[part 5 of 5: package /MICROSAR/Dem_swc/ComponentTypes]
AUTOSAR XML (schema 4-2-1)
package /MICROSAR/Dem_swc/ComponentTypes  (continued)
  service sw component type DemSatellite_OsApplication_Untrusted_Core0: category=SERVICE_COMPONENT  (continued)
    behavior DemSatellite_OsApplication_Untrusted_Core0InternalBehavior: handle-termination-and-restart=NO-SUPPORT, included-data-type-set=data-type=[Dem_EventIdType, Dem_RatioIdType, Dem_EventStatusType, Dem_UdsStatusByteType, Dem_DTCFormatType, Dem_InitMonitorReasonType, Dem_OperationCycleStateType, Dem_DTCStatusMaskType, Dem_IndicatorStatusType, Dem_MaxDataValueType, Dem_DTCKindType, Dem_DTCGroupType, Dem_IumprDenomCondIdType, Dem_IumprDenomCondStatusType, Dem_DebounceResetStatusType, Dem_DebouncingStateType, Dem_IumprReadinessGroupType, Dem_DTRControlType, Dem_DTCSeverityType, Dem_MonitorStatusType]  (continued)
      2354 x operation invoked event:  (continued)
        OpEventGetDebouncingOfEvent_GetDebouncingOfEvent_EvtInfo_AutoCreatedDemEvent_ESH_Action_ComMAllow_CN_LIN04_2bb463c6_Bsw_46c98e12: start-on-event=DemSatellite_OsApplication_Untrusted_Core0InternalBehavior/GetDebouncingOfEvent, operation=EvtInfo_AutoCreatedDemEvent_ESH_Action_ComMAllow_CN_LIN04_2bb463c6_BswMReportFailToDemRef.GetDebouncingOfEvent
        OpEventGetDebouncingOfEvent_GetDebouncingOfEvent_EvtInfo_AutoCreatedDemEvent_ESH_Action_ComMAllow_CN_LIN04_2bb463c6_Bsw_5fd0cb63: start-on-event=DemSatellite_OsApplication_Untrusted_Core0InternalBehavior/GetDebouncingOfEvent, operation=EvtInfo_AutoCreatedDemEvent_ESH_Action_ComMAllow_CN_LIN04_2bb463c6_BswMReportFailToDemRef_1.GetDebouncingOfEvent
        OpEventGetDebouncingOfEvent_GetDebouncingOfEvent_EvtInfo_AutoCreatedDemEvent_ESH_Action_ComMAllow_CN_SecuritySubnet_e7a_5c59b770: start-on-event=DemSatellite_OsApplication_Untrusted_Core0InternalBehavior/GetDebouncingOfEvent, operation=EvtInfo_AutoCreatedDemEvent_ESH_Action_ComMAllow_CN_SecuritySubnet_e7a0ee54_BswMReportFailToDemRef.GetDebouncingOfEvent
        OpEventGetDebouncingOfEvent_GetDebouncingOfEvent_EvtInfo_AutoCreatedDemEvent_ESH_Action_ComMAllow_CN_SecuritySubnet_e7a_571e50de: start-on-event=DemSatellite_OsApplication_Untrusted_Core0InternalBehavior/GetDebouncingOfEvent, operation=EvtInfo_AutoCreatedDemEvent_ESH_Action_ComMAllow_CN_SecuritySubnet_e7a0ee54_BswMReportFailToDemRef_1.GetDebouncingOfEvent
        OpEventGetDebouncingOfEvent_GetDebouncingOfEvent_EvtInfo_AutoCreatedDemEvent_ESH_Action_ComMCheckPendingRequests_BswMRe_1e2bc029: start-on-event=DemSatellite_OsApplication_Untrusted_Core0InternalBehavior/GetDebouncingOfEvent, operation=EvtInfo_AutoCreatedDemEvent_ESH_Action_ComMCheckPendingRequests_BswMReportFailToDemRef_1.GetDebouncingOfEvent
        OpEventGetDebouncingOfEvent_GetDebouncingOfEvent_EvtInfo_AutoCreatedDemEvent_ESH_Action_ComMCheckPendingRequests_BswMRe_87229193: start-on-event=DemSatellite_OsApplication_Untrusted_Core0InternalBehavior/GetDebouncingOfEvent, operation=EvtInfo_AutoCreatedDemEvent_ESH_Action_ComMCheckPendingRequests_BswMReportFailToDemRef_2.GetDebouncingOfEvent
        OpEventGetDebouncingOfEvent_GetDebouncingOfEvent_EvtInfo_AutoCreatedDemEvent_ESH_Action_ComMDisallow_CN_Backbone1J1939_2d2aa7ff: start-on-event=DemSatellite_OsApplication_Untrusted_Core0InternalBehavior/GetDebouncingOfEvent, operation=EvtInfo_AutoCreatedDemEvent_ESH_Action_ComMDisallow_CN_Backbone1J1939_0b1f4bae_BswMReportFailToDemRef.GetDebouncingOfEvent
        OpEventGetDebouncingOfEvent_GetDebouncingOfEvent_EvtInfo_AutoCreatedDemEvent_ESH_Action_ComMDisallow_CN_Backbone2_78967_78b51993: start-on-event=DemSatellite_OsApplication_Untrusted_Core0InternalBehavior/GetDebouncingOfEvent, operation=EvtInfo_AutoCreatedDemEvent_ESH_Action_ComMDisallow_CN_Backbone2_78967e2c_BswMReportFailToDemRef.GetDebouncingOfEvent
        OpEventGetDebouncingOfEvent_GetDebouncingOfEvent_EvtInfo_AutoCreatedDemEvent_ESH_Action_ComMDisallow_CN_CabSubnet_9ea69_a5772fe5: start-on-event=DemSatellite_OsApplication_Untrusted_Core0InternalBehavior/GetDebouncingOfEvent, operation=EvtInfo_AutoCreatedDemEvent_ESH_Action_ComMDisallow_CN_CabSubnet_9ea693f1_BswMReportFailToDemRef.GetDebouncingOfEvent
        OpEventGetDebouncingOfEvent_GetDebouncingOfEvent_EvtInfo_AutoCreatedDemEvent_ESH_Action_ComMDisallow_CN_FMSNet_fce1aae5_14cbd03a: start-on-event=DemSatellite_OsApplication_Untrusted_Core0InternalBehavior/GetDebouncingOfEvent, operation=EvtInfo_AutoCreatedDemEvent_ESH_Action_ComMDisallow_CN_FMSNet_fce1aae5_BswMReportFailToDemRef.GetDebouncingOfEvent
        OpEventGetDebouncingOfEvent_GetDebouncingOfEvent_EvtInfo_AutoCreatedDemEvent_ESH_Action_ComMDisallow_CN_LIN00_2cd9a7df_fbfb2a86: start-on-event=DemSatellite_OsApplication_Untrusted_Core0InternalBehavior/GetDebouncingOfEvent, operation=EvtInfo_AutoCreatedDemEvent_ESH_Action_ComMDisallow_CN_LIN00_2cd9a7df_BswMReportFailToDemRef.GetDebouncingOfEvent
        OpEventGetDebouncingOfEvent_GetDebouncingOfEvent_EvtInfo_AutoCreatedDemEvent_ESH_Action_ComMDisallow_CN_LIN01_5bde9749_c34bad5a: start-on-event=DemSatellite_OsApplication_Untrusted_Core0InternalBehavior/GetDebouncingOfEvent, operation=EvtInfo_AutoCreatedDemEvent_ESH_Action_ComMDisallow_CN_LIN01_5bde9749_BswMReportFailToDemRef.GetDebouncingOfEvent
        OpEventGetDebouncingOfEvent_GetDebouncingOfEvent_EvtInfo_AutoCreatedDemEvent_ESH_Action_ComMDisallow_CN_LIN02_c2d7c6f3_3e36513e: start-on-event=DemSatellite_OsApplication_Untrusted_Core0InternalBehavior/GetDebouncingOfEvent, operation=EvtInfo_AutoCreatedDemEvent_ESH_Action_ComMDisallow_CN_LIN02_c2d7c6f3_BswMReportFailToDemRef.GetDebouncingOfEvent
        OpEventGetDebouncingOfEvent_GetDebouncingOfEvent_EvtInfo_AutoCreatedDemEvent_ESH_Action_ComMDisallow_CN_LIN03_b5d0f665_ebc2edb4: start-on-event=DemSatellite_OsApplication_Untrusted_Core0InternalBehavior/GetDebouncingOfEvent, operation=EvtInfo_AutoCreatedDemEvent_ESH_Action_ComMDisallow_CN_LIN03_b5d0f665_BswMReportFailToDemRef.GetDebouncingOfEvent
        OpEventGetDebouncingOfEvent_GetDebouncingOfEvent_EvtInfo_AutoCreatedDemEvent_ESH_Action_ComMDisallow_CN_LIN04_2bb463c6_148c1262: start-on-event=DemSatellite_OsApplication_Untrusted_Core0InternalBehavior/GetDebouncingOfEvent, operation=EvtInfo_AutoCreatedDemEvent_ESH_Action_ComMDisallow_CN_LIN04_2bb463c6_BswMReportFailToDemRef.GetDebouncingOfEvent
        OpEventGetDebouncingOfEvent_GetDebouncingOfEvent_EvtInfo_AutoCreatedDemEvent_ESH_Action_ComMDisallow_CN_SecuritySubnet_83a02639: start-on-event=DemSatellite_OsApplication_Untrusted_Core0InternalBehavior/GetDebouncingOfEvent, operation=EvtInfo_AutoCreatedDemEvent_ESH_Action_ComMDisallow_CN_SecuritySubnet_e7a0ee54_BswMReportFailToDemRef.GetDebouncingOfEvent
        OpEventGetDebouncingOfEvent_GetDebouncingOfEvent_EvtInfo_AutoCreatedDemEvent_ESH_Action_DemInit_BswMReportFailToDemRef: start-on-event=DemSatellite_OsApplication_Untrusted_Core0InternalBehavior/GetDebouncingOfEvent, operation=EvtInfo_AutoCreatedDemEvent_ESH_Action_DemInit_BswMReportFailToDemRef.GetDebouncingOfEvent
        OpEventGetDebouncingOfEvent_GetDebouncingOfEvent_EvtInfo_AutoCreatedDemEvent_ESH_Action_DemInitialized_BswMReportFailToDemRef: start-on-event=DemSatellite_OsApplication_Untrusted_Core0InternalBehavior/GetDebouncingOfEvent, operation=EvtInfo_AutoCreatedDemEvent_ESH_Action_DemInitialized_BswMReportFailToDemRef.GetDebouncingOfEvent
        OpEventGetDebouncingOfEvent_GetDebouncingOfEvent_EvtInfo_AutoCreatedDemEvent_ESH_Action_DemNotInitialized_BswMReportFailToDemRef: start-on-event=DemSatellite_OsApplication_Untrusted_Core0InternalBehavior/GetDebouncingOfEvent, operation=EvtInfo_AutoCreatedDemEvent_ESH_Action_DemNotInitialized_BswMReportFailToDemRef.GetDebouncingOfEvent
        OpEventGetDebouncingOfEvent_GetDebouncingOfEvent_EvtInfo_AutoCreatedDemEvent_ESH_Action_DemShutdown_BswMReportFailToDemRef: start-on-event=DemSatellite_OsApplication_Untrusted_Core0InternalBehavior/GetDebouncingOfEvent, operation=EvtInfo_AutoCreatedDemEvent_ESH_Action_DemShutdown_BswMReportFailToDemRef.GetDebouncingOfEvent
        OpEventGetDebouncingOfEvent_GetDebouncingOfEvent_EvtInfo_AutoCreatedDemEvent_ESH_Action_ESH_PostRun_BswMReportFailToDemRef: start-on-event=DemSatellite_OsApplication_Untrusted_Core0InternalBehavior/GetDebouncingOfEvent, operation=EvtInfo_AutoCreatedDemEvent_ESH_Action_ESH_PostRun_BswMReportFailToDemRef.GetDebouncingOfEvent
        OpEventGetDebouncingOfEvent_GetDebouncingOfEvent_EvtInfo_AutoCreatedDemEvent_ESH_Action_ESH_PrepShutdown_BswMReportFailToDemRef: start-on-event=DemSatellite_OsApplication_Untrusted_Core0InternalBehavior/GetDebouncingOfEvent, operation=EvtInfo_AutoCreatedDemEvent_ESH_Action_ESH_PrepShutdown_BswMReportFailToDemRef.GetDebouncingOfEvent
        OpEventGetDebouncingOfEvent_GetDebouncingOfEvent_EvtInfo_AutoCreatedDemEvent_ESH_Action_ESH_PrepShutdown_BswMReportFail_db47bce3: start-on-event=DemSatellite_OsApplication_Untrusted_Core0InternalBehavior/GetDebouncingOfEvent, operation=EvtInfo_AutoCreatedDemEvent_ESH_Action_ESH_PrepShutdown_BswMReportFailToDemRef_1.GetDebouncingOfEvent
        OpEventGetDebouncingOfEvent_GetDebouncingOfEvent_EvtInfo_AutoCreatedDemEvent_ESH_Action_ESH_Run_BswMReportFailToDemRef: start-on-event=DemSatellite_OsApplication_Untrusted_Core0InternalBehavior/GetDebouncingOfEvent, operation=EvtInfo_AutoCreatedDemEvent_ESH_Action_ESH_Run_BswMReportFailToDemRef.GetDebouncingOfEvent
        OpEventGetDebouncingOfEvent_GetDebouncingOfEvent_EvtInfo_AutoCreatedDemEvent_ESH_Action_ESH_Run_BswMReportFailToDemRef_1: start-on-event=DemSatellite_OsApplication_Untrusted_Core0InternalBehavior/GetDebouncingOfEvent, operation=EvtInfo_AutoCreatedDemEvent_ESH_Action_ESH_Run_BswMReportFailToDemRef_1.GetDebouncingOfEvent
        OpEventGetDebouncingOfEvent_GetDebouncingOfEvent_EvtInfo_AutoCreatedDemEvent_ESH_Action_ESH_WaitForNvm_BswMReportFailToDemRef: start-on-event=DemSatellite_OsApplication_Untrusted_Core0InternalBehavior/GetDebouncingOfEvent, operation=EvtInfo_AutoCreatedDemEvent_ESH_Action_ESH_WaitForNvm_BswMReportFailToDemRef.GetDebouncingOfEvent
        OpEventGetDebouncingOfEvent_GetDebouncingOfEvent_EvtInfo_AutoCreatedDemEvent_ESH_Action_ESH_Wakeup_BswMReportFailToDemRef: start-on-event=DemSatellite_OsApplication_Untrusted_Core0InternalBehavior/GetDebouncingOfEvent, operation=EvtInfo_AutoCreatedDemEvent_ESH_Action_ESH_Wakeup_BswMReportFailToDemRef.GetDebouncingOfEvent
        OpEventGetDebouncingOfEvent_GetDebouncingOfEvent_EvtInfo_AutoCreatedDemEvent_ESH_Action_ESH_Wakeup_BswMReportFailToDemRef_1: start-on-event=DemSatellite_OsApplication_Untrusted_Core0InternalBehavior/GetDebouncingOfEvent, operation=EvtInfo_AutoCreatedDemEvent_ESH_Action_ESH_Wakeup_BswMReportFailToDemRef_1.GetDebouncingOfEvent
        OpEventGetDebouncingOfEvent_GetDebouncingOfEvent_EvtInfo_AutoCreatedDemEvent_ESH_Action_EcuMClearValidatedWakeupEvents_f2dc5f13: start-on-event=DemSatellite_OsApplication_Untrusted_Core0InternalBehavior/GetDebouncingOfEvent, operation=EvtInfo_AutoCreatedDemEvent_ESH_Action_EcuMClearValidatedWakeupEvents_BswMReportFailToDemRef.GetDebouncingOfEvent
        OpEventGetDebouncingOfEvent_GetDebouncingOfEvent_EvtInfo_AutoCreatedDemEvent_ESH_Action_EcuMGoToSelectedShutdownTarget_5396efc5: start-on-event=DemSatellite_OsApplication_Untrusted_Core0InternalBehavior/GetDebouncingOfEvent, operation=EvtInfo_AutoCreatedDemEvent_ESH_Action_EcuMGoToSelectedShutdownTarget_BswMReportFailToDemRef.GetDebouncingOfEvent
        OpEventGetDebouncingOfEvent_GetDebouncingOfEvent_EvtInfo_AutoCreatedDemEvent_ESH_Action_EnterExclusiveArea_BswMReportFa_11cb58f1: start-on-event=DemSatellite_OsApplication_Untrusted_Core0InternalBehavior/GetDebouncingOfEvent, operation=EvtInfo_AutoCreatedDemEvent_ESH_Action_EnterExclusiveArea_BswMReportFailToDemRef_1.GetDebouncingOfEvent
        OpEventGetDebouncingOfEvent_GetDebouncingOfEvent_EvtInfo_AutoCreatedDemEvent_ESH_Action_ExitExclusiveArea_BswMReportFailToDemRef: start-on-event=DemSatellite_OsApplication_Untrusted_Core0InternalBehavior/GetDebouncingOfEvent, operation=EvtInfo_AutoCreatedDemEvent_ESH_Action_ExitExclusiveArea_BswMReportFailToDemRef.GetDebouncingOfEvent
        OpEventGetDebouncingOfEvent_GetDebouncingOfEvent_EvtInfo_AutoCreatedDemEvent_ESH_Action_NvMWriteAll_BswMReportFailToDemRef: start-on-event=DemSatellite_OsApplication_Untrusted_Core0InternalBehavior/GetDebouncingOfEvent, operation=EvtInfo_AutoCreatedDemEvent_ESH_Action_NvMWriteAll_BswMReportFailToDemRef.GetDebouncingOfEvent
        OpEventGetDebouncingOfEvent_GetDebouncingOfEvent_EvtInfo_AutoCreatedDemEvent_ESH_Action_OnEnterPostRun_BswMReportFailToDemRef: start-on-event=DemSatellite_OsApplication_Untrusted_Core0InternalBehavior/GetDebouncingOfEvent, operation=EvtInfo_AutoCreatedDemEvent_ESH_Action_OnEnterPostRun_BswMReportFailToDemRef.GetDebouncingOfEvent
        OpEventGetDebouncingOfEvent_GetDebouncingOfEvent_EvtInfo_AutoCreatedDemEvent_ESH_Action_OnEnterPrepShutdown_BswMReportF_d1914dd3: start-on-event=DemSatellite_OsApplication_Untrusted_Core0InternalBehavior/GetDebouncingOfEvent, operation=EvtInfo_AutoCreatedDemEvent_ESH_Action_OnEnterPrepShutdown_BswMReportFailToDemRef.GetDebouncingOfEvent
        OpEventGetDebouncingOfEvent_GetDebouncingOfEvent_EvtInfo_AutoCreatedDemEvent_ESH_Action_OnEnterPrepShutdown_BswMReportF_8f5c293e: start-on-event=DemSatellite_OsApplication_Untrusted_Core0InternalBehavior/GetDebouncingOfEvent, operation=EvtInfo_AutoCreatedDemEvent_ESH_Action_OnEnterPrepShutdown_BswMReportFailToDemRef_1.GetDebouncingOfEvent
        OpEventGetDebouncingOfEvent_GetDebouncingOfEvent_EvtInfo_AutoCreatedDemEvent_ESH_Action_OnEnterRun_BswMReportFailToDemRef: start-on-event=DemSatellite_OsApplication_Untrusted_Core0InternalBehavior/GetDebouncingOfEvent, operation=EvtInfo_AutoCreatedDemEvent_ESH_Action_OnEnterRun_BswMReportFailToDemRef.GetDebouncingOfEvent
        OpEventGetDebouncingOfEvent_GetDebouncingOfEvent_EvtInfo_AutoCreatedDemEvent_ESH_Action_OnEnterRun_BswMReportFailToDemRef_1: start-on-event=DemSatellite_OsApplication_Untrusted_Core0InternalBehavior/GetDebouncingOfEvent, operation=EvtInfo_AutoCreatedDemEvent_ESH_Action_OnEnterRun_BswMReportFailToDemRef_1.GetDebouncingOfEvent
        OpEventGetDebouncingOfEvent_GetDebouncingOfEvent_EvtInfo_AutoCreatedDemEvent_ESH_Action_OnEnterShutdown_BswMReportFailToDemRef: start-on-event=DemSatellite_OsApplication_Untrusted_Core0InternalBehavior/GetDebouncingOfEvent, operation=EvtInfo_AutoCreatedDemEvent_ESH_Action_OnEnterShutdown_BswMReportFailToDemRef.GetDebouncingOfEvent
        OpEventGetDebouncingOfEvent_GetDebouncingOfEvent_EvtInfo_AutoCreatedDemEvent_ESH_Action_OnEnterWaitForNvm_BswMReportFailToDemRef: start-on-event=DemSatellite_OsApplication_Untrusted_Core0InternalBehavior/GetDebouncingOfEvent, operation=EvtInfo_AutoCreatedDemEvent_ESH_Action_OnEnterWaitForNvm_BswMReportFailToDemRef.GetDebouncingOfEvent
        OpEventGetDebouncingOfEvent_GetDebouncingOfEvent_EvtInfo_AutoCreatedDemEvent_ESH_Action_OnEnterWakeup_BswMReportFailToDemRef: start-on-event=DemSatellite_OsApplication_Untrusted_Core0InternalBehavior/GetDebouncingOfEvent, operation=EvtInfo_AutoCreatedDemEvent_ESH_Action_OnEnterWakeup_BswMReportFailToDemRef.GetDebouncingOfEvent
        OpEventGetDebouncingOfEvent_GetDebouncingOfEvent_EvtInfo_AutoCreatedDemEvent_ESH_Action_OnEnterWakeup_BswMReportFailToDemRef_1: start-on-event=DemSatellite_OsApplication_Untrusted_Core0InternalBehavior/GetDebouncingOfEvent, operation=EvtInfo_AutoCreatedDemEvent_ESH_Action_OnEnterWakeup_BswMReportFailToDemRef_1.GetDebouncingOfEvent
        OpEventGetDebouncingOfEvent_GetDebouncingOfEvent_EvtInfo_AutoCreatedDemEvent_ESH_Action_SelfRunRequestTimer_Start_BswMR_aa492484: start-on-event=DemSatellite_OsApplication_Untrusted_Core0InternalBehavior/GetDebouncingOfEvent, operation=EvtInfo_AutoCreatedDemEvent_ESH_Action_SelfRunRequestTimer_Start_BswMReportFailToDemRef.GetDebouncingOfEvent
        OpEventGetDebouncingOfEvent_GetDebouncingOfEvent_EvtInfo_AutoCreatedDemEvent_ESH_Action_SelfRunRequestTimer_Start_BswMR_4ec84089: start-on-event=DemSatellite_OsApplication_Untrusted_Core0InternalBehavior/GetDebouncingOfEvent, operation=EvtInfo_AutoCreatedDemEvent_ESH_Action_SelfRunRequestTimer_Start_BswMReportFailToDemRef_1.GetDebouncingOfEvent
        OpEventGetDebouncingOfEvent_GetDebouncingOfEvent_EvtInfo_AutoCreatedDemEvent_ESH_Action_SwitchPostRun_BswMReportFailToDemRef: start-on-event=DemSatellite_OsApplication_Untrusted_Core0InternalBehavior/GetDebouncingOfEvent, operation=EvtInfo_AutoCreatedDemEvent_ESH_Action_SwitchPostRun_BswMReportFailToDemRef.GetDebouncingOfEvent
        OpEventGetDebouncingOfEvent_GetDebouncingOfEvent_EvtInfo_AutoCreatedDemEvent_ESH_Action_SwitchRun_BswMReportFailToDemRef: start-on-event=DemSatellite_OsApplication_Untrusted_Core0InternalBehavior/GetDebouncingOfEvent, operation=EvtInfo_AutoCreatedDemEvent_ESH_Action_SwitchRun_BswMReportFailToDemRef.GetDebouncingOfEvent
        OpEventGetDebouncingOfEvent_GetDebouncingOfEvent_EvtInfo_AutoCreatedDemEvent_ESH_Action_SwitchRun_BswMReportFailToDemRef_1: start-on-event=DemSatellite_OsApplication_Untrusted_Core0InternalBehavior/GetDebouncingOfEvent, operation=EvtInfo_AutoCreatedDemEvent_ESH_Action_SwitchRun_BswMReportFailToDemRef_1.GetDebouncingOfEvent
        OpEventGetDebouncingOfEvent_GetDebouncingOfEvent_EvtInfo_AutoCreatedDemEvent_ESH_Action_SwitchShutdown_BswMReportFailToDemRef: start-on-event=DemSatellite_OsApplication_Untrusted_Core0InternalBehavior/GetDebouncingOfEvent, operation=EvtInfo_AutoCreatedDemEvent_ESH_Action_SwitchShutdown_BswMReportFailToDemRef.GetDebouncingOfEvent
        OpEventGetDebouncingOfEvent_GetDebouncingOfEvent_EvtInfo_AutoCreatedDemEvent_ESH_Action_SwitchShutdown_BswMReportFailToDemRef_1: start-on-event=DemSatellite_OsApplication_Untrusted_Core0InternalBehavior/GetDebouncingOfEvent, operation=EvtInfo_AutoCreatedDemEvent_ESH_Action_SwitchShutdown_BswMReportFailToDemRef_1.GetDebouncingOfEvent
        OpEventGetDebouncingOfEvent_GetDebouncingOfEvent_EvtInfo_AutoCreatedDemEvent_ESH_Action_SwitchWakeup_BswMReportFailToDemRef: start-on-event=DemSatellite_OsApplication_Untrusted_Core0InternalBehavior/GetDebouncingOfEvent, operation=EvtInfo_AutoCreatedDemEvent_ESH_Action_SwitchWakeup_BswMReportFailToDemRef.GetDebouncingOfEvent
        OpEventGetDebouncingOfEvent_GetDebouncingOfEvent_EvtInfo_AutoCreatedDemEvent_ESH_Action_SwitchWakeup_BswMReportFailToDemRef_1: start-on-event=DemSatellite_OsApplication_Untrusted_Core0InternalBehavior/GetDebouncingOfEvent, operation=EvtInfo_AutoCreatedDemEvent_ESH_Action_SwitchWakeup_BswMReportFailToDemRef_1.GetDebouncingOfEvent
        OpEventGetDebouncingOfEvent_GetDebouncingOfEvent_EvtInfo_AutoCreatedDemEvent_ESH_Action_WriteAllTimer_Start_BswMReportF_e91d4dd9: start-on-event=DemSatellite_OsApplication_Untrusted_Core0InternalBehavior/GetDebouncingOfEvent, operation=EvtInfo_AutoCreatedDemEvent_ESH_Action_WriteAllTimer_Start_BswMReportFailToDemRef.GetDebouncingOfEvent
        OpEventGetDebouncingOfEvent_GetDebouncingOfEvent_EvtInfo_AutoCreatedDemEvent_ESH_Action_WriteAllTimer_Stop_BswMReportFa_395e4e56: start-on-event=DemSatellite_OsApplication_Untrusted_Core0InternalBehavior/GetDebouncingOfEvent, operation=EvtInfo_AutoCreatedDemEvent_ESH_Action_WriteAllTimer_Stop_BswMReportFailToDemRef.GetDebouncingOfEvent
        OpEventGetDebouncingOfEvent_GetDebouncingOfEvent_EvtInfo_AutoCreatedDemEvent_ESH_Action_WriteAllTimer_Stop_BswMReportFa_50a1fc45: start-on-event=DemSatellite_OsApplication_Untrusted_Core0InternalBehavior/GetDebouncingOfEvent, operation=EvtInfo_AutoCreatedDemEvent_ESH_Action_WriteAllTimer_Stop_BswMReportFailToDemRef_1.GetDebouncingOfEvent
        OpEventGetDebouncingOfEvent_GetDebouncingOfEvent_EvtInfo_AutoCreatedDemEvent_ESH_DemInit_BswMReportFailToDemRef: start-on-event=DemSatellite_OsApplication_Untrusted_Core0InternalBehavior/GetDebouncingOfEvent, operation=EvtInfo_AutoCreatedDemEvent_ESH_DemInit_BswMReportFailToDemRef.GetDebouncingOfEvent
        OpEventGetDebouncingOfEvent_GetDebouncingOfEvent_EvtInfo_AutoCreatedDemEvent_ESH_PostRunNested_BswMReportFailToDemRef: start-on-event=DemSatellite_OsApplication_Untrusted_Core0InternalBehavior/GetDebouncingOfEvent, operation=EvtInfo_AutoCreatedDemEvent_ESH_PostRunNested_BswMReportFailToDemRef.GetDebouncingOfEvent
        OpEventGetDebouncingOfEvent_GetDebouncingOfEvent_EvtInfo_AutoCreatedDemEvent_ESH_PostRunToPrepNested_BswMReportFailToDemRef: start-on-event=DemSatellite_OsApplication_Untrusted_Core0InternalBehavior/GetDebouncingOfEvent, operation=EvtInfo_AutoCreatedDemEvent_ESH_PostRunToPrepNested_BswMReportFailToDemRef.GetDebouncingOfEvent
        OpEventGetDebouncingOfEvent_GetDebouncingOfEvent_EvtInfo_AutoCreatedDemEvent_ESH_Action_ExitExclusiveArea_BswMReportFai_5d1927bc: start-on-event=DemSatellite_OsApplication_Untrusted_Core0InternalBehavior/GetDebouncingOfEvent, operation=EvtInfo_AutoCreatedDemEvent_ESH_Action_ExitExclusiveArea_BswMReportFailToDemRef_1.GetDebouncingOfEvent
        OpEventGetDebouncingOfEvent_GetDebouncingOfEvent_EvtInfo_AutoCreatedDemEvent_INIT_Action_BrsHw_EnableHwAccess_BswMRepor_03983a55: start-on-event=DemSatellite_OsApplication_Untrusted_Core0InternalBehavior/GetDebouncingOfEvent, operation=EvtInfo_AutoCreatedDemEvent_INIT_Action_BrsHw_EnableHwAccess_BswMReportFailToDemRef.GetDebouncingOfEvent
        OpEventGetDebouncingOfEvent_GetDebouncingOfEvent_EvtInfo_AutoCreatedDemEvent_INIT_Action_CanIf_Init_BswMReportFailToDemRef: start-on-event=DemSatellite_OsApplication_Untrusted_Core0InternalBehavior/GetDebouncingOfEvent, operation=EvtInfo_AutoCreatedDemEvent_INIT_Action_CanIf_Init_BswMReportFailToDemRef.GetDebouncingOfEvent
        OpEventGetDebouncingOfEvent_GetDebouncingOfEvent_EvtInfo_AutoCreatedDemEvent_INIT_Action_CanNm_Init_BswMReportFailToDemRef: start-on-event=DemSatellite_OsApplication_Untrusted_Core0InternalBehavior/GetDebouncingOfEvent, operation=EvtInfo_AutoCreatedDemEvent_INIT_Action_CanNm_Init_BswMReportFailToDemRef.GetDebouncingOfEvent
        OpEventGetDebouncingOfEvent_GetDebouncingOfEvent_EvtInfo_AutoCreatedDemEvent_INIT_Action_CanSM_Init_BswMReportFailToDemRef: start-on-event=DemSatellite_OsApplication_Untrusted_Core0InternalBehavior/GetDebouncingOfEvent, operation=EvtInfo_AutoCreatedDemEvent_INIT_Action_CanSM_Init_BswMReportFailToDemRef.GetDebouncingOfEvent
        OpEventGetDebouncingOfEvent_GetDebouncingOfEvent_EvtInfo_AutoCreatedDemEvent_INIT_Action_CanTp_Init_BswMReportFailToDemRef: start-on-event=DemSatellite_OsApplication_Untrusted_Core0InternalBehavior/GetDebouncingOfEvent, operation=EvtInfo_AutoCreatedDemEvent_INIT_Action_CanTp_Init_BswMReportFailToDemRef.GetDebouncingOfEvent
        OpEventGetDebouncingOfEvent_GetDebouncingOfEvent_EvtInfo_AutoCreatedDemEvent_INIT_Action_Can_Init_BswMReportFailToDemRef: start-on-event=DemSatellite_OsApplication_Untrusted_Core0InternalBehavior/GetDebouncingOfEvent, operation=EvtInfo_AutoCreatedDemEvent_INIT_Action_Can_Init_BswMReportFailToDemRef.GetDebouncingOfEvent
        OpEventGetDebouncingOfEvent_GetDebouncingOfEvent_EvtInfo_AutoCreatedDemEvent_INIT_Action_ComM_Init_BswMReportFailToDemRef: start-on-event=DemSatellite_OsApplication_Untrusted_Core0InternalBehavior/GetDebouncingOfEvent, operation=EvtInfo_AutoCreatedDemEvent_INIT_Action_ComM_Init_BswMReportFailToDemRef.GetDebouncingOfEvent
        OpEventGetDebouncingOfEvent_GetDebouncingOfEvent_EvtInfo_AutoCreatedDemEvent_INIT_Action_Com_Init_BswMReportFailToDemRef: start-on-event=DemSatellite_OsApplication_Untrusted_Core0InternalBehavior/GetDebouncingOfEvent, operation=EvtInfo_AutoCreatedDemEvent_INIT_Action_Com_Init_BswMReportFailToDemRef.GetDebouncingOfEvent
        OpEventGetDebouncingOfEvent_GetDebouncingOfEvent_EvtInfo_AutoCreatedDemEvent_INIT_Action_Dcm_Init_BswMReportFailToDemRef: start-on-event=DemSatellite_OsApplication_Untrusted_Core0InternalBehavior/GetDebouncingOfEvent, operation=EvtInfo_AutoCreatedDemEvent_INIT_Action_Dcm_Init_BswMReportFailToDemRef.GetDebouncingOfEvent
        OpEventGetDebouncingOfEvent_GetDebouncingOfEvent_EvtInfo_AutoCreatedDemEvent_INIT_Action_Dem_Init_BswMReportFailToDemRef: start-on-event=DemSatellite_OsApplication_Untrusted_Core0InternalBehavior/GetDebouncingOfEvent, operation=EvtInfo_AutoCreatedDemEvent_INIT_Action_Dem_Init_BswMReportFailToDemRef.GetDebouncingOfEvent
        OpEventGetDebouncingOfEvent_GetDebouncingOfEvent_EvtInfo_AutoCreatedDemEvent_INIT_Action_EnableInterrupts_BswMReportFailToDemRef: start-on-event=DemSatellite_OsApplication_Untrusted_Core0InternalBehavior/GetDebouncingOfEvent, operation=EvtInfo_AutoCreatedDemEvent_INIT_Action_EnableInterrupts_BswMReportFailToDemRef.GetDebouncingOfEvent
        OpEventGetDebouncingOfEvent_GetDebouncingOfEvent_EvtInfo_AutoCreatedDemEvent_INIT_Action_Fee_Init_BswMReportFailToDemRef: start-on-event=DemSatellite_OsApplication_Untrusted_Core0InternalBehavior/GetDebouncingOfEvent, operation=EvtInfo_AutoCreatedDemEvent_INIT_Action_Fee_Init_BswMReportFailToDemRef.GetDebouncingOfEvent
        OpEventGetDebouncingOfEvent_GetDebouncingOfEvent_EvtInfo_AutoCreatedDemEvent_INIT_Action_Issm_Init_BswMReportFailToDemRef: start-on-event=DemSatellite_OsApplication_Untrusted_Core0InternalBehavior/GetDebouncingOfEvent, operation=EvtInfo_AutoCreatedDemEvent_INIT_Action_Issm_Init_BswMReportFailToDemRef.GetDebouncingOfEvent
        OpEventGetDebouncingOfEvent_GetDebouncingOfEvent_EvtInfo_AutoCreatedDemEvent_INIT_Action_J1939Nm_Init_BswMReportFailToDemRef: start-on-event=DemSatellite_OsApplication_Untrusted_Core0InternalBehavior/GetDebouncingOfEvent, operation=EvtInfo_AutoCreatedDemEvent_INIT_Action_J1939Nm_Init_BswMReportFailToDemRef.GetDebouncingOfEvent
        OpEventGetDebouncingOfEvent_GetDebouncingOfEvent_EvtInfo_AutoCreatedDemEvent_INIT_Action_J1939Rm_Init_BswMReportFailToDemRef: start-on-event=DemSatellite_OsApplication_Untrusted_Core0InternalBehavior/GetDebouncingOfEvent, operation=EvtInfo_AutoCreatedDemEvent_INIT_Action_J1939Rm_Init_BswMReportFailToDemRef.GetDebouncingOfEvent
        OpEventGetDebouncingOfEvent_GetDebouncingOfEvent_EvtInfo_AutoCreatedDemEvent_INIT_Action_J1939Tp_Init_BswMReportFailToDemRef: start-on-event=DemSatellite_OsApplication_Untrusted_Core0InternalBehavior/GetDebouncingOfEvent, operation=EvtInfo_AutoCreatedDemEvent_INIT_Action_J1939Tp_Init_BswMReportFailToDemRef.GetDebouncingOfEvent
        OpEventGetDebouncingOfEvent_GetDebouncingOfEvent_EvtInfo_AutoCreatedDemEvent_INIT_Action_LinIf_Init_BswMReportFailToDemRef: start-on-event=DemSatellite_OsApplication_Untrusted_Core0InternalBehavior/GetDebouncingOfEvent, operation=EvtInfo_AutoCreatedDemEvent_INIT_Action_LinIf_Init_BswMReportFailToDemRef.GetDebouncingOfEvent
        OpEventGetDebouncingOfEvent_GetDebouncingOfEvent_EvtInfo_AutoCreatedDemEvent_INIT_Action_LinSM_Init_BswMReportFailToDemRef: start-on-event=DemSatellite_OsApplication_Untrusted_Core0InternalBehavior/GetDebouncingOfEvent, operation=EvtInfo_AutoCreatedDemEvent_INIT_Action_LinSM_Init_BswMReportFailToDemRef.GetDebouncingOfEvent
        OpEventGetDebouncingOfEvent_GetDebouncingOfEvent_EvtInfo_AutoCreatedDemEvent_INIT_Action_LinTp_Init_BswMReportFailToDemRef: start-on-event=DemSatellite_OsApplication_Untrusted_Core0InternalBehavior/GetDebouncingOfEvent, operation=EvtInfo_AutoCreatedDemEvent_INIT_Action_LinTp_Init_BswMReportFailToDemRef.GetDebouncingOfEvent
        OpEventGetDebouncingOfEvent_GetDebouncingOfEvent_EvtInfo_AutoCreatedDemEvent_INIT_Action_Lin_Init_BswMReportFailToDemRef: start-on-event=DemSatellite_OsApplication_Untrusted_Core0InternalBehavior/GetDebouncingOfEvent, operation=EvtInfo_AutoCreatedDemEvent_INIT_Action_Lin_Init_BswMReportFailToDemRef.GetDebouncingOfEvent
        OpEventGetDebouncingOfEvent_GetDebouncingOfEvent_EvtInfo_AutoCreatedDemEvent_INIT_Action_Nm_Init_BswMReportFailToDemRef: start-on-event=DemSatellite_OsApplication_Untrusted_Core0InternalBehavior/GetDebouncingOfEvent, operation=EvtInfo_AutoCreatedDemEvent_INIT_Action_Nm_Init_BswMReportFailToDemRef.GetDebouncingOfEvent
        OpEventGetDebouncingOfEvent_GetDebouncingOfEvent_EvtInfo_AutoCreatedDemEvent_INIT_Action_NvMReadAll_BswMReportFailToDemRef: start-on-event=DemSatellite_OsApplication_Untrusted_Core0InternalBehavior/GetDebouncingOfEvent, operation=EvtInfo_AutoCreatedDemEvent_INIT_Action_NvMReadAll_BswMReportFailToDemRef.GetDebouncingOfEvent
        OpEventGetDebouncingOfEvent_GetDebouncingOfEvent_EvtInfo_AutoCreatedDemEvent_INIT_Action_NvM_Init_BswMReportFailToDemRef: start-on-event=DemSatellite_OsApplication_Untrusted_Core0InternalBehavior/GetDebouncingOfEvent, operation=EvtInfo_AutoCreatedDemEvent_INIT_Action_NvM_Init_BswMReportFailToDemRef.GetDebouncingOfEvent
        OpEventGetDebouncingOfEvent_GetDebouncingOfEvent_EvtInfo_AutoCreatedDemEvent_INIT_Action_PduR_Init_BswMReportFailToDemRef: start-on-event=DemSatellite_OsApplication_Untrusted_Core0InternalBehavior/GetDebouncingOfEvent, operation=EvtInfo_AutoCreatedDemEvent_INIT_Action_PduR_Init_BswMReportFailToDemRef.GetDebouncingOfEvent
        OpEventGetDebouncingOfEvent_GetDebouncingOfEvent_EvtInfo_AutoCreatedDemEvent_INIT_Action_RteStart_BswMReportFailToDemRef: start-on-event=DemSatellite_OsApplication_Untrusted_Core0InternalBehavior/GetDebouncingOfEvent, operation=EvtInfo_AutoCreatedDemEvent_INIT_Action_RteStart_BswMReportFailToDemRef.GetDebouncingOfEvent
        OpEventGetDebouncingOfEvent_GetDebouncingOfEvent_EvtInfo_AutoCreatedDemEvent_CHNL_17344684_CANSM_E_MODE_REQUEST_TIMEOUT: start-on-event=DemSatellite_OsApplication_Untrusted_Core0InternalBehavior/GetDebouncingOfEvent, operation=EvtInfo_AutoCreatedDemEvent_CHNL_17344684_CANSM_E_MODE_REQUEST_TIMEOUT.GetDebouncingOfEvent
        OpEventGetDebouncingOfEvent_GetDebouncingOfEvent_EvtInfo_AutoCreatedDemEvent_CHNL_17344684_CANSM_E_BUS_OFF: start-on-event=DemSatellite_OsApplication_Untrusted_Core0InternalBehavior/GetDebouncingOfEvent, operation=EvtInfo_AutoCreatedDemEvent_CHNL_17344684_CANSM_E_BUS_OFF.GetDebouncingOfEvent
        OpEventGetDebouncingOfEvent_GetDebouncingOfEvent_EvtInfo_AutoCreatedDemEvent_CHNL_53cce282_CANSM_E_MODE_REQUEST_TIMEOUT: start-on-event=DemSatellite_OsApplication_Untrusted_Core0InternalBehavior/GetDebouncingOfEvent, operation=EvtInfo_AutoCreatedDemEvent_CHNL_53cce282_CANSM_E_MODE_REQUEST_TIMEOUT.GetDebouncingOfEvent
        OpEventGetDebouncingOfEvent_GetDebouncingOfEvent_EvtInfo_AutoCreatedDemEvent_CHNL_53cce282_CANSM_E_BUS_OFF: start-on-event=DemSatellite_OsApplication_Untrusted_Core0InternalBehavior/GetDebouncingOfEvent, operation=EvtInfo_AutoCreatedDemEvent_CHNL_53cce282_CANSM_E_BUS_OFF.GetDebouncingOfEvent
        OpEventGetDebouncingOfEvent_GetDebouncingOfEvent_EvtInfo_AutoCreatedDemEvent_CHNL_a6b6a922_CANSM_E_MODE_REQUEST_TIMEOUT: start-on-event=DemSatellite_OsApplication_Untrusted_Core0InternalBehavior/GetDebouncingOfEvent, operation=EvtInfo_AutoCreatedDemEvent_CHNL_a6b6a922_CANSM_E_MODE_REQUEST_TIMEOUT.GetDebouncingOfEvent
        OpEventGetDebouncingOfEvent_GetDebouncingOfEvent_EvtInfo_AutoCreatedDemEvent_CHNL_a6b6a922_CANSM_E_BUS_OFF: start-on-event=DemSatellite_OsApplication_Untrusted_Core0InternalBehavior/GetDebouncingOfEvent, operation=EvtInfo_AutoCreatedDemEvent_CHNL_a6b6a922_CANSM_E_BUS_OFF.GetDebouncingOfEvent
        OpEventGetDebouncingOfEvent_GetDebouncingOfEvent_EvtInfo_AutoCreatedDemEvent_CHNL_df893ad5_CANSM_E_MODE_REQUEST_TIMEOUT: start-on-event=DemSatellite_OsApplication_Untrusted_Core0InternalBehavior/GetDebouncingOfEvent, operation=EvtInfo_AutoCreatedDemEvent_CHNL_df893ad5_CANSM_E_MODE_REQUEST_TIMEOUT.GetDebouncingOfEvent
        OpEventGetDebouncingOfEvent_GetDebouncingOfEvent_EvtInfo_AutoCreatedDemEvent_CHNL_df893ad5_CANSM_E_BUS_OFF: start-on-event=DemSatellite_OsApplication_Untrusted_Core0InternalBehavior/GetDebouncingOfEvent, operation=EvtInfo_AutoCreatedDemEvent_CHNL_df893ad5_CANSM_E_BUS_OFF.GetDebouncingOfEvent
        OpEventGetDebouncingOfEvent_GetDebouncingOfEvent_EvtInfo_AutoCreatedDemEvent_CHNL_e058b4ae_CANSM_E_MODE_REQUEST_TIMEOUT: start-on-event=DemSatellite_OsApplication_Untrusted_Core0InternalBehavior/GetDebouncingOfEvent, operation=EvtInfo_AutoCreatedDemEvent_CHNL_e058b4ae_CANSM_E_MODE_REQUEST_TIMEOUT.GetDebouncingOfEvent
        OpEventGetDebouncingOfEvent_GetDebouncingOfEvent_EvtInfo_AutoCreatedDemEvent_CHNL_e058b4ae_CANSM_E_BUS_OFF: start-on-event=DemSatellite_OsApplication_Untrusted_Core0InternalBehavior/GetDebouncingOfEvent, operation=EvtInfo_AutoCreatedDemEvent_CHNL_e058b4ae_CANSM_E_BUS_OFF.GetDebouncingOfEvent
        OpEventGetDebouncingOfEvent_GetDebouncingOfEvent_EvtInfo_AutoCreatedDemEvent_ECUM_E_RAM_CHECK_FAILED: start-on-event=DemSatellite_OsApplication_Untrusted_Core0InternalBehavior/GetDebouncingOfEvent, operation=EvtInfo_AutoCreatedDemEvent_ECUM_E_RAM_CHECK_FAILED.GetDebouncingOfEvent
        OpEventGetDebouncingOfEvent_GetDebouncingOfEvent_EvtInfo_AutoCreatedDemEvent_ECUM_E_IMPROPER_CALLER: start-on-event=DemSatellite_OsApplication_Untrusted_Core0InternalBehavior/GetDebouncingOfEvent, operation=EvtInfo_AutoCreatedDemEvent_ECUM_E_IMPROPER_CALLER.GetDebouncingOfEvent
        OpEventGetDebouncingOfEvent_GetDebouncingOfEvent_EvtInfo_AutoCreatedDemEvent_ECUM_E_CONFIGURATION_DATA_INCONSISTENT: start-on-event=DemSatellite_OsApplication_Untrusted_Core0InternalBehavior/GetDebouncingOfEvent, operation=EvtInfo_AutoCreatedDemEvent_ECUM_E_CONFIGURATION_DATA_INCONSISTENT.GetDebouncingOfEvent
        OpEventGetDebouncingOfEvent_GetDebouncingOfEvent_EvtInfo_AutoCreatedDemEvent_ECUM_E_ALL_RUN_REQUESTS_KILLED: start-on-event=DemSatellite_OsApplication_Untrusted_Core0InternalBehavior/GetDebouncingOfEvent, operation=EvtInfo_AutoCreatedDemEvent_ECUM_E_ALL_RUN_REQUESTS_KILLED.GetDebouncingOfEvent
        OpEventGetDebouncingOfEvent_GetDebouncingOfEvent_EvtInfo_AutoCreatedDemEvent_FLS_E_WRITE_FAILED: start-on-event=DemSatellite_OsApplication_Untrusted_Core0InternalBehavior/GetDebouncingOfEvent, operation=EvtInfo_AutoCreatedDemEvent_FLS_E_WRITE_FAILED.GetDebouncingOfEvent
        OpEventGetDebouncingOfEvent_GetDebouncingOfEvent_EvtInfo_AutoCreatedDemEvent_FLS_E_UNEXPECTED_FLASH_ID: start-on-event=DemSatellite_OsApplication_Untrusted_Core0InternalBehavior/GetDebouncingOfEvent, operation=EvtInfo_AutoCreatedDemEvent_FLS_E_UNEXPECTED_FLASH_ID.GetDebouncingOfEvent
        OpEventGetDebouncingOfEvent_GetDebouncingOfEvent_EvtInfo_AutoCreatedDemEvent_FLS_E_READ_FAILED: start-on-event=DemSatellite_OsApplication_Untrusted_Core0InternalBehavior/GetDebouncingOfEvent, operation=EvtInfo_AutoCreatedDemEvent_FLS_E_READ_FAILED.GetDebouncingOfEvent
        OpEventGetDebouncingOfEvent_GetDebouncingOfEvent_EvtInfo_AutoCreatedDemEvent_FLS_E_ERASE_FAILED: start-on-event=DemSatellite_OsApplication_Untrusted_Core0InternalBehavior/GetDebouncingOfEvent, operation=EvtInfo_AutoCreatedDemEvent_FLS_E_ERASE_FAILED.GetDebouncingOfEvent
        OpEventGetDebouncingOfEvent_GetDebouncingOfEvent_EvtInfo_AutoCreatedDemEvent_FLS_E_COMPARE_FAILED: start-on-event=DemSatellite_OsApplication_Untrusted_Core0InternalBehavior/GetDebouncingOfEvent, operation=EvtInfo_AutoCreatedDemEvent_FLS_E_COMPARE_FAILED.GetDebouncingOfEvent
        OpEventGetDebouncingOfEvent_GetDebouncingOfEvent_EvtInfo_AutoCreatedDemEvent_GPT_E_TIMEOUT: start-on-event=DemSatellite_OsApplication_Untrusted_Core0InternalBehavior/GetDebouncingOfEvent, operation=EvtInfo_AutoCreatedDemEvent_GPT_E_TIMEOUT.GetDebouncingOfEvent
        OpEventGetDebouncingOfEvent_GetDebouncingOfEvent_EvtInfo_AutoCreatedDemEvent_J1939NM_E_ADDRESS_LOST: start-on-event=DemSatellite_OsApplication_Untrusted_Core0InternalBehavior/GetDebouncingOfEvent, operation=EvtInfo_AutoCreatedDemEvent_J1939NM_E_ADDRESS_LOST.GetDebouncingOfEvent
        OpEventGetDebouncingOfEvent_GetDebouncingOfEvent_EvtInfo_AutoCreatedDemEvent_J1939TpConfiguration_J1939TP_E_COMMUNICATION: start-on-event=DemSatellite_OsApplication_Untrusted_Core0InternalBehavior/GetDebouncingOfEvent, operation=EvtInfo_AutoCreatedDemEvent_J1939TpConfiguration_J1939TP_E_COMMUNICATION.GetDebouncingOfEvent
        OpEventGetDebouncingOfEvent_GetDebouncingOfEvent_EvtInfo_AutoCreatedDemEvent_LIN_E_TIMEOUT: start-on-event=DemSatellite_OsApplication_Untrusted_Core0InternalBehavior/GetDebouncingOfEvent, operation=EvtInfo_AutoCreatedDemEvent_LIN_E_TIMEOUT.GetDebouncingOfEvent
        OpEventGetDebouncingOfEvent_GetDebouncingOfEvent_EvtInfo_AutoCreatedDemEvent_MCL_E_DMA_UNRECOGNIZED: start-on-event=DemSatellite_OsApplication_Untrusted_Core0InternalBehavior/GetDebouncingOfEvent, operation=EvtInfo_AutoCreatedDemEvent_MCL_E_DMA_UNRECOGNIZED.GetDebouncingOfEvent
        OpEventGetDebouncingOfEvent_GetDebouncingOfEvent_EvtInfo_AutoCreatedDemEvent_MCL_E_DMA_PRIORITY: start-on-event=DemSatellite_OsApplication_Untrusted_Core0InternalBehavior/GetDebouncingOfEvent, operation=EvtInfo_AutoCreatedDemEvent_MCL_E_DMA_PRIORITY.GetDebouncingOfEvent
        OpEventGetDebouncingOfEvent_GetDebouncingOfEvent_EvtInfo_AutoCreatedDemEvent_MCL_E_DMA_INCONSISTENCY: start-on-event=DemSatellite_OsApplication_Untrusted_Core0InternalBehavior/GetDebouncingOfEvent, operation=EvtInfo_AutoCreatedDemEvent_MCL_E_DMA_INCONSISTENCY.GetDebouncingOfEvent
        OpEventGetDebouncingOfEvent_GetDebouncingOfEvent_EvtInfo_AutoCreatedDemEvent_MCL_E_DMA_ECC: start-on-event=DemSatellite_OsApplication_Untrusted_Core0InternalBehavior/GetDebouncingOfEvent, operation=EvtInfo_AutoCreatedDemEvent_MCL_E_DMA_ECC.GetDebouncingOfEvent
        OpEventGetDebouncingOfEvent_GetDebouncingOfEvent_EvtInfo_AutoCreatedDemEvent_MCL_E_DMA_DESCRIPTOR: start-on-event=DemSatellite_OsApplication_Untrusted_Core0InternalBehavior/GetDebouncingOfEvent, operation=EvtInfo_AutoCreatedDemEvent_MCL_E_DMA_DESCRIPTOR.GetDebouncingOfEvent
        OpEventGetDebouncingOfEvent_GetDebouncingOfEvent_EvtInfo_AutoCreatedDemEvent_MCL_E_DMA_BUS: start-on-event=DemSatellite_OsApplication_Untrusted_Core0InternalBehavior/GetDebouncingOfEvent, operation=EvtInfo_AutoCreatedDemEvent_MCL_E_DMA_BUS.GetDebouncingOfEvent
        OpEventGetDebouncingOfEvent_GetDebouncingOfEvent_EvtInfo_AutoCreatedDemEvent_MCU_E_TIMEOUT_FAILURE: start-on-event=DemSatellite_OsApplication_Untrusted_Core0InternalBehavior/GetDebouncingOfEvent, operation=EvtInfo_AutoCreatedDemEvent_MCU_E_TIMEOUT_FAILURE.GetDebouncingOfEvent
        OpEventGetDebouncingOfEvent_GetDebouncingOfEvent_EvtInfo_AutoCreatedDemEvent_MCU_E_SSCM_CER_FAILURE: start-on-event=DemSatellite_OsApplication_Untrusted_Core0InternalBehavior/GetDebouncingOfEvent, operation=EvtInfo_AutoCreatedDemEvent_MCU_E_SSCM_CER_FAILURE.GetDebouncingOfEvent
        OpEventGetDebouncingOfEvent_GetDebouncingOfEvent_EvtInfo_AutoCreatedDemEvent_MCU_E_INVALIDMODE_CONFIG: start-on-event=DemSatellite_OsApplication_Untrusted_Core0InternalBehavior/GetDebouncingOfEvent, operation=EvtInfo_AutoCreatedDemEvent_MCU_E_INVALIDMODE_CONFIG.GetDebouncingOfEvent
        OpEventGetDebouncingOfEvent_GetDebouncingOfEvent_EvtInfo_AutoCreatedDemEvent_MCU_E_CLOCK_FAILURE: start-on-event=DemSatellite_OsApplication_Untrusted_Core0InternalBehavior/GetDebouncingOfEvent, operation=EvtInfo_AutoCreatedDemEvent_MCU_E_CLOCK_FAILURE.GetDebouncingOfEvent
        OpEventGetDebouncingOfEvent_GetDebouncingOfEvent_EvtInfo_AutoCreatedDemEvent_NVM_E_WRONG_BLOCK_ID: start-on-event=DemSatellite_OsApplication_Untrusted_Core0InternalBehavior/GetDebouncingOfEvent, operation=EvtInfo_AutoCreatedDemEvent_NVM_E_WRONG_BLOCK_ID.GetDebouncingOfEvent
        OpEventGetDebouncingOfEvent_GetDebouncingOfEvent_EvtInfo_AutoCreatedDemEvent_NVM_E_WRITE_PROTECTED: start-on-event=DemSatellite_OsApplication_Untrusted_Core0InternalBehavior/GetDebouncingOfEvent, operation=EvtInfo_AutoCreatedDemEvent_NVM_E_WRITE_PROTECTED.GetDebouncingOfEvent
        OpEventGetDebouncingOfEvent_GetDebouncingOfEvent_EvtInfo_AutoCreatedDemEvent_NVM_E_VERIFY_FAILED: start-on-event=DemSatellite_OsApplication_Untrusted_Core0InternalBehavior/GetDebouncingOfEvent, operation=EvtInfo_AutoCreatedDemEvent_NVM_E_VERIFY_FAILED.GetDebouncingOfEvent
        OpEventGetDebouncingOfEvent_GetDebouncingOfEvent_EvtInfo_AutoCreatedDemEvent_NVM_E_REQ_FAILED: start-on-event=DemSatellite_OsApplication_Untrusted_Core0InternalBehavior/GetDebouncingOfEvent, operation=EvtInfo_AutoCreatedDemEvent_NVM_E_REQ_FAILED.GetDebouncingOfEvent
        OpEventGetDebouncingOfEvent_GetDebouncingOfEvent_EvtInfo_AutoCreatedDemEvent_NVM_E_QUEUE_OVERFLOW: start-on-event=DemSatellite_OsApplication_Untrusted_Core0InternalBehavior/GetDebouncingOfEvent, operation=EvtInfo_AutoCreatedDemEvent_NVM_E_QUEUE_OVERFLOW.GetDebouncingOfEvent
        OpEventGetDebouncingOfEvent_GetDebouncingOfEvent_EvtInfo_AutoCreatedDemEvent_NVM_E_LOSS_OF_REDUNDANCY: start-on-event=DemSatellite_OsApplication_Untrusted_Core0InternalBehavior/GetDebouncingOfEvent, operation=EvtInfo_AutoCreatedDemEvent_NVM_E_LOSS_OF_REDUNDANCY.GetDebouncingOfEvent
        OpEventGetDebouncingOfEvent_GetDebouncingOfEvent_EvtInfo_AutoCreatedDemEvent_NVM_E_INTEGRITY_FAILED: start-on-event=DemSatellite_OsApplication_Untrusted_Core0InternalBehavior/GetDebouncingOfEvent, operation=EvtInfo_AutoCreatedDemEvent_NVM_E_INTEGRITY_FAILED.GetDebouncingOfEvent
        OpEventGetDebouncingOfEvent_GetDebouncingOfEvent_EvtInfo_AutoCreatedDemEvent_SPI_E_HARDWARE_ERROR: start-on-event=DemSatellite_OsApplication_Untrusted_Core0InternalBehavior/GetDebouncingOfEvent, operation=EvtInfo_AutoCreatedDemEvent_SPI_E_HARDWARE_ERROR.GetDebouncingOfEvent
        OpEventGetDebouncingOfEvent_GetDebouncingOfEvent_EvtInfo_AutoCreatedDemEvent_SpiDriver_SPI_E_HARDWARE_ERROR: start-on-event=DemSatellite_OsApplication_Untrusted_Core0InternalBehavior/GetDebouncingOfEvent, operation=EvtInfo_AutoCreatedDemEvent_SpiDriver_SPI_E_HARDWARE_ERROR.GetDebouncingOfEvent
        OpEventGetDebouncingOfEvent_GetDebouncingOfEvent_EvtInfo_AutoCreatedDemEvent_WDG_E_UNLOCKED: start-on-event=DemSatellite_OsApplication_Untrusted_Core0InternalBehavior/GetDebouncingOfEvent, operation=EvtInfo_AutoCreatedDemEvent_WDG_E_UNLOCKED.GetDebouncingOfEvent
        OpEventGetDebouncingOfEvent_GetDebouncingOfEvent_EvtInfo_AutoCreatedDemEvent_WDG_E_MODE_FAILED: start-on-event=DemSatellite_OsApplication_Untrusted_Core0InternalBehavior/GetDebouncingOfEvent, operation=EvtInfo_AutoCreatedDemEvent_WDG_E_MODE_FAILED.GetDebouncingOfEvent
        OpEventGetDebouncingOfEvent_GetDebouncingOfEvent_EvtInfo_AutoCreatedDemEvent_WDG_E_INVALID_PARAMETER: start-on-event=DemSatellite_OsApplication_Untrusted_Core0InternalBehavior/GetDebouncingOfEvent, operation=EvtInfo_AutoCreatedDemEvent_WDG_E_INVALID_PARAMETER.GetDebouncingOfEvent
        OpEventGetDebouncingOfEvent_GetDebouncingOfEvent_EvtInfo_AutoCreatedDemEvent_WDG_E_INVALID_CALL: start-on-event=DemSatellite_OsApplication_Untrusted_Core0InternalBehavior/GetDebouncingOfEvent, operation=EvtInfo_AutoCreatedDemEvent_WDG_E_INVALID_CALL.GetDebouncingOfEvent
        OpEventGetDebouncingOfEvent_GetDebouncingOfEvent_EvtInfo_AutoCreatedDemEvent_WDG_E_FORBIDDEN_INVOCATION: start-on-event=DemSatellite_OsApplication_Untrusted_Core0InternalBehavior/GetDebouncingOfEvent, operation=EvtInfo_AutoCreatedDemEvent_WDG_E_FORBIDDEN_INVOCATION.GetDebouncingOfEvent
        OpEventGetDebouncingOfEvent_GetDebouncingOfEvent_EvtInfo_AutoCreatedDemEvent_WDG_E_DISABLE_REJECTED: start-on-event=DemSatellite_OsApplication_Untrusted_Core0InternalBehavior/GetDebouncingOfEvent, operation=EvtInfo_AutoCreatedDemEvent_WDG_E_DISABLE_REJECTED.GetDebouncingOfEvent
        OpEventGetDebouncingOfEvent_GetDebouncingOfEvent_EvtInfo_AutoCreatedDemEvent_WDG_E_CORRUPT_CONFIG: start-on-event=DemSatellite_OsApplication_Untrusted_Core0InternalBehavior/GetDebouncingOfEvent, operation=EvtInfo_AutoCreatedDemEvent_WDG_E_CORRUPT_CONFIG.GetDebouncingOfEvent
        OpEventGetMonitorStatus_GetMonitorStatus_EvtInfo_AutoCreatedDemEvent_ADC_E_TIMEOUT: start-on-event=DemSatellite_OsApplication_Untrusted_Core0InternalBehavior/GetMonitorStatus, operation=EvtInfo_AutoCreatedDemEvent_ADC_E_TIMEOUT.GetMonitorStatus
        OpEventGetMonitorStatus_GetMonitorStatus_EvtInfo_AutoCreatedDemEvent_CC_DisableDM_CIOM_oCabSubnet_Rx_063a5fbc_BswMRepor_474402ea: start-on-event=DemSatellite_OsApplication_Untrusted_Core0InternalBehavior/GetMonitorStatus, operation=EvtInfo_AutoCreatedDemEvent_CC_DisableDM_CIOM_oCabSubnet_Rx_063a5fbc_BswMReportFailToDemRef.GetMonitorStatus
        OpEventGetMonitorStatus_GetMonitorStatus_EvtInfo_AutoCreatedDemEvent_CC_J1939RmStateSwitch_CN_Backbone1J1939_0b1f4bae_C_606af43a: start-on-event=DemSatellite_OsApplication_Untrusted_Core0InternalBehavior/GetMonitorStatus, operation=EvtInfo_AutoCreatedDemEvent_CC_J1939RmStateSwitch_CN_Backbone1J1939_0b1f4bae_CIOM_4d5cd289_J1939RM_STATE_OFFLINE_BswMRe_5a5b15b8.GetMonitorStatus
        OpEventGetMonitorStatus_GetMonitorStatus_EvtInfo_AutoCreatedDemEvent_CC_J1939RmStateSwitch_CN_Backbone1J1939_0b1f4bae_C_1d35c4a9: start-on-event=DemSatellite_OsApplication_Untrusted_Core0InternalBehavior/GetMonitorStatus, operation=EvtInfo_AutoCreatedDemEvent_CC_J1939RmStateSwitch_CN_Backbone1J1939_0b1f4bae_CIOM_4d5cd289_J1939RM_STATE_ONLINE_BswMRep_ec959aed.GetMonitorStatus
        OpEventGetMonitorStatus_GetMonitorStatus_EvtInfo_AutoCreatedDemEvent_CC_DisablePDUGroup_CIOM_oLIN04_Tx_04202f7b_BswMRep_498deffc: start-on-event=DemSatellite_OsApplication_Untrusted_Core0InternalBehavior/GetMonitorStatus, operation=EvtInfo_AutoCreatedDemEvent_CC_DisablePDUGroup_CIOM_oLIN04_Tx_04202f7b_BswMReportFailToDemRef.GetMonitorStatus
        OpEventGetMonitorStatus_GetMonitorStatus_EvtInfo_AutoCreatedDemEvent_CC_DisablePDUGroup_CIOM_oLIN04_Rx_527a88fd_BswMRep_802f8a02: start-on-event=DemSatellite_OsApplication_Untrusted_Core0InternalBehavior/GetMonitorStatus, operation=EvtInfo_AutoCreatedDemEvent_CC_DisablePDUGroup_CIOM_oLIN04_Rx_527a88fd_BswMReportFailToDemRef.GetMonitorStatus
        OpEventGetMonitorStatus_GetMonitorStatus_EvtInfo_AutoCreatedDemEvent_CC_DisablePDUGroup_CIOM_oLIN01_Tx_33fedf49_BswMRep_32354685: start-on-event=DemSatellite_OsApplication_Untrusted_Core0InternalBehavior/GetMonitorStatus, operation=EvtInfo_AutoCreatedDemEvent_CC_DisablePDUGroup_CIOM_oLIN01_Tx_33fedf49_BswMReportFailToDemRef.GetMonitorStatus
        OpEventGetMonitorStatus_GetMonitorStatus_EvtInfo_AutoCreatedDemEvent_CC_DisablePDUGroup_CIOM_oLIN01_Rx_65a478cf_BswMRep_0c05ec0f: start-on-event=DemSatellite_OsApplication_Untrusted_Core0InternalBehavior/GetMonitorStatus, operation=EvtInfo_AutoCreatedDemEvent_CC_DisablePDUGroup_CIOM_oLIN01_Rx_65a478cf_BswMReportFailToDemRef.GetMonitorStatus
        OpEventGetMonitorStatus_GetMonitorStatus_EvtInfo_AutoCreatedDemEvent_CC_EnablePDUGroup_CIOM_oLIN04_Tx_04202f7b_BswMRepo_51c664f2: start-on-event=DemSatellite_OsApplication_Untrusted_Core0InternalBehavior/GetMonitorStatus, operation=EvtInfo_AutoCreatedDemEvent_CC_EnablePDUGroup_CIOM_oLIN04_Tx_04202f7b_BswMReportFailToDemRef.GetMonitorStatus
        OpEventGetMonitorStatus_GetMonitorStatus_EvtInfo_AutoCreatedDemEvent_CC_EnablePDUGroup_CIOM_oLIN04_Rx_527a88fd_BswMRepo_9864010c: start-on-event=DemSatellite_OsApplication_Untrusted_Core0InternalBehavior/GetMonitorStatus, operation=EvtInfo_AutoCreatedDemEvent_CC_EnablePDUGroup_CIOM_oLIN04_Rx_527a88fd_BswMReportFailToDemRef.GetMonitorStatus
        OpEventGetMonitorStatus_GetMonitorStatus_EvtInfo_AutoCreatedDemEvent_CC_DisableDM_CIOM_oBackbone2_Rx_4e624434_BswMRepor_20100864: start-on-event=DemSatellite_OsApplication_Untrusted_Core0InternalBehavior/GetMonitorStatus, operation=EvtInfo_AutoCreatedDemEvent_CC_DisableDM_CIOM_oBackbone2_Rx_4e624434_BswMReportFailToDemRef.GetMonitorStatus
        OpEventGetMonitorStatus_GetMonitorStatus_EvtInfo_AutoCreatedDemEvent_CC_EnableDM_CIOM_oBackbone2_Rx_4e624434_BswMReport_55e1a33f: start-on-event=DemSatellite_OsApplication_Untrusted_Core0InternalBehavior/GetMonitorStatus, operation=EvtInfo_AutoCreatedDemEvent_CC_EnableDM_CIOM_oBackbone2_Rx_4e624434_BswMReportFailToDemRef.GetMonitorStatus
        OpEventGetMonitorStatus_GetMonitorStatus_EvtInfo_AutoCreatedDemEvent_CC_DisableDM_CIOM_oSecuritySubnet_Rx_3a3c1dbc_BswM_981795f5: start-on-event=DemSatellite_OsApplication_Untrusted_Core0InternalBehavior/GetMonitorStatus, operation=EvtInfo_AutoCreatedDemEvent_CC_DisableDM_CIOM_oSecuritySubnet_Rx_3a3c1dbc_BswMReportFailToDemRef.GetMonitorStatus
        OpEventGetMonitorStatus_GetMonitorStatus_EvtInfo_AutoCreatedDemEvent_CC_EnableDM_CIOM_oSecuritySubnet_Rx_3a3c1dbc_BswMR_abf0617f: start-on-event=DemSatellite_OsApplication_Untrusted_Core0InternalBehavior/GetMonitorStatus, operation=EvtInfo_AutoCreatedDemEvent_CC_EnableDM_CIOM_oSecuritySubnet_Rx_3a3c1dbc_BswMReportFailToDemRef.GetMonitorStatus
        OpEventGetMonitorStatus_GetMonitorStatus_EvtInfo_AutoCreatedDemEvent_CC_DisablePDUGroup_CIOM_oCabSubnet_Tx_5060f83a_Bsw_e8fe269b: start-on-event=DemSatellite_OsApplication_Untrusted_Core0InternalBehavior/GetMonitorStatus, operation=EvtInfo_AutoCreatedDemEvent_CC_DisablePDUGroup_CIOM_oCabSubnet_Tx_5060f83a_BswMReportFailToDemRef.GetMonitorStatus
        OpEventGetMonitorStatus_GetMonitorStatus_EvtInfo_AutoCreatedDemEvent_CC_EnablePDUGroup_CIOM_oCabSubnet_Tx_5060f83a_BswM_e5a0ab51: start-on-event=DemSatellite_OsApplication_Untrusted_Core0InternalBehavior/GetMonitorStatus, operation=EvtInfo_AutoCreatedDemEvent_CC_EnablePDUGroup_CIOM_oCabSubnet_Tx_5060f83a_BswMReportFailToDemRef.GetMonitorStatus
        OpEventGetMonitorStatus_GetMonitorStatus_EvtInfo_AutoCreatedDemEvent_CC_EnableDM_CIOM_oCabSubnet_Rx_063a5fbc_BswMReport_32b5a9b1: start-on-event=DemSatellite_OsApplication_Untrusted_Core0InternalBehavior/GetMonitorStatus, operation=EvtInfo_AutoCreatedDemEvent_CC_EnableDM_CIOM_oCabSubnet_Rx_063a5fbc_BswMReportFailToDemRef.GetMonitorStatus
        OpEventGetMonitorStatus_GetMonitorStatus_EvtInfo_AutoCreatedDemEvent_CC_DisablePDUGroup_CIOM_oBackbone2_Tx_1838e3b2_Bsw_8aa3bbb5: start-on-event=DemSatellite_OsApplication_Untrusted_Core0InternalBehavior/GetMonitorStatus, operation=EvtInfo_AutoCreatedDemEvent_CC_DisablePDUGroup_CIOM_oBackbone2_Tx_1838e3b2_BswMReportFailToDemRef.GetMonitorStatus
        OpEventGetMonitorStatus_GetMonitorStatus_EvtInfo_AutoCreatedDemEvent_CC_EnablePDUGroup_CIOM_oBackbone2_Tx_1838e3b2_BswM_87fd367f: start-on-event=DemSatellite_OsApplication_Untrusted_Core0InternalBehavior/GetMonitorStatus, operation=EvtInfo_AutoCreatedDemEvent_CC_EnablePDUGroup_CIOM_oBackbone2_Tx_1838e3b2_BswMReportFailToDemRef.GetMonitorStatus
        OpEventGetMonitorStatus_GetMonitorStatus_EvtInfo_AutoCreatedDemEvent_CC_DisablePDUGroup_CIOM_oBackbone2_Rx_4e624434_Bsw_7fd71a3f: start-on-event=DemSatellite_OsApplication_Untrusted_Core0InternalBehavior/GetMonitorStatus, operation=EvtInfo_AutoCreatedDemEvent_CC_DisablePDUGroup_CIOM_oBackbone2_Rx_4e624434_BswMReportFailToDemRef.GetMonitorStatus
        OpEventGetMonitorStatus_GetMonitorStatus_EvtInfo_AutoCreatedDemEvent_CC_EnablePDUGroup_CIOM_oBackbone2_Rx_4e624434_BswM_728997f5: start-on-event=DemSatellite_OsApplication_Untrusted_Core0InternalBehavior/GetMonitorStatus, operation=EvtInfo_AutoCreatedDemEvent_CC_EnablePDUGroup_CIOM_oBackbone2_Rx_4e624434_BswMReportFailToDemRef.GetMonitorStatus
        OpEventGetMonitorStatus_GetMonitorStatus_EvtInfo_AutoCreatedDemEvent_CC_DisablePDUGroup_CIOM_oBackbone1J1939_Rx_BC_405b_59573551: start-on-event=DemSatellite_OsApplication_Untrusted_Core0InternalBehavior/GetMonitorStatus, operation=EvtInfo_AutoCreatedDemEvent_CC_DisablePDUGroup_CIOM_oBackbone1J1939_Rx_BC_405bc776_BswMReportFailToDemRef.GetMonitorStatus
        OpEventGetMonitorStatus_GetMonitorStatus_EvtInfo_AutoCreatedDemEvent_CC_EnablePDUGroup_CIOM_oBackbone1J1939_Rx_BC_405bc_95e448aa: start-on-event=DemSatellite_OsApplication_Untrusted_Core0InternalBehavior/GetMonitorStatus, operation=EvtInfo_AutoCreatedDemEvent_CC_EnablePDUGroup_CIOM_oBackbone1J1939_Rx_BC_405bc776_BswMReportFailToDemRef.GetMonitorStatus
        OpEventGetMonitorStatus_GetMonitorStatus_EvtInfo_AutoCreatedDemEvent_CC_EnablePDUGroup_CIOM_oLIN02_Tx_214b70a7_BswMRepo_cbeeae98: start-on-event=DemSatellite_OsApplication_Untrusted_Core0InternalBehavior/GetMonitorStatus, operation=EvtInfo_AutoCreatedDemEvent_CC_EnablePDUGroup_CIOM_oLIN02_Tx_214b70a7_BswMReportFailToDemRef.GetMonitorStatus
        OpEventGetMonitorStatus_GetMonitorStatus_EvtInfo_AutoCreatedDemEvent_CC_EnablePDUGroup_CIOM_oLIN02_Rx_7711d721_BswMRepo_1d246dfa: start-on-event=DemSatellite_OsApplication_Untrusted_Core0InternalBehavior/GetMonitorStatus, operation=EvtInfo_AutoCreatedDemEvent_CC_EnablePDUGroup_CIOM_oLIN02_Rx_7711d721_BswMReportFailToDemRef.GetMonitorStatus
        OpEventGetMonitorStatus_GetMonitorStatus_EvtInfo_AutoCreatedDemEvent_CC_EnablePDUGroup_CIOM_oLIN01_Tx_33fedf49_BswMRepo_2a7ecd8b: start-on-event=DemSatellite_OsApplication_Untrusted_Core0InternalBehavior/GetMonitorStatus, operation=EvtInfo_AutoCreatedDemEvent_CC_EnablePDUGroup_CIOM_oLIN01_Tx_33fedf49_BswMReportFailToDemRef.GetMonitorStatus
        OpEventGetMonitorStatus_GetMonitorStatus_EvtInfo_AutoCreatedDemEvent_CC_EnablePDUGroup_CIOM_oLIN01_Rx_65a478cf_BswMRepo_144e6701: start-on-event=DemSatellite_OsApplication_Untrusted_Core0InternalBehavior/GetMonitorStatus, operation=EvtInfo_AutoCreatedDemEvent_CC_EnablePDUGroup_CIOM_oLIN01_Rx_65a478cf_BswMReportFailToDemRef.GetMonitorStatus
        OpEventGetMonitorStatus_GetMonitorStatus_EvtInfo_AutoCreatedDemEvent_CC_DisablePDUGroup_CIOM_oLIN03_Tx_99f717c2_BswMRep_415ff55e: start-on-event=DemSatellite_OsApplication_Untrusted_Core0InternalBehavior/GetMonitorStatus, operation=EvtInfo_AutoCreatedDemEvent_CC_DisablePDUGroup_CIOM_oLIN03_Tx_99f717c2_BswMReportFailToDemRef.GetMonitorStatus
        OpEventGetMonitorStatus_GetMonitorStatus_EvtInfo_AutoCreatedDemEvent_CC_DisablePDUGroup_CIOM_oLIN03_Rx_cfadb044_BswMRep_78f290a0: start-on-event=DemSatellite_OsApplication_Untrusted_Core0InternalBehavior/GetMonitorStatus, operation=EvtInfo_AutoCreatedDemEvent_CC_DisablePDUGroup_CIOM_oLIN03_Rx_cfadb044_BswMReportFailToDemRef.GetMonitorStatus
        OpEventGetMonitorStatus_GetMonitorStatus_EvtInfo_AutoCreatedDemEvent_CC_DisableDM_CIOM_oFMSNet_Rx_BC_dd2c1510_BswMRepor_0fb39a37: start-on-event=DemSatellite_OsApplication_Untrusted_Core0InternalBehavior/GetMonitorStatus, operation=EvtInfo_AutoCreatedDemEvent_CC_DisableDM_CIOM_oFMSNet_Rx_BC_dd2c1510_BswMReportFailToDemRef.GetMonitorStatus
        OpEventGetMonitorStatus_GetMonitorStatus_EvtInfo_AutoCreatedDemEvent_CC_EnableDM_CIOM_oFMSNet_Rx_BC_dd2c1510_BswMReport_7a42316c: start-on-event=DemSatellite_OsApplication_Untrusted_Core0InternalBehavior/GetMonitorStatus, operation=EvtInfo_AutoCreatedDemEvent_CC_EnableDM_CIOM_oFMSNet_Rx_BC_dd2c1510_BswMReportFailToDemRef.GetMonitorStatus
        OpEventGetMonitorStatus_GetMonitorStatus_EvtInfo_AutoCreatedDemEvent_CC_EnablePDUGroup_CIOM_oLIN03_Tx_99f717c2_BswMRepo_59147e50: start-on-event=DemSatellite_OsApplication_Untrusted_Core0InternalBehavior/GetMonitorStatus, operation=EvtInfo_AutoCreatedDemEvent_CC_EnablePDUGroup_CIOM_oLIN03_Tx_99f717c2_BswMReportFailToDemRef.GetMonitorStatus
        OpEventGetMonitorStatus_GetMonitorStatus_EvtInfo_AutoCreatedDemEvent_CC_EnablePDUGroup_CIOM_oLIN03_Rx_cfadb044_BswMRepo_60b91bae: start-on-event=DemSatellite_OsApplication_Untrusted_Core0InternalBehavior/GetMonitorStatus, operation=EvtInfo_AutoCreatedDemEvent_CC_EnablePDUGroup_CIOM_oLIN03_Rx_cfadb044_BswMReportFailToDemRef.GetMonitorStatus
        OpEventGetMonitorStatus_GetMonitorStatus_EvtInfo_AutoCreatedDemEvent_CC_DisablePDUGroup_CIOM_oLIN02_Tx_214b70a7_BswMRep_d3a52596: start-on-event=DemSatellite_OsApplication_Untrusted_Core0InternalBehavior/GetMonitorStatus, operation=EvtInfo_AutoCreatedDemEvent_CC_DisablePDUGroup_CIOM_oLIN02_Tx_214b70a7_BswMReportFailToDemRef.GetMonitorStatus
        OpEventGetMonitorStatus_GetMonitorStatus_EvtInfo_AutoCreatedDemEvent_CC_DisablePDUGroup_CIOM_oLIN02_Rx_7711d721_BswMRep_056fe6f4: start-on-event=DemSatellite_OsApplication_Untrusted_Core0InternalBehavior/GetMonitorStatus, operation=EvtInfo_AutoCreatedDemEvent_CC_DisablePDUGroup_CIOM_oLIN02_Rx_7711d721_BswMReportFailToDemRef.GetMonitorStatus
        OpEventGetMonitorStatus_GetMonitorStatus_EvtInfo_AutoCreatedDemEvent_CC_DisablePDUGroup_CIOM_oCabSubnet_Rx_063a5fbc_Bsw_188310b1: start-on-event=DemSatellite_OsApplication_Untrusted_Core0InternalBehavior/GetMonitorStatus, operation=EvtInfo_AutoCreatedDemEvent_CC_DisablePDUGroup_CIOM_oCabSubnet_Rx_063a5fbc_BswMReportFailToDemRef.GetMonitorStatus
        OpEventGetMonitorStatus_GetMonitorStatus_EvtInfo_AutoCreatedDemEvent_CC_EnablePDUGroup_CIOM_oCabSubnet_Rx_063a5fbc_BswM_15dd9d7b: start-on-event=DemSatellite_OsApplication_Untrusted_Core0InternalBehavior/GetMonitorStatus, operation=EvtInfo_AutoCreatedDemEvent_CC_EnablePDUGroup_CIOM_oCabSubnet_Rx_063a5fbc_BswMReportFailToDemRef.GetMonitorStatus
        OpEventGetMonitorStatus_GetMonitorStatus_EvtInfo_AutoCreatedDemEvent_CC_DisablePDUGroup_CIOM_oFMSNet_Rx_BC_dd2c1510_Bsw_5074886c: start-on-event=DemSatellite_OsApplication_Untrusted_Core0InternalBehavior/GetMonitorStatus, operation=EvtInfo_AutoCreatedDemEvent_CC_DisablePDUGroup_CIOM_oFMSNet_Rx_BC_dd2c1510_BswMReportFailToDemRef.GetMonitorStatus
        OpEventGetMonitorStatus_GetMonitorStatus_EvtInfo_AutoCreatedDemEvent_CC_EnablePDUGroup_CIOM_oFMSNet_Rx_BC_dd2c1510_BswM_5d2a05a6: start-on-event=DemSatellite_OsApplication_Untrusted_Core0InternalBehavior/GetMonitorStatus, operation=EvtInfo_AutoCreatedDemEvent_CC_EnablePDUGroup_CIOM_oFMSNet_Rx_BC_dd2c1510_BswMReportFailToDemRef.GetMonitorStatus
        OpEventGetMonitorStatus_GetMonitorStatus_EvtInfo_AutoCreatedDemEvent_CC_DisablePDUGroup_CIOM_oSecuritySubnet_Rx_3a3c1db_84073565: start-on-event=DemSatellite_OsApplication_Untrusted_Core0InternalBehavior/GetMonitorStatus, operation=EvtInfo_AutoCreatedDemEvent_CC_DisablePDUGroup_CIOM_oSecuritySubnet_Rx_3a3c1dbc_BswMReportFailToDemRef.GetMonitorStatus
        OpEventGetMonitorStatus_GetMonitorStatus_EvtInfo_AutoCreatedDemEvent_CC_EnablePDUGroup_CIOM_oSecuritySubnet_Rx_3a3c1dbc_eb1dd60e: start-on-event=DemSatellite_OsApplication_Untrusted_Core0InternalBehavior/GetMonitorStatus, operation=EvtInfo_AutoCreatedDemEvent_CC_EnablePDUGroup_CIOM_oSecuritySubnet_Rx_3a3c1dbc_BswMReportFailToDemRef.GetMonitorStatus
        OpEventGetMonitorStatus_GetMonitorStatus_EvtInfo_AutoCreatedDemEvent_CC_DisablePDUGroup_CIOM_oFMSNet_Tx_0x31_BC_38fc8c7_ab659868: start-on-event=DemSatellite_OsApplication_Untrusted_Core0InternalBehavior/GetMonitorStatus, operation=EvtInfo_AutoCreatedDemEvent_CC_DisablePDUGroup_CIOM_oFMSNet_Tx_0x31_BC_38fc8c7d_BswMReportFailToDemRef.GetMonitorStatus
        OpEventGetMonitorStatus_GetMonitorStatus_EvtInfo_AutoCreatedDemEvent_CC_EnablePDUGroup_CIOM_oFMSNet_Tx_0x31_BC_38fc8c7d_c47f7b03: start-on-event=DemSatellite_OsApplication_Untrusted_Core0InternalBehavior/GetMonitorStatus, operation=EvtInfo_AutoCreatedDemEvent_CC_EnablePDUGroup_CIOM_oFMSNet_Tx_0x31_BC_38fc8c7d_BswMReportFailToDemRef.GetMonitorStatus
        OpEventGetMonitorStatus_GetMonitorStatus_EvtInfo_AutoCreatedDemEvent_CC_DisablePDUGroup_CIOM_oSecuritySubnet_Tx_6c66ba3_4ad88704: start-on-event=DemSatellite_OsApplication_Untrusted_Core0InternalBehavior/GetMonitorStatus, operation=EvtInfo_AutoCreatedDemEvent_CC_DisablePDUGroup_CIOM_oSecuritySubnet_Tx_6c66ba3a_BswMReportFailToDemRef.GetMonitorStatus
        OpEventGetMonitorStatus_GetMonitorStatus_EvtInfo_AutoCreatedDemEvent_CC_EnablePDUGroup_CIOM_oSecuritySubnet_Tx_6c66ba3a_25c2646f: start-on-event=DemSatellite_OsApplication_Untrusted_Core0InternalBehavior/GetMonitorStatus, operation=EvtInfo_AutoCreatedDemEvent_CC_EnablePDUGroup_CIOM_oSecuritySubnet_Tx_6c66ba3a_BswMReportFailToDemRef.GetMonitorStatus
        OpEventGetMonitorStatus_GetMonitorStatus_EvtInfo_AutoCreatedDemEvent_CC_DisablePDUGroup_CIOM_oLIN00_Tx_8b42b82c_BswMRep_523c28ff: start-on-event=DemSatellite_OsApplication_Untrusted_Core0InternalBehavior/GetMonitorStatus, operation=EvtInfo_AutoCreatedDemEvent_CC_DisablePDUGroup_CIOM_oLIN00_Tx_8b42b82c_BswMReportFailToDemRef.GetMonitorStatus
        OpEventGetMonitorStatus_GetMonitorStatus_EvtInfo_AutoCreatedDemEvent_CC_EnablePDUGroup_CIOM_oLIN00_Rx_dd181faa_BswMRepo_cb83d152: start-on-event=DemSatellite_OsApplication_Untrusted_Core0InternalBehavior/GetMonitorStatus, operation=EvtInfo_AutoCreatedDemEvent_CC_EnablePDUGroup_CIOM_oLIN00_Rx_dd181faa_BswMReportFailToDemRef.GetMonitorStatus
        OpEventGetMonitorStatus_GetMonitorStatus_EvtInfo_AutoCreatedDemEvent_ESH_Action_ComMCheckPendingRequests_BswMReportFailToDemRef: start-on-event=DemSatellite_OsApplication_Untrusted_Core0InternalBehavior/GetMonitorStatus, operation=EvtInfo_AutoCreatedDemEvent_ESH_Action_ComMCheckPendingRequests_BswMReportFailToDemRef.GetMonitorStatus
        OpEventGetMonitorStatus_GetMonitorStatus_EvtInfo_AutoCreatedDemEvent_CC_DisableDM_CIOM_oBackbone1J1939_Rx_BC_405bc776_B_17f42130: start-on-event=DemSatellite_OsApplication_Untrusted_Core0InternalBehavior/GetMonitorStatus, operation=EvtInfo_AutoCreatedDemEvent_CC_DisableDM_CIOM_oBackbone1J1939_Rx_BC_405bc776_BswMReportFailToDemRef.GetMonitorStatus
        OpEventGetMonitorStatus_GetMonitorStatus_EvtInfo_AutoCreatedDemEvent_CC_DisablePDUGroup_CIOM_oLIN00_Rx_dd181faa_BswMRep_d3c85a5c: start-on-event=DemSatellite_OsApplication_Untrusted_Core0InternalBehavior/GetMonitorStatus, operation=EvtInfo_AutoCreatedDemEvent_CC_DisablePDUGroup_CIOM_oLIN00_Rx_dd181faa_BswMReportFailToDemRef.GetMonitorStatus
        OpEventGetMonitorStatus_GetMonitorStatus_EvtInfo_AutoCreatedDemEvent_CC_EnablePDUGroup_CIOM_oLIN00_Tx_8b42b82c_BswMRepo_4a77a3f1: start-on-event=DemSatellite_OsApplication_Untrusted_Core0InternalBehavior/GetMonitorStatus, operation=EvtInfo_AutoCreatedDemEvent_CC_EnablePDUGroup_CIOM_oLIN00_Tx_8b42b82c_BswMReportFailToDemRef.GetMonitorStatus
        OpEventGetMonitorStatus_GetMonitorStatus_EvtInfo_AutoCreatedDemEvent_ESH_Action_EnterExclusiveArea_BswMReportFailToDemRef: start-on-event=DemSatellite_OsApplication_Untrusted_Core0InternalBehavior/GetMonitorStatus, operation=EvtInfo_AutoCreatedDemEvent_ESH_Action_EnterExclusiveArea_BswMReportFailToDemRef.GetMonitorStatus
        OpEventGetMonitorStatus_GetMonitorStatus_EvtInfo_AutoCreatedDemEvent_ESH_RunToPostRunNested_BswMReportFailToDemRef: start-on-event=DemSatellite_OsApplication_Untrusted_Core0InternalBehavior/GetMonitorStatus, operation=EvtInfo_AutoCreatedDemEvent_ESH_RunToPostRunNested_BswMReportFailToDemRef.GetMonitorStatus
        OpEventGetMonitorStatus_GetMonitorStatus_EvtInfo_AutoCreatedDemEvent_CC_EnableDM_CIOM_oBackbone1J1939_Rx_BC_405bc776_Bs_b5e8ec37: start-on-event=DemSatellite_OsApplication_Untrusted_Core0InternalBehavior/GetMonitorStatus, operation=EvtInfo_AutoCreatedDemEvent_CC_EnableDM_CIOM_oBackbone1J1939_Rx_BC_405bc776_BswMReportFailToDemRef.GetMonitorStatus
        OpEventGetMonitorStatus_GetMonitorStatus_EvtInfo_AutoCreatedDemEvent_CC_DisablePDUGroup_CIOM_oBackbone1J1939_Tx_0x31_BC_838d9525: start-on-event=DemSatellite_OsApplication_Untrusted_Core0InternalBehavior/GetMonitorStatus, operation=EvtInfo_AutoCreatedDemEvent_CC_DisablePDUGroup_CIOM_oBackbone1J1939_Tx_0x31_BC_3782f500_BswMReportFailToDemRef.GetMonitorStatus
        OpEventGetMonitorStatus_GetMonitorStatus_EvtInfo_AutoCreatedDemEvent_CC_J1939RmStateSwitch_CN_FMSNet_fce1aae5_CIOM_3a3d_7ec27867: start-on-event=DemSatellite_OsApplication_Untrusted_Core0InternalBehavior/GetMonitorStatus, operation=EvtInfo_AutoCreatedDemEvent_CC_J1939RmStateSwitch_CN_FMSNet_fce1aae5_CIOM_3a3d59b1_J1939RM_STATE_OFFLINE_BswMReportFailToDemRef.GetMonitorStatus
        OpEventGetMonitorStatus_GetMonitorStatus_EvtInfo_AutoCreatedDemEvent_CC_EnablePDUGroup_CIOM_oBackbone1J1939_Tx_0x31_BC_856b5423: start-on-event=DemSatellite_OsApplication_Untrusted_Core0InternalBehavior/GetMonitorStatus, operation=EvtInfo_AutoCreatedDemEvent_CC_EnablePDUGroup_CIOM_oBackbone1J1939_Tx_0x31_BC_3782f500_BswMReportFailToDemRef.GetMonitorStatus
        OpEventGetMonitorStatus_GetMonitorStatus_EvtInfo_AutoCreatedDemEvent_CC_J1939RmStateSwitch_CN_FMSNet_fce1aae5_CIOM_3a3d_a9427ad4: start-on-event=DemSatellite_OsApplication_Untrusted_Core0InternalBehavior/GetMonitorStatus, operation=EvtInfo_AutoCreatedDemEvent_CC_J1939RmStateSwitch_CN_FMSNet_fce1aae5_CIOM_3a3d59b1_J1939RM_STATE_ONLINE_BswMReportFailToDemRef.GetMonitorStatus
        OpEventGetMonitorStatus_GetMonitorStatus_EvtInfo_AutoCreatedDemEvent_ESH_Action_CancelNvMWriteAll_BswMReportFailToDemRef: start-on-event=DemSatellite_OsApplication_Untrusted_Core0InternalBehavior/GetMonitorStatus, operation=EvtInfo_AutoCreatedDemEvent_ESH_Action_CancelNvMWriteAll_BswMReportFailToDemRef.GetMonitorStatus
        OpEventGetMonitorStatus_GetMonitorStatus_EvtInfo_AutoCreatedDemEvent_ESH_Action_CancelWriteAllTimer_Start_BswMReportFailToDemRef: start-on-event=DemSatellite_OsApplication_Untrusted_Core0InternalBehavior/GetMonitorStatus, operation=EvtInfo_AutoCreatedDemEvent_ESH_Action_CancelWriteAllTimer_Start_BswMReportFailToDemRef.GetMonitorStatus
        OpEventGetMonitorStatus_GetMonitorStatus_EvtInfo_AutoCreatedDemEvent_ESH_Action_CancelWriteAllTimer_Stop_BswMReportFailToDemRef: start-on-event=DemSatellite_OsApplication_Untrusted_Core0InternalBehavior/GetMonitorStatus, operation=EvtInfo_AutoCreatedDemEvent_ESH_Action_CancelWriteAllTimer_Stop_BswMReportFailToDemRef.GetMonitorStatus
        OpEventGetMonitorStatus_GetMonitorStatus_EvtInfo_AutoCreatedDemEvent_ESH_Action_ComMAllow_CN_Backbone1J1939_0b1f4bae_Bs_2bcad720: start-on-event=DemSatellite_OsApplication_Untrusted_Core0InternalBehavior/GetMonitorStatus, operation=EvtInfo_AutoCreatedDemEvent_ESH_Action_ComMAllow_CN_Backbone1J1939_0b1f4bae_BswMReportFailToDemRef.GetMonitorStatus
        OpEventGetMonitorStatus_GetMonitorStatus_EvtInfo_AutoCreatedDemEvent_ESH_Action_ComMAllow_CN_Backbone1J1939_0b1f4bae_Bs_a0171b41: start-on-event=DemSatellite_OsApplication_Untrusted_Core0InternalBehavior/GetMonitorStatus, operation=EvtInfo_AutoCreatedDemEvent_ESH_Action_ComMAllow_CN_Backbone1J1939_0b1f4bae_BswMReportFailToDemRef_1.GetMonitorStatus
        OpEventGetMonitorStatus_GetMonitorStatus_EvtInfo_AutoCreatedDemEvent_ESH_Action_ComMAllow_CN_Backbone2_78967e2c_BswMRep_99042568: start-on-event=DemSatellite_OsApplication_Untrusted_Core0InternalBehavior/GetMonitorStatus, operation=EvtInfo_AutoCreatedDemEvent_ESH_Action_ComMAllow_CN_Backbone2_78967e2c_BswMReportFailToDemRef.GetMonitorStatus
        OpEventGetMonitorStatus_GetMonitorStatus_EvtInfo_AutoCreatedDemEvent_ESH_Action_ComMAllow_CN_Backbone2_78967e2c_BswMRep_cb04ffb2: start-on-event=DemSatellite_OsApplication_Untrusted_Core0InternalBehavior/GetMonitorStatus, operation=EvtInfo_AutoCreatedDemEvent_ESH_Action_ComMAllow_CN_Backbone2_78967e2c_BswMReportFailToDemRef_1.GetMonitorStatus
        OpEventGetMonitorStatus_GetMonitorStatus_EvtInfo_AutoCreatedDemEvent_ESH_Action_ComMAllow_CN_CabSubnet_9ea693f1_BswMRep_44c6131e: start-on-event=DemSatellite_OsApplication_Untrusted_Core0InternalBehavior/GetMonitorStatus, operation=EvtInfo_AutoCreatedDemEvent_ESH_Action_ComMAllow_CN_CabSubnet_9ea693f1_BswMReportFailToDemRef.GetMonitorStatus
        OpEventGetMonitorStatus_GetMonitorStatus_EvtInfo_AutoCreatedDemEvent_ESH_Action_ComMAllow_CN_CabSubnet_9ea693f1_BswMRep_7ddb6999: start-on-event=DemSatellite_OsApplication_Untrusted_Core0InternalBehavior/GetMonitorStatus, operation=EvtInfo_AutoCreatedDemEvent_ESH_Action_ComMAllow_CN_CabSubnet_9ea693f1_BswMReportFailToDemRef_1.GetMonitorStatus
        OpEventGetMonitorStatus_GetMonitorStatus_EvtInfo_AutoCreatedDemEvent_ESH_Action_ComMAllow_CN_FMSNet_fce1aae5_BswMReport_274479b9: start-on-event=DemSatellite_OsApplication_Untrusted_Core0InternalBehavior/GetMonitorStatus, operation=EvtInfo_AutoCreatedDemEvent_ESH_Action_ComMAllow_CN_FMSNet_fce1aae5_BswMReportFailToDemRef.GetMonitorStatus
        OpEventGetMonitorStatus_GetMonitorStatus_EvtInfo_AutoCreatedDemEvent_ESH_Action_ComMAllow_CN_FMSNet_fce1aae5_BswMReport_31faa873: start-on-event=DemSatellite_OsApplication_Untrusted_Core0InternalBehavior/GetMonitorStatus, operation=EvtInfo_AutoCreatedDemEvent_ESH_Action_ComMAllow_CN_FMSNet_fce1aae5_BswMReportFailToDemRef_1.GetMonitorStatus
        OpEventGetMonitorStatus_GetMonitorStatus_EvtInfo_AutoCreatedDemEvent_ESH_Action_ComMAllow_CN_LIN00_2cd9a7df_BswMReportF_774f4ceb: start-on-event=DemSatellite_OsApplication_Untrusted_Core0InternalBehavior/GetMonitorStatus, operation=EvtInfo_AutoCreatedDemEvent_ESH_Action_ComMAllow_CN_LIN00_2cd9a7df_BswMReportFailToDemRef.GetMonitorStatus
        OpEventGetMonitorStatus_GetMonitorStatus_EvtInfo_AutoCreatedDemEvent_ESH_Action_ComMAllow_CN_LIN00_2cd9a7df_BswMReportF_efc4038d: start-on-event=DemSatellite_OsApplication_Untrusted_Core0InternalBehavior/GetMonitorStatus, operation=EvtInfo_AutoCreatedDemEvent_ESH_Action_ComMAllow_CN_LIN00_2cd9a7df_BswMReportFailToDemRef_1.GetMonitorStatus
        OpEventGetMonitorStatus_GetMonitorStatus_EvtInfo_AutoCreatedDemEvent_ESH_Action_ComMAllow_CN_LIN01_5bde9749_BswMReportF_4fffcb37: start-on-event=DemSatellite_OsApplication_Untrusted_Core0InternalBehavior/GetMonitorStatus, operation=EvtInfo_AutoCreatedDemEvent_ESH_Action_ComMAllow_CN_LIN01_5bde9749_BswMReportFailToDemRef.GetMonitorStatus
        OpEventGetMonitorStatus_GetMonitorStatus_EvtInfo_AutoCreatedDemEvent_ESH_Action_ComMAllow_CN_LIN01_5bde9749_BswMReportF_b195a7ad: start-on-event=DemSatellite_OsApplication_Untrusted_Core0InternalBehavior/GetMonitorStatus, operation=EvtInfo_AutoCreatedDemEvent_ESH_Action_ComMAllow_CN_LIN01_5bde9749_BswMReportFailToDemRef_1.GetMonitorStatus
        OpEventGetMonitorStatus_GetMonitorStatus_EvtInfo_AutoCreatedDemEvent_ESH_Action_ComMAllow_CN_LIN02_c2d7c6f3_BswMReportF_b2823753: start-on-event=DemSatellite_OsApplication_Untrusted_Core0InternalBehavior/GetMonitorStatus, operation=EvtInfo_AutoCreatedDemEvent_ESH_Action_ComMAllow_CN_LIN02_c2d7c6f3_BswMReportFailToDemRef.GetMonitorStatus
        OpEventGetMonitorStatus_GetMonitorStatus_EvtInfo_AutoCreatedDemEvent_ESH_Action_ComMAllow_CN_LIN02_c2d7c6f3_BswMReportF_040f4a44: start-on-event=DemSatellite_OsApplication_Untrusted_Core0InternalBehavior/GetMonitorStatus, operation=EvtInfo_AutoCreatedDemEvent_ESH_Action_ComMAllow_CN_LIN02_c2d7c6f3_BswMReportFailToDemRef_1.GetMonitorStatus
        OpEventGetMonitorStatus_GetMonitorStatus_EvtInfo_AutoCreatedDemEvent_ESH_Action_ComMAllow_CN_LIN03_b5d0f665_BswMReportF_67768bd9: start-on-event=DemSatellite_OsApplication_Untrusted_Core0InternalBehavior/GetMonitorStatus, operation=EvtInfo_AutoCreatedDemEvent_ESH_Action_ComMAllow_CN_LIN03_b5d0f665_BswMReportFailToDemRef.GetMonitorStatus
        OpEventGetMonitorStatus_GetMonitorStatus_EvtInfo_AutoCreatedDemEvent_ESH_Action_ComMAllow_CN_LIN03_b5d0f665_BswMReportF_07b410d6: start-on-event=DemSatellite_OsApplication_Untrusted_Core0InternalBehavior/GetMonitorStatus, operation=EvtInfo_AutoCreatedDemEvent_ESH_Action_ComMAllow_CN_LIN03_b5d0f665_BswMReportFailToDemRef_1.GetMonitorStatus
        OpEventGetMonitorStatus_GetMonitorStatus_EvtInfo_AutoCreatedDemEvent_ESH_Action_ComMAllow_CN_LIN04_2bb463c6_BswMReportF_9838740f: start-on-event=DemSatellite_OsApplication_Untrusted_Core0InternalBehavior/GetMonitorStatus, operation=EvtInfo_AutoCreatedDemEvent_ESH_Action_ComMAllow_CN_LIN04_2bb463c6_BswMReportFailToDemRef.GetMonitorStatus
        OpEventGetMonitorStatus_GetMonitorStatus_EvtInfo_AutoCreatedDemEvent_ESH_Action_ComMAllow_CN_LIN04_2bb463c6_BswMReportF_fdd4628c: start-on-event=DemSatellite_OsApplication_Untrusted_Core0InternalBehavior/GetMonitorStatus, operation=EvtInfo_AutoCreatedDemEvent_ESH_Action_ComMAllow_CN_LIN04_2bb463c6_BswMReportFailToDemRef_1.GetMonitorStatus
        OpEventGetMonitorStatus_GetMonitorStatus_EvtInfo_AutoCreatedDemEvent_ESH_Action_ComMAllow_CN_SecuritySubnet_e7a0ee54_Bs_854056e6: start-on-event=DemSatellite_OsApplication_Untrusted_Core0InternalBehavior/GetMonitorStatus, operation=EvtInfo_AutoCreatedDemEvent_ESH_Action_ComMAllow_CN_SecuritySubnet_e7a0ee54_BswMReportFailToDemRef.GetMonitorStatus
        OpEventGetMonitorStatus_GetMonitorStatus_EvtInfo_AutoCreatedDemEvent_ESH_Action_ComMAllow_CN_SecuritySubnet_e7a0ee54_Bs_a70876b5: start-on-event=DemSatellite_OsApplication_Untrusted_Core0InternalBehavior/GetMonitorStatus, operation=EvtInfo_AutoCreatedDemEvent_ESH_Action_ComMAllow_CN_SecuritySubnet_e7a0ee54_BswMReportFailToDemRef_1.GetMonitorStatus
        OpEventGetMonitorStatus_GetMonitorStatus_EvtInfo_AutoCreatedDemEvent_ESH_Action_ComMCheckPendingRequests_BswMReportFail_544f18c4: start-on-event=DemSatellite_OsApplication_Untrusted_Core0InternalBehavior/GetMonitorStatus, operation=EvtInfo_AutoCreatedDemEvent_ESH_Action_ComMCheckPendingRequests_BswMReportFailToDemRef_1.GetMonitorStatus
        OpEventGetMonitorStatus_GetMonitorStatus_EvtInfo_AutoCreatedDemEvent_ESH_Action_ComMCheckPendingRequests_BswMReportFail_cd46497e: start-on-event=DemSatellite_OsApplication_Untrusted_Core0InternalBehavior/GetMonitorStatus, operation=EvtInfo_AutoCreatedDemEvent_ESH_Action_ComMCheckPendingRequests_BswMReportFailToDemRef_2.GetMonitorStatus
        OpEventGetMonitorStatus_GetMonitorStatus_EvtInfo_AutoCreatedDemEvent_ESH_Action_ComMDisallow_CN_Backbone1J1939_0b1f4bae_f7ba0909: start-on-event=DemSatellite_OsApplication_Untrusted_Core0InternalBehavior/GetMonitorStatus, operation=EvtInfo_AutoCreatedDemEvent_ESH_Action_ComMDisallow_CN_Backbone1J1939_0b1f4bae_BswMReportFailToDemRef.GetMonitorStatus
        OpEventGetMonitorStatus_GetMonitorStatus_EvtInfo_AutoCreatedDemEvent_ESH_Action_ComMDisallow_CN_Backbone2_78967e2c_BswM_796a69a5: start-on-event=DemSatellite_OsApplication_Untrusted_Core0InternalBehavior/GetMonitorStatus, operation=EvtInfo_AutoCreatedDemEvent_ESH_Action_ComMDisallow_CN_Backbone2_78967e2c_BswMReportFailToDemRef.GetMonitorStatus
        OpEventGetMonitorStatus_GetMonitorStatus_EvtInfo_AutoCreatedDemEvent_ESH_Action_ComMDisallow_CN_CabSubnet_9ea693f1_BswM_a4a85fd3: start-on-event=DemSatellite_OsApplication_Untrusted_Core0InternalBehavior/GetMonitorStatus, operation=EvtInfo_AutoCreatedDemEvent_ESH_Action_ComMDisallow_CN_CabSubnet_9ea693f1_BswMReportFailToDemRef.GetMonitorStatus
        OpEventGetMonitorStatus_GetMonitorStatus_EvtInfo_AutoCreatedDemEvent_ESH_Action_ComMDisallow_CN_FMSNet_fce1aae5_BswMRep_62278651: start-on-event=DemSatellite_OsApplication_Untrusted_Core0InternalBehavior/GetMonitorStatus, operation=EvtInfo_AutoCreatedDemEvent_ESH_Action_ComMDisallow_CN_FMSNet_fce1aae5_BswMReportFailToDemRef.GetMonitorStatus
        OpEventGetMonitorStatus_GetMonitorStatus_EvtInfo_AutoCreatedDemEvent_ESH_Action_ComMDisallow_CN_LIN00_2cd9a7df_BswMRepo_cbecd1c6: start-on-event=DemSatellite_OsApplication_Untrusted_Core0InternalBehavior/GetMonitorStatus, operation=EvtInfo_AutoCreatedDemEvent_ESH_Action_ComMDisallow_CN_LIN00_2cd9a7df_BswMReportFailToDemRef.GetMonitorStatus
        OpEventGetMonitorStatus_GetMonitorStatus_EvtInfo_AutoCreatedDemEvent_ESH_Action_ComMDisallow_CN_LIN01_5bde9749_BswMRepo_f35c561a: start-on-event=DemSatellite_OsApplication_Untrusted_Core0InternalBehavior/GetMonitorStatus, operation=EvtInfo_AutoCreatedDemEvent_ESH_Action_ComMDisallow_CN_LIN01_5bde9749_BswMReportFailToDemRef.GetMonitorStatus
        OpEventGetMonitorStatus_GetMonitorStatus_EvtInfo_AutoCreatedDemEvent_ESH_Action_ComMDisallow_CN_LIN02_c2d7c6f3_BswMRepo_0e21aa7e: start-on-event=DemSatellite_OsApplication_Untrusted_Core0InternalBehavior/GetMonitorStatus, operation=EvtInfo_AutoCreatedDemEvent_ESH_Action_ComMDisallow_CN_LIN02_c2d7c6f3_BswMReportFailToDemRef.GetMonitorStatus
        OpEventGetMonitorStatus_GetMonitorStatus_EvtInfo_AutoCreatedDemEvent_ESH_Action_ComMDisallow_CN_LIN03_b5d0f665_BswMRepo_dbd516f4: start-on-event=DemSatellite_OsApplication_Untrusted_Core0InternalBehavior/GetMonitorStatus, operation=EvtInfo_AutoCreatedDemEvent_ESH_Action_ComMDisallow_CN_LIN03_b5d0f665_BswMReportFailToDemRef.GetMonitorStatus
        OpEventGetMonitorStatus_GetMonitorStatus_EvtInfo_AutoCreatedDemEvent_ESH_Action_ComMDisallow_CN_LIN04_2bb463c6_BswMRepo_249be922: start-on-event=DemSatellite_OsApplication_Untrusted_Core0InternalBehavior/GetMonitorStatus, operation=EvtInfo_AutoCreatedDemEvent_ESH_Action_ComMDisallow_CN_LIN04_2bb463c6_BswMReportFailToDemRef.GetMonitorStatus
        OpEventGetMonitorStatus_GetMonitorStatus_EvtInfo_AutoCreatedDemEvent_ESH_Action_ComMDisallow_CN_SecuritySubnet_e7a0ee54_593088cf: start-on-event=DemSatellite_OsApplication_Untrusted_Core0InternalBehavior/GetMonitorStatus, operation=EvtInfo_AutoCreatedDemEvent_ESH_Action_ComMDisallow_CN_SecuritySubnet_e7a0ee54_BswMReportFailToDemRef.GetMonitorStatus
        OpEventGetMonitorStatus_GetMonitorStatus_EvtInfo_AutoCreatedDemEvent_ESH_Action_DemInit_BswMReportFailToDemRef: start-on-event=DemSatellite_OsApplication_Untrusted_Core0InternalBehavior/GetMonitorStatus, operation=EvtInfo_AutoCreatedDemEvent_ESH_Action_DemInit_BswMReportFailToDemRef.GetMonitorStatus
        OpEventGetMonitorStatus_GetMonitorStatus_EvtInfo_AutoCreatedDemEvent_ESH_Action_DemInitialized_BswMReportFailToDemRef: start-on-event=DemSatellite_OsApplication_Untrusted_Core0InternalBehavior/GetMonitorStatus, operation=EvtInfo_AutoCreatedDemEvent_ESH_Action_DemInitialized_BswMReportFailToDemRef.GetMonitorStatus
        OpEventGetMonitorStatus_GetMonitorStatus_EvtInfo_AutoCreatedDemEvent_ESH_Action_DemNotInitialized_BswMReportFailToDemRef: start-on-event=DemSatellite_OsApplication_Untrusted_Core0InternalBehavior/GetMonitorStatus, operation=EvtInfo_AutoCreatedDemEvent_ESH_Action_DemNotInitialized_BswMReportFailToDemRef.GetMonitorStatus
        OpEventGetMonitorStatus_GetMonitorStatus_EvtInfo_AutoCreatedDemEvent_ESH_Action_DemShutdown_BswMReportFailToDemRef: start-on-event=DemSatellite_OsApplication_Untrusted_Core0InternalBehavior/GetMonitorStatus, operation=EvtInfo_AutoCreatedDemEvent_ESH_Action_DemShutdown_BswMReportFailToDemRef.GetMonitorStatus
        OpEventGetMonitorStatus_GetMonitorStatus_EvtInfo_AutoCreatedDemEvent_ESH_Action_ESH_PostRun_BswMReportFailToDemRef: start-on-event=DemSatellite_OsApplication_Untrusted_Core0InternalBehavior/GetMonitorStatus, operation=EvtInfo_AutoCreatedDemEvent_ESH_Action_ESH_PostRun_BswMReportFailToDemRef.GetMonitorStatus
        OpEventGetMonitorStatus_GetMonitorStatus_EvtInfo_AutoCreatedDemEvent_ESH_Action_ESH_PrepShutdown_BswMReportFailToDemRef: start-on-event=DemSatellite_OsApplication_Untrusted_Core0InternalBehavior/GetMonitorStatus, operation=EvtInfo_AutoCreatedDemEvent_ESH_Action_ESH_PrepShutdown_BswMReportFailToDemRef.GetMonitorStatus
        OpEventGetMonitorStatus_GetMonitorStatus_EvtInfo_AutoCreatedDemEvent_ESH_Action_ESH_PrepShutdown_BswMReportFailToDemRef_1: start-on-event=DemSatellite_OsApplication_Untrusted_Core0InternalBehavior/GetMonitorStatus, operation=EvtInfo_AutoCreatedDemEvent_ESH_Action_ESH_PrepShutdown_BswMReportFailToDemRef_1.GetMonitorStatus
        OpEventGetMonitorStatus_GetMonitorStatus_EvtInfo_AutoCreatedDemEvent_ESH_Action_ESH_Run_BswMReportFailToDemRef: start-on-event=DemSatellite_OsApplication_Untrusted_Core0InternalBehavior/GetMonitorStatus, operation=EvtInfo_AutoCreatedDemEvent_ESH_Action_ESH_Run_BswMReportFailToDemRef.GetMonitorStatus
        OpEventGetMonitorStatus_GetMonitorStatus_EvtInfo_AutoCreatedDemEvent_ESH_Action_ESH_Run_BswMReportFailToDemRef_1: start-on-event=DemSatellite_OsApplication_Untrusted_Core0InternalBehavior/GetMonitorStatus, operation=EvtInfo_AutoCreatedDemEvent_ESH_Action_ESH_Run_BswMReportFailToDemRef_1.GetMonitorStatus
        OpEventGetMonitorStatus_GetMonitorStatus_EvtInfo_AutoCreatedDemEvent_ESH_Action_ESH_WaitForNvm_BswMReportFailToDemRef: start-on-event=DemSatellite_OsApplication_Untrusted_Core0InternalBehavior/GetMonitorStatus, operation=EvtInfo_AutoCreatedDemEvent_ESH_Action_ESH_WaitForNvm_BswMReportFailToDemRef.GetMonitorStatus
        OpEventGetMonitorStatus_GetMonitorStatus_EvtInfo_AutoCreatedDemEvent_ESH_Action_ESH_Wakeup_BswMReportFailToDemRef: start-on-event=DemSatellite_OsApplication_Untrusted_Core0InternalBehavior/GetMonitorStatus, operation=EvtInfo_AutoCreatedDemEvent_ESH_Action_ESH_Wakeup_BswMReportFailToDemRef.GetMonitorStatus
        OpEventGetMonitorStatus_GetMonitorStatus_EvtInfo_AutoCreatedDemEvent_ESH_Action_ESH_Wakeup_BswMReportFailToDemRef_1: start-on-event=DemSatellite_OsApplication_Untrusted_Core0InternalBehavior/GetMonitorStatus, operation=EvtInfo_AutoCreatedDemEvent_ESH_Action_ESH_Wakeup_BswMReportFailToDemRef_1.GetMonitorStatus
        OpEventGetMonitorStatus_GetMonitorStatus_EvtInfo_AutoCreatedDemEvent_ESH_Action_EcuMClearValidatedWakeupEvents_BswMRepo_c2cba453: start-on-event=DemSatellite_OsApplication_Untrusted_Core0InternalBehavior/GetMonitorStatus, operation=EvtInfo_AutoCreatedDemEvent_ESH_Action_EcuMClearValidatedWakeupEvents_BswMReportFailToDemRef.GetMonitorStatus
        OpEventGetMonitorStatus_GetMonitorStatus_EvtInfo_AutoCreatedDemEvent_ESH_Action_EcuMGoToSelectedShutdownTarget_BswMRepo_63811485: start-on-event=DemSatellite_OsApplication_Untrusted_Core0InternalBehavior/GetMonitorStatus, operation=EvtInfo_AutoCreatedDemEvent_ESH_Action_EcuMGoToSelectedShutdownTarget_BswMReportFailToDemRef.GetMonitorStatus
        OpEventGetMonitorStatus_GetMonitorStatus_EvtInfo_AutoCreatedDemEvent_ESH_Action_EnterExclusiveArea_BswMReportFailToDemRef_1: start-on-event=DemSatellite_OsApplication_Untrusted_Core0InternalBehavior/GetMonitorStatus, operation=EvtInfo_AutoCreatedDemEvent_ESH_Action_EnterExclusiveArea_BswMReportFailToDemRef_1.GetMonitorStatus
        OpEventGetMonitorStatus_GetMonitorStatus_EvtInfo_AutoCreatedDemEvent_ESH_Action_ExitExclusiveArea_BswMReportFailToDemRef: start-on-event=DemSatellite_OsApplication_Untrusted_Core0InternalBehavior/GetMonitorStatus, operation=EvtInfo_AutoCreatedDemEvent_ESH_Action_ExitExclusiveArea_BswMReportFailToDemRef.GetMonitorStatus
        OpEventGetMonitorStatus_GetMonitorStatus_EvtInfo_AutoCreatedDemEvent_ESH_Action_NvMWriteAll_BswMReportFailToDemRef: start-on-event=DemSatellite_OsApplication_Untrusted_Core0InternalBehavior/GetMonitorStatus, operation=EvtInfo_AutoCreatedDemEvent_ESH_Action_NvMWriteAll_BswMReportFailToDemRef.GetMonitorStatus
        OpEventGetMonitorStatus_GetMonitorStatus_EvtInfo_AutoCreatedDemEvent_ESH_Action_OnEnterPostRun_BswMReportFailToDemRef: start-on-event=DemSatellite_OsApplication_Untrusted_Core0InternalBehavior/GetMonitorStatus, operation=EvtInfo_AutoCreatedDemEvent_ESH_Action_OnEnterPostRun_BswMReportFailToDemRef.GetMonitorStatus
        OpEventGetMonitorStatus_GetMonitorStatus_EvtInfo_AutoCreatedDemEvent_ESH_Action_OnEnterPrepShutdown_BswMReportFailToDemRef: start-on-event=DemSatellite_OsApplication_Untrusted_Core0InternalBehavior/GetMonitorStatus, operation=EvtInfo_AutoCreatedDemEvent_ESH_Action_OnEnterPrepShutdown_BswMReportFailToDemRef.GetMonitorStatus
        OpEventGetMonitorStatus_GetMonitorStatus_EvtInfo_AutoCreatedDemEvent_ESH_Action_OnEnterPrepShutdown_BswMReportFailToDemRef_1: start-on-event=DemSatellite_OsApplication_Untrusted_Core0InternalBehavior/GetMonitorStatus, operation=EvtInfo_AutoCreatedDemEvent_ESH_Action_OnEnterPrepShutdown_BswMReportFailToDemRef_1.GetMonitorStatus
        OpEventGetMonitorStatus_GetMonitorStatus_EvtInfo_AutoCreatedDemEvent_ESH_Action_OnEnterRun_BswMReportFailToDemRef: start-on-event=DemSatellite_OsApplication_Untrusted_Core0InternalBehavior/GetMonitorStatus, operation=EvtInfo_AutoCreatedDemEvent_ESH_Action_OnEnterRun_BswMReportFailToDemRef.GetMonitorStatus
        OpEventGetMonitorStatus_GetMonitorStatus_EvtInfo_AutoCreatedDemEvent_ESH_Action_OnEnterRun_BswMReportFailToDemRef_1: start-on-event=DemSatellite_OsApplication_Untrusted_Core0InternalBehavior/GetMonitorStatus, operation=EvtInfo_AutoCreatedDemEvent_ESH_Action_OnEnterRun_BswMReportFailToDemRef_1.GetMonitorStatus
        OpEventGetMonitorStatus_GetMonitorStatus_EvtInfo_AutoCreatedDemEvent_ESH_Action_OnEnterShutdown_BswMReportFailToDemRef: start-on-event=DemSatellite_OsApplication_Untrusted_Core0InternalBehavior/GetMonitorStatus, operation=EvtInfo_AutoCreatedDemEvent_ESH_Action_OnEnterShutdown_BswMReportFailToDemRef.GetMonitorStatus
        OpEventGetMonitorStatus_GetMonitorStatus_EvtInfo_AutoCreatedDemEvent_ESH_Action_OnEnterWaitForNvm_BswMReportFailToDemRef: start-on-event=DemSatellite_OsApplication_Untrusted_Core0InternalBehavior/GetMonitorStatus, operation=EvtInfo_AutoCreatedDemEvent_ESH_Action_OnEnterWaitForNvm_BswMReportFailToDemRef.GetMonitorStatus
        OpEventGetMonitorStatus_GetMonitorStatus_EvtInfo_AutoCreatedDemEvent_ESH_Action_OnEnterWakeup_BswMReportFailToDemRef: start-on-event=DemSatellite_OsApplication_Untrusted_Core0InternalBehavior/GetMonitorStatus, operation=EvtInfo_AutoCreatedDemEvent_ESH_Action_OnEnterWakeup_BswMReportFailToDemRef.GetMonitorStatus
        OpEventGetMonitorStatus_GetMonitorStatus_EvtInfo_AutoCreatedDemEvent_ESH_Action_OnEnterWakeup_BswMReportFailToDemRef_1: start-on-event=DemSatellite_OsApplication_Untrusted_Core0InternalBehavior/GetMonitorStatus, operation=EvtInfo_AutoCreatedDemEvent_ESH_Action_OnEnterWakeup_BswMReportFailToDemRef_1.GetMonitorStatus
        OpEventGetMonitorStatus_GetMonitorStatus_EvtInfo_AutoCreatedDemEvent_ESH_Action_SelfRunRequestTimer_Start_BswMReportFailToDemRef: start-on-event=DemSatellite_OsApplication_Untrusted_Core0InternalBehavior/GetMonitorStatus, operation=EvtInfo_AutoCreatedDemEvent_ESH_Action_SelfRunRequestTimer_Start_BswMReportFailToDemRef.GetMonitorStatus
        OpEventGetMonitorStatus_GetMonitorStatus_EvtInfo_AutoCreatedDemEvent_ESH_Action_SelfRunRequestTimer_Start_BswMReportFai_9039ba94: start-on-event=DemSatellite_OsApplication_Untrusted_Core0InternalBehavior/GetMonitorStatus, operation=EvtInfo_AutoCreatedDemEvent_ESH_Action_SelfRunRequestTimer_Start_BswMReportFailToDemRef_1.GetMonitorStatus
        OpEventGetMonitorStatus_GetMonitorStatus_EvtInfo_AutoCreatedDemEvent_ESH_Action_SwitchPostRun_BswMReportFailToDemRef: start-on-event=DemSatellite_OsApplication_Untrusted_Core0InternalBehavior/GetMonitorStatus, operation=EvtInfo_AutoCreatedDemEvent_ESH_Action_SwitchPostRun_BswMReportFailToDemRef.GetMonitorStatus
        OpEventGetMonitorStatus_GetMonitorStatus_EvtInfo_AutoCreatedDemEvent_ESH_Action_SwitchRun_BswMReportFailToDemRef: start-on-event=DemSatellite_OsApplication_Untrusted_Core0InternalBehavior/GetMonitorStatus, operation=EvtInfo_AutoCreatedDemEvent_ESH_Action_SwitchRun_BswMReportFailToDemRef.GetMonitorStatus
        OpEventGetMonitorStatus_GetMonitorStatus_EvtInfo_AutoCreatedDemEvent_ESH_Action_SwitchRun_BswMReportFailToDemRef_1: start-on-event=DemSatellite_OsApplication_Untrusted_Core0InternalBehavior/GetMonitorStatus, operation=EvtInfo_AutoCreatedDemEvent_ESH_Action_SwitchRun_BswMReportFailToDemRef_1.GetMonitorStatus
        OpEventGetMonitorStatus_GetMonitorStatus_EvtInfo_AutoCreatedDemEvent_ESH_Action_SwitchShutdown_BswMReportFailToDemRef: start-on-event=DemSatellite_OsApplication_Untrusted_Core0InternalBehavior/GetMonitorStatus, operation=EvtInfo_AutoCreatedDemEvent_ESH_Action_SwitchShutdown_BswMReportFailToDemRef.GetMonitorStatus
        OpEventGetMonitorStatus_GetMonitorStatus_EvtInfo_AutoCreatedDemEvent_ESH_Action_SwitchShutdown_BswMReportFailToDemRef_1: start-on-event=DemSatellite_OsApplication_Untrusted_Core0InternalBehavior/GetMonitorStatus, operation=EvtInfo_AutoCreatedDemEvent_ESH_Action_SwitchShutdown_BswMReportFailToDemRef_1.GetMonitorStatus
        OpEventGetMonitorStatus_GetMonitorStatus_EvtInfo_AutoCreatedDemEvent_ESH_Action_SwitchWakeup_BswMReportFailToDemRef: start-on-event=DemSatellite_OsApplication_Untrusted_Core0InternalBehavior/GetMonitorStatus, operation=EvtInfo_AutoCreatedDemEvent_ESH_Action_SwitchWakeup_BswMReportFailToDemRef.GetMonitorStatus
        OpEventGetMonitorStatus_GetMonitorStatus_EvtInfo_AutoCreatedDemEvent_ESH_Action_SwitchWakeup_BswMReportFailToDemRef_1: start-on-event=DemSatellite_OsApplication_Untrusted_Core0InternalBehavior/GetMonitorStatus, operation=EvtInfo_AutoCreatedDemEvent_ESH_Action_SwitchWakeup_BswMReportFailToDemRef_1.GetMonitorStatus
        OpEventGetMonitorStatus_GetMonitorStatus_EvtInfo_AutoCreatedDemEvent_ESH_Action_WriteAllTimer_Start_BswMReportFailToDemRef: start-on-event=DemSatellite_OsApplication_Untrusted_Core0InternalBehavior/GetMonitorStatus, operation=EvtInfo_AutoCreatedDemEvent_ESH_Action_WriteAllTimer_Start_BswMReportFailToDemRef.GetMonitorStatus
        OpEventGetMonitorStatus_GetMonitorStatus_EvtInfo_AutoCreatedDemEvent_ESH_Action_WriteAllTimer_Stop_BswMReportFailToDemRef: start-on-event=DemSatellite_OsApplication_Untrusted_Core0InternalBehavior/GetMonitorStatus, operation=EvtInfo_AutoCreatedDemEvent_ESH_Action_WriteAllTimer_Stop_BswMReportFailToDemRef.GetMonitorStatus
        OpEventGetMonitorStatus_GetMonitorStatus_EvtInfo_AutoCreatedDemEvent_ESH_Action_WriteAllTimer_Stop_BswMReportFailToDemRef_1: start-on-event=DemSatellite_OsApplication_Untrusted_Core0InternalBehavior/GetMonitorStatus, operation=EvtInfo_AutoCreatedDemEvent_ESH_Action_WriteAllTimer_Stop_BswMReportFailToDemRef_1.GetMonitorStatus
        OpEventGetMonitorStatus_GetMonitorStatus_EvtInfo_AutoCreatedDemEvent_ESH_DemInit_BswMReportFailToDemRef: start-on-event=DemSatellite_OsApplication_Untrusted_Core0InternalBehavior/GetMonitorStatus, operation=EvtInfo_AutoCreatedDemEvent_ESH_DemInit_BswMReportFailToDemRef.GetMonitorStatus
        OpEventGetMonitorStatus_GetMonitorStatus_EvtInfo_AutoCreatedDemEvent_ESH_PostRunNested_BswMReportFailToDemRef: start-on-event=DemSatellite_OsApplication_Untrusted_Core0InternalBehavior/GetMonitorStatus, operation=EvtInfo_AutoCreatedDemEvent_ESH_PostRunNested_BswMReportFailToDemRef.GetMonitorStatus
        OpEventGetMonitorStatus_GetMonitorStatus_EvtInfo_AutoCreatedDemEvent_ESH_PostRunToPrepNested_BswMReportFailToDemRef: start-on-event=DemSatellite_OsApplication_Untrusted_Core0InternalBehavior/GetMonitorStatus, operation=EvtInfo_AutoCreatedDemEvent_ESH_PostRunToPrepNested_BswMReportFailToDemRef.GetMonitorStatus
        OpEventGetMonitorStatus_GetMonitorStatus_EvtInfo_AutoCreatedDemEvent_ESH_Action_ExitExclusiveArea_BswMReportFailToDemRef_1: start-on-event=DemSatellite_OsApplication_Untrusted_Core0InternalBehavior/GetMonitorStatus, operation=EvtInfo_AutoCreatedDemEvent_ESH_Action_ExitExclusiveArea_BswMReportFailToDemRef_1.GetMonitorStatus
        OpEventGetMonitorStatus_GetMonitorStatus_EvtInfo_AutoCreatedDemEvent_INIT_Action_BrsHw_EnableHwAccess_BswMReportFailToDemRef: start-on-event=DemSatellite_OsApplication_Untrusted_Core0InternalBehavior/GetMonitorStatus, operation=EvtInfo_AutoCreatedDemEvent_INIT_Action_BrsHw_EnableHwAccess_BswMReportFailToDemRef.GetMonitorStatus
        OpEventGetMonitorStatus_GetMonitorStatus_EvtInfo_AutoCreatedDemEvent_INIT_Action_CanIf_Init_BswMReportFailToDemRef: start-on-event=DemSatellite_OsApplication_Untrusted_Core0InternalBehavior/GetMonitorStatus, operation=EvtInfo_AutoCreatedDemEvent_INIT_Action_CanIf_Init_BswMReportFailToDemRef.GetMonitorStatus
        OpEventGetMonitorStatus_GetMonitorStatus_EvtInfo_AutoCreatedDemEvent_INIT_Action_CanNm_Init_BswMReportFailToDemRef: start-on-event=DemSatellite_OsApplication_Untrusted_Core0InternalBehavior/GetMonitorStatus, operation=EvtInfo_AutoCreatedDemEvent_INIT_Action_CanNm_Init_BswMReportFailToDemRef.GetMonitorStatus
        OpEventGetMonitorStatus_GetMonitorStatus_EvtInfo_AutoCreatedDemEvent_INIT_Action_CanSM_Init_BswMReportFailToDemRef: start-on-event=DemSatellite_OsApplication_Untrusted_Core0InternalBehavior/GetMonitorStatus, operation=EvtInfo_AutoCreatedDemEvent_INIT_Action_CanSM_Init_BswMReportFailToDemRef.GetMonitorStatus
        OpEventGetMonitorStatus_GetMonitorStatus_EvtInfo_AutoCreatedDemEvent_INIT_Action_CanTp_Init_BswMReportFailToDemRef: start-on-event=DemSatellite_OsApplication_Untrusted_Core0InternalBehavior/GetMonitorStatus, operation=EvtInfo_AutoCreatedDemEvent_INIT_Action_CanTp_Init_BswMReportFailToDemRef.GetMonitorStatus
        OpEventGetMonitorStatus_GetMonitorStatus_EvtInfo_AutoCreatedDemEvent_INIT_Action_Can_Init_BswMReportFailToDemRef: start-on-event=DemSatellite_OsApplication_Untrusted_Core0InternalBehavior/GetMonitorStatus, operation=EvtInfo_AutoCreatedDemEvent_INIT_Action_Can_Init_BswMReportFailToDemRef.GetMonitorStatus
        OpEventGetMonitorStatus_GetMonitorStatus_EvtInfo_AutoCreatedDemEvent_INIT_Action_ComM_Init_BswMReportFailToDemRef: start-on-event=DemSatellite_OsApplication_Untrusted_Core0InternalBehavior/GetMonitorStatus, operation=EvtInfo_AutoCreatedDemEvent_INIT_Action_ComM_Init_BswMReportFailToDemRef.GetMonitorStatus
        OpEventGetMonitorStatus_GetMonitorStatus_EvtInfo_AutoCreatedDemEvent_INIT_Action_Com_Init_BswMReportFailToDemRef: start-on-event=DemSatellite_OsApplication_Untrusted_Core0InternalBehavior/GetMonitorStatus, operation=EvtInfo_AutoCreatedDemEvent_INIT_Action_Com_Init_BswMReportFailToDemRef.GetMonitorStatus
        OpEventGetMonitorStatus_GetMonitorStatus_EvtInfo_AutoCreatedDemEvent_INIT_Action_Dcm_Init_BswMReportFailToDemRef: start-on-event=DemSatellite_OsApplication_Untrusted_Core0InternalBehavior/GetMonitorStatus, operation=EvtInfo_AutoCreatedDemEvent_INIT_Action_Dcm_Init_BswMReportFailToDemRef.GetMonitorStatus
        OpEventGetMonitorStatus_GetMonitorStatus_EvtInfo_AutoCreatedDemEvent_INIT_Action_Dem_Init_BswMReportFailToDemRef: start-on-event=DemSatellite_OsApplication_Untrusted_Core0InternalBehavior/GetMonitorStatus, operation=EvtInfo_AutoCreatedDemEvent_INIT_Action_Dem_Init_BswMReportFailToDemRef.GetMonitorStatus
        OpEventGetMonitorStatus_GetMonitorStatus_EvtInfo_AutoCreatedDemEvent_INIT_Action_EnableInterrupts_BswMReportFailToDemRef: start-on-event=DemSatellite_OsApplication_Untrusted_Core0InternalBehavior/GetMonitorStatus, operation=EvtInfo_AutoCreatedDemEvent_INIT_Action_EnableInterrupts_BswMReportFailToDemRef.GetMonitorStatus
        OpEventGetMonitorStatus_GetMonitorStatus_EvtInfo_AutoCreatedDemEvent_INIT_Action_Fee_Init_BswMReportFailToDemRef: start-on-event=DemSatellite_OsApplication_Untrusted_Core0InternalBehavior/GetMonitorStatus, operation=EvtInfo_AutoCreatedDemEvent_INIT_Action_Fee_Init_BswMReportFailToDemRef.GetMonitorStatus
        OpEventGetMonitorStatus_GetMonitorStatus_EvtInfo_AutoCreatedDemEvent_INIT_Action_Issm_Init_BswMReportFailToDemRef: start-on-event=DemSatellite_OsApplication_Untrusted_Core0InternalBehavior/GetMonitorStatus, operation=EvtInfo_AutoCreatedDemEvent_INIT_Action_Issm_Init_BswMReportFailToDemRef.GetMonitorStatus
        OpEventGetMonitorStatus_GetMonitorStatus_EvtInfo_AutoCreatedDemEvent_INIT_Action_J1939Nm_Init_BswMReportFailToDemRef: start-on-event=DemSatellite_OsApplication_Untrusted_Core0InternalBehavior/GetMonitorStatus, operation=EvtInfo_AutoCreatedDemEvent_INIT_Action_J1939Nm_Init_BswMReportFailToDemRef.GetMonitorStatus
        OpEventGetMonitorStatus_GetMonitorStatus_EvtInfo_AutoCreatedDemEvent_INIT_Action_J1939Rm_Init_BswMReportFailToDemRef: start-on-event=DemSatellite_OsApplication_Untrusted_Core0InternalBehavior/GetMonitorStatus, operation=EvtInfo_AutoCreatedDemEvent_INIT_Action_J1939Rm_Init_BswMReportFailToDemRef.GetMonitorStatus
        OpEventGetMonitorStatus_GetMonitorStatus_EvtInfo_AutoCreatedDemEvent_INIT_Action_J1939Tp_Init_BswMReportFailToDemRef: start-on-event=DemSatellite_OsApplication_Untrusted_Core0InternalBehavior/GetMonitorStatus, operation=EvtInfo_AutoCreatedDemEvent_INIT_Action_J1939Tp_Init_BswMReportFailToDemRef.GetMonitorStatus
        OpEventGetMonitorStatus_GetMonitorStatus_EvtInfo_AutoCreatedDemEvent_INIT_Action_LinIf_Init_BswMReportFailToDemRef: start-on-event=DemSatellite_OsApplication_Untrusted_Core0InternalBehavior/GetMonitorStatus, operation=EvtInfo_AutoCreatedDemEvent_INIT_Action_LinIf_Init_BswMReportFailToDemRef.GetMonitorStatus
        OpEventGetMonitorStatus_GetMonitorStatus_EvtInfo_AutoCreatedDemEvent_INIT_Action_LinSM_Init_BswMReportFailToDemRef: start-on-event=DemSatellite_OsApplication_Untrusted_Core0InternalBehavior/GetMonitorStatus, operation=EvtInfo_AutoCreatedDemEvent_INIT_Action_LinSM_Init_BswMReportFailToDemRef.GetMonitorStatus
        OpEventGetMonitorStatus_GetMonitorStatus_EvtInfo_AutoCreatedDemEvent_INIT_Action_LinTp_Init_BswMReportFailToDemRef: start-on-event=DemSatellite_OsApplication_Untrusted_Core0InternalBehavior/GetMonitorStatus, operation=EvtInfo_AutoCreatedDemEvent_INIT_Action_LinTp_Init_BswMReportFailToDemRef.GetMonitorStatus
        OpEventGetMonitorStatus_GetMonitorStatus_EvtInfo_AutoCreatedDemEvent_INIT_Action_Lin_Init_BswMReportFailToDemRef: start-on-event=DemSatellite_OsApplication_Untrusted_Core0InternalBehavior/GetMonitorStatus, operation=EvtInfo_AutoCreatedDemEvent_INIT_Action_Lin_Init_BswMReportFailToDemRef.GetMonitorStatus
        OpEventGetMonitorStatus_GetMonitorStatus_EvtInfo_AutoCreatedDemEvent_INIT_Action_Nm_Init_BswMReportFailToDemRef: start-on-event=DemSatellite_OsApplication_Untrusted_Core0InternalBehavior/GetMonitorStatus, operation=EvtInfo_AutoCreatedDemEvent_INIT_Action_Nm_Init_BswMReportFailToDemRef.GetMonitorStatus
        OpEventGetMonitorStatus_GetMonitorStatus_EvtInfo_AutoCreatedDemEvent_INIT_Action_NvMReadAll_BswMReportFailToDemRef: start-on-event=DemSatellite_OsApplication_Untrusted_Core0InternalBehavior/GetMonitorStatus, operation=EvtInfo_AutoCreatedDemEvent_INIT_Action_NvMReadAll_BswMReportFailToDemRef.GetMonitorStatus
        OpEventGetMonitorStatus_GetMonitorStatus_EvtInfo_AutoCreatedDemEvent_INIT_Action_NvM_Init_BswMReportFailToDemRef: start-on-event=DemSatellite_OsApplication_Untrusted_Core0InternalBehavior/GetMonitorStatus, operation=EvtInfo_AutoCreatedDemEvent_INIT_Action_NvM_Init_BswMReportFailToDemRef.GetMonitorStatus
        OpEventGetMonitorStatus_GetMonitorStatus_EvtInfo_AutoCreatedDemEvent_INIT_Action_PduR_Init_BswMReportFailToDemRef: start-on-event=DemSatellite_OsApplication_Untrusted_Core0InternalBehavior/GetMonitorStatus, operation=EvtInfo_AutoCreatedDemEvent_INIT_Action_PduR_Init_BswMReportFailToDemRef.GetMonitorStatus
        OpEventGetMonitorStatus_GetMonitorStatus_EvtInfo_AutoCreatedDemEvent_INIT_Action_RteStart_BswMReportFailToDemRef: start-on-event=DemSatellite_OsApplication_Untrusted_Core0InternalBehavior/GetMonitorStatus, operation=EvtInfo_AutoCreatedDemEvent_INIT_Action_RteStart_BswMReportFailToDemRef.GetMonitorStatus
        OpEventGetMonitorStatus_GetMonitorStatus_EvtInfo_AutoCreatedDemEvent_CHNL_17344684_CANSM_E_MODE_REQUEST_TIMEOUT: start-on-event=DemSatellite_OsApplication_Untrusted_Core0InternalBehavior/GetMonitorStatus, operation=EvtInfo_AutoCreatedDemEvent_CHNL_17344684_CANSM_E_MODE_REQUEST_TIMEOUT.GetMonitorStatus
        OpEventGetMonitorStatus_GetMonitorStatus_EvtInfo_AutoCreatedDemEvent_CHNL_17344684_CANSM_E_BUS_OFF: start-on-event=DemSatellite_OsApplication_Untrusted_Core0InternalBehavior/GetMonitorStatus, operation=EvtInfo_AutoCreatedDemEvent_CHNL_17344684_CANSM_E_BUS_OFF.GetMonitorStatus
        OpEventGetMonitorStatus_GetMonitorStatus_EvtInfo_AutoCreatedDemEvent_CHNL_53cce282_CANSM_E_MODE_REQUEST_TIMEOUT: start-on-event=DemSatellite_OsApplication_Untrusted_Core0InternalBehavior/GetMonitorStatus, operation=EvtInfo_AutoCreatedDemEvent_CHNL_53cce282_CANSM_E_MODE_REQUEST_TIMEOUT.GetMonitorStatus
        OpEventGetMonitorStatus_GetMonitorStatus_EvtInfo_AutoCreatedDemEvent_CHNL_53cce282_CANSM_E_BUS_OFF: start-on-event=DemSatellite_OsApplication_Untrusted_Core0InternalBehavior/GetMonitorStatus, operation=EvtInfo_AutoCreatedDemEvent_CHNL_53cce282_CANSM_E_BUS_OFF.GetMonitorStatus
        OpEventGetMonitorStatus_GetMonitorStatus_EvtInfo_AutoCreatedDemEvent_CHNL_a6b6a922_CANSM_E_MODE_REQUEST_TIMEOUT: start-on-event=DemSatellite_OsApplication_Untrusted_Core0InternalBehavior/GetMonitorStatus, operation=EvtInfo_AutoCreatedDemEvent_CHNL_a6b6a922_CANSM_E_MODE_REQUEST_TIMEOUT.GetMonitorStatus
        OpEventGetMonitorStatus_GetMonitorStatus_EvtInfo_AutoCreatedDemEvent_CHNL_a6b6a922_CANSM_E_BUS_OFF: start-on-event=DemSatellite_OsApplication_Untrusted_Core0InternalBehavior/GetMonitorStatus, operation=EvtInfo_AutoCreatedDemEvent_CHNL_a6b6a922_CANSM_E_BUS_OFF.GetMonitorStatus
        OpEventGetMonitorStatus_GetMonitorStatus_EvtInfo_AutoCreatedDemEvent_CHNL_df893ad5_CANSM_E_MODE_REQUEST_TIMEOUT: start-on-event=DemSatellite_OsApplication_Untrusted_Core0InternalBehavior/GetMonitorStatus, operation=EvtInfo_AutoCreatedDemEvent_CHNL_df893ad5_CANSM_E_MODE_REQUEST_TIMEOUT.GetMonitorStatus
        OpEventGetMonitorStatus_GetMonitorStatus_EvtInfo_AutoCreatedDemEvent_CHNL_df893ad5_CANSM_E_BUS_OFF: start-on-event=DemSatellite_OsApplication_Untrusted_Core0InternalBehavior/GetMonitorStatus, operation=EvtInfo_AutoCreatedDemEvent_CHNL_df893ad5_CANSM_E_BUS_OFF.GetMonitorStatus
        OpEventGetMonitorStatus_GetMonitorStatus_EvtInfo_AutoCreatedDemEvent_CHNL_e058b4ae_CANSM_E_MODE_REQUEST_TIMEOUT: start-on-event=DemSatellite_OsApplication_Untrusted_Core0InternalBehavior/GetMonitorStatus, operation=EvtInfo_AutoCreatedDemEvent_CHNL_e058b4ae_CANSM_E_MODE_REQUEST_TIMEOUT.GetMonitorStatus
        OpEventGetMonitorStatus_GetMonitorStatus_EvtInfo_AutoCreatedDemEvent_CHNL_e058b4ae_CANSM_E_BUS_OFF: start-on-event=DemSatellite_OsApplication_Untrusted_Core0InternalBehavior/GetMonitorStatus, operation=EvtInfo_AutoCreatedDemEvent_CHNL_e058b4ae_CANSM_E_BUS_OFF.GetMonitorStatus
        OpEventGetMonitorStatus_GetMonitorStatus_EvtInfo_AutoCreatedDemEvent_ECUM_E_RAM_CHECK_FAILED: start-on-event=DemSatellite_OsApplication_Untrusted_Core0InternalBehavior/GetMonitorStatus, operation=EvtInfo_AutoCreatedDemEvent_ECUM_E_RAM_CHECK_FAILED.GetMonitorStatus
        OpEventGetMonitorStatus_GetMonitorStatus_EvtInfo_AutoCreatedDemEvent_ECUM_E_IMPROPER_CALLER: start-on-event=DemSatellite_OsApplication_Untrusted_Core0InternalBehavior/GetMonitorStatus, operation=EvtInfo_AutoCreatedDemEvent_ECUM_E_IMPROPER_CALLER.GetMonitorStatus
        OpEventGetMonitorStatus_GetMonitorStatus_EvtInfo_AutoCreatedDemEvent_ECUM_E_CONFIGURATION_DATA_INCONSISTENT: start-on-event=DemSatellite_OsApplication_Untrusted_Core0InternalBehavior/GetMonitorStatus, operation=EvtInfo_AutoCreatedDemEvent_ECUM_E_CONFIGURATION_DATA_INCONSISTENT.GetMonitorStatus
        OpEventGetMonitorStatus_GetMonitorStatus_EvtInfo_AutoCreatedDemEvent_ECUM_E_ALL_RUN_REQUESTS_KILLED: start-on-event=DemSatellite_OsApplication_Untrusted_Core0InternalBehavior/GetMonitorStatus, operation=EvtInfo_AutoCreatedDemEvent_ECUM_E_ALL_RUN_REQUESTS_KILLED.GetMonitorStatus
        OpEventGetMonitorStatus_GetMonitorStatus_EvtInfo_AutoCreatedDemEvent_FLS_E_WRITE_FAILED: start-on-event=DemSatellite_OsApplication_Untrusted_Core0InternalBehavior/GetMonitorStatus, operation=EvtInfo_AutoCreatedDemEvent_FLS_E_WRITE_FAILED.GetMonitorStatus
        OpEventGetMonitorStatus_GetMonitorStatus_EvtInfo_AutoCreatedDemEvent_FLS_E_UNEXPECTED_FLASH_ID: start-on-event=DemSatellite_OsApplication_Untrusted_Core0InternalBehavior/GetMonitorStatus, operation=EvtInfo_AutoCreatedDemEvent_FLS_E_UNEXPECTED_FLASH_ID.GetMonitorStatus
        OpEventGetMonitorStatus_GetMonitorStatus_EvtInfo_AutoCreatedDemEvent_FLS_E_READ_FAILED: start-on-event=DemSatellite_OsApplication_Untrusted_Core0InternalBehavior/GetMonitorStatus, operation=EvtInfo_AutoCreatedDemEvent_FLS_E_READ_FAILED.GetMonitorStatus
        OpEventGetMonitorStatus_GetMonitorStatus_EvtInfo_AutoCreatedDemEvent_FLS_E_ERASE_FAILED: start-on-event=DemSatellite_OsApplication_Untrusted_Core0InternalBehavior/GetMonitorStatus, operation=EvtInfo_AutoCreatedDemEvent_FLS_E_ERASE_FAILED.GetMonitorStatus
        OpEventGetMonitorStatus_GetMonitorStatus_EvtInfo_AutoCreatedDemEvent_FLS_E_COMPARE_FAILED: start-on-event=DemSatellite_OsApplication_Untrusted_Core0InternalBehavior/GetMonitorStatus, operation=EvtInfo_AutoCreatedDemEvent_FLS_E_COMPARE_FAILED.GetMonitorStatus
        OpEventGetMonitorStatus_GetMonitorStatus_EvtInfo_AutoCreatedDemEvent_GPT_E_TIMEOUT: start-on-event=DemSatellite_OsApplication_Untrusted_Core0InternalBehavior/GetMonitorStatus, operation=EvtInfo_AutoCreatedDemEvent_GPT_E_TIMEOUT.GetMonitorStatus
        OpEventGetMonitorStatus_GetMonitorStatus_EvtInfo_AutoCreatedDemEvent_J1939NM_E_ADDRESS_LOST: start-on-event=DemSatellite_OsApplication_Untrusted_Core0InternalBehavior/GetMonitorStatus, operation=EvtInfo_AutoCreatedDemEvent_J1939NM_E_ADDRESS_LOST.GetMonitorStatus
        OpEventGetMonitorStatus_GetMonitorStatus_EvtInfo_AutoCreatedDemEvent_J1939TpConfiguration_J1939TP_E_COMMUNICATION: start-on-event=DemSatellite_OsApplication_Untrusted_Core0InternalBehavior/GetMonitorStatus, operation=EvtInfo_AutoCreatedDemEvent_J1939TpConfiguration_J1939TP_E_COMMUNICATION.GetMonitorStatus
        OpEventGetMonitorStatus_GetMonitorStatus_EvtInfo_AutoCreatedDemEvent_LIN_E_TIMEOUT: start-on-event=DemSatellite_OsApplication_Untrusted_Core0InternalBehavior/GetMonitorStatus, operation=EvtInfo_AutoCreatedDemEvent_LIN_E_TIMEOUT.GetMonitorStatus
        OpEventGetMonitorStatus_GetMonitorStatus_EvtInfo_AutoCreatedDemEvent_MCL_E_DMA_UNRECOGNIZED: start-on-event=DemSatellite_OsApplication_Untrusted_Core0InternalBehavior/GetMonitorStatus, operation=EvtInfo_AutoCreatedDemEvent_MCL_E_DMA_UNRECOGNIZED.GetMonitorStatus
        OpEventGetMonitorStatus_GetMonitorStatus_EvtInfo_AutoCreatedDemEvent_MCL_E_DMA_PRIORITY: start-on-event=DemSatellite_OsApplication_Untrusted_Core0InternalBehavior/GetMonitorStatus, operation=EvtInfo_AutoCreatedDemEvent_MCL_E_DMA_PRIORITY.GetMonitorStatus
        OpEventGetMonitorStatus_GetMonitorStatus_EvtInfo_AutoCreatedDemEvent_MCL_E_DMA_INCONSISTENCY: start-on-event=DemSatellite_OsApplication_Untrusted_Core0InternalBehavior/GetMonitorStatus, operation=EvtInfo_AutoCreatedDemEvent_MCL_E_DMA_INCONSISTENCY.GetMonitorStatus
        OpEventGetMonitorStatus_GetMonitorStatus_EvtInfo_AutoCreatedDemEvent_MCL_E_DMA_ECC: start-on-event=DemSatellite_OsApplication_Untrusted_Core0InternalBehavior/GetMonitorStatus, operation=EvtInfo_AutoCreatedDemEvent_MCL_E_DMA_ECC.GetMonitorStatus
        OpEventGetMonitorStatus_GetMonitorStatus_EvtInfo_AutoCreatedDemEvent_MCL_E_DMA_DESCRIPTOR: start-on-event=DemSatellite_OsApplication_Untrusted_Core0InternalBehavior/GetMonitorStatus, operation=EvtInfo_AutoCreatedDemEvent_MCL_E_DMA_DESCRIPTOR.GetMonitorStatus
        OpEventGetMonitorStatus_GetMonitorStatus_EvtInfo_AutoCreatedDemEvent_MCL_E_DMA_BUS: start-on-event=DemSatellite_OsApplication_Untrusted_Core0InternalBehavior/GetMonitorStatus, operation=EvtInfo_AutoCreatedDemEvent_MCL_E_DMA_BUS.GetMonitorStatus
        OpEventGetMonitorStatus_GetMonitorStatus_EvtInfo_AutoCreatedDemEvent_MCU_E_TIMEOUT_FAILURE: start-on-event=DemSatellite_OsApplication_Untrusted_Core0InternalBehavior/GetMonitorStatus, operation=EvtInfo_AutoCreatedDemEvent_MCU_E_TIMEOUT_FAILURE.GetMonitorStatus
        OpEventGetMonitorStatus_GetMonitorStatus_EvtInfo_AutoCreatedDemEvent_MCU_E_SSCM_CER_FAILURE: start-on-event=DemSatellite_OsApplication_Untrusted_Core0InternalBehavior/GetMonitorStatus, operation=EvtInfo_AutoCreatedDemEvent_MCU_E_SSCM_CER_FAILURE.GetMonitorStatus
        OpEventGetMonitorStatus_GetMonitorStatus_EvtInfo_AutoCreatedDemEvent_MCU_E_INVALIDMODE_CONFIG: start-on-event=DemSatellite_OsApplication_Untrusted_Core0InternalBehavior/GetMonitorStatus, operation=EvtInfo_AutoCreatedDemEvent_MCU_E_INVALIDMODE_CONFIG.GetMonitorStatus
        OpEventGetMonitorStatus_GetMonitorStatus_EvtInfo_AutoCreatedDemEvent_MCU_E_CLOCK_FAILURE: start-on-event=DemSatellite_OsApplication_Untrusted_Core0InternalBehavior/GetMonitorStatus, operation=EvtInfo_AutoCreatedDemEvent_MCU_E_CLOCK_FAILURE.GetMonitorStatus
        OpEventGetMonitorStatus_GetMonitorStatus_EvtInfo_AutoCreatedDemEvent_NVM_E_WRONG_BLOCK_ID: start-on-event=DemSatellite_OsApplication_Untrusted_Core0InternalBehavior/GetMonitorStatus, operation=EvtInfo_AutoCreatedDemEvent_NVM_E_WRONG_BLOCK_ID.GetMonitorStatus
        OpEventGetMonitorStatus_GetMonitorStatus_EvtInfo_AutoCreatedDemEvent_NVM_E_WRITE_PROTECTED: start-on-event=DemSatellite_OsApplication_Untrusted_Core0InternalBehavior/GetMonitorStatus, operation=EvtInfo_AutoCreatedDemEvent_NVM_E_WRITE_PROTECTED.GetMonitorStatus
        OpEventGetMonitorStatus_GetMonitorStatus_EvtInfo_AutoCreatedDemEvent_NVM_E_VERIFY_FAILED: start-on-event=DemSatellite_OsApplication_Untrusted_Core0InternalBehavior/GetMonitorStatus, operation=EvtInfo_AutoCreatedDemEvent_NVM_E_VERIFY_FAILED.GetMonitorStatus
        OpEventGetMonitorStatus_GetMonitorStatus_EvtInfo_AutoCreatedDemEvent_NVM_E_REQ_FAILED: start-on-event=DemSatellite_OsApplication_Untrusted_Core0InternalBehavior/GetMonitorStatus, operation=EvtInfo_AutoCreatedDemEvent_NVM_E_REQ_FAILED.GetMonitorStatus
        OpEventGetMonitorStatus_GetMonitorStatus_EvtInfo_AutoCreatedDemEvent_NVM_E_QUEUE_OVERFLOW: start-on-event=DemSatellite_OsApplication_Untrusted_Core0InternalBehavior/GetMonitorStatus, operation=EvtInfo_AutoCreatedDemEvent_NVM_E_QUEUE_OVERFLOW.GetMonitorStatus
        OpEventGetMonitorStatus_GetMonitorStatus_EvtInfo_AutoCreatedDemEvent_NVM_E_LOSS_OF_REDUNDANCY: start-on-event=DemSatellite_OsApplication_Untrusted_Core0InternalBehavior/GetMonitorStatus, operation=EvtInfo_AutoCreatedDemEvent_NVM_E_LOSS_OF_REDUNDANCY.GetMonitorStatus
        OpEventGetMonitorStatus_GetMonitorStatus_EvtInfo_AutoCreatedDemEvent_NVM_E_INTEGRITY_FAILED: start-on-event=DemSatellite_OsApplication_Untrusted_Core0InternalBehavior/GetMonitorStatus, operation=EvtInfo_AutoCreatedDemEvent_NVM_E_INTEGRITY_FAILED.GetMonitorStatus
        OpEventGetMonitorStatus_GetMonitorStatus_EvtInfo_AutoCreatedDemEvent_SPI_E_HARDWARE_ERROR: start-on-event=DemSatellite_OsApplication_Untrusted_Core0InternalBehavior/GetMonitorStatus, operation=EvtInfo_AutoCreatedDemEvent_SPI_E_HARDWARE_ERROR.GetMonitorStatus
        OpEventGetMonitorStatus_GetMonitorStatus_EvtInfo_AutoCreatedDemEvent_SpiDriver_SPI_E_HARDWARE_ERROR: start-on-event=DemSatellite_OsApplication_Untrusted_Core0InternalBehavior/GetMonitorStatus, operation=EvtInfo_AutoCreatedDemEvent_SpiDriver_SPI_E_HARDWARE_ERROR.GetMonitorStatus
        OpEventGetMonitorStatus_GetMonitorStatus_EvtInfo_AutoCreatedDemEvent_WDG_E_UNLOCKED: start-on-event=DemSatellite_OsApplication_Untrusted_Core0InternalBehavior/GetMonitorStatus, operation=EvtInfo_AutoCreatedDemEvent_WDG_E_UNLOCKED.GetMonitorStatus
        OpEventGetMonitorStatus_GetMonitorStatus_EvtInfo_AutoCreatedDemEvent_WDG_E_MODE_FAILED: start-on-event=DemSatellite_OsApplication_Untrusted_Core0InternalBehavior/GetMonitorStatus, operation=EvtInfo_AutoCreatedDemEvent_WDG_E_MODE_FAILED.GetMonitorStatus
        OpEventGetMonitorStatus_GetMonitorStatus_EvtInfo_AutoCreatedDemEvent_WDG_E_INVALID_PARAMETER: start-on-event=DemSatellite_OsApplication_Untrusted_Core0InternalBehavior/GetMonitorStatus, operation=EvtInfo_AutoCreatedDemEvent_WDG_E_INVALID_PARAMETER.GetMonitorStatus
        OpEventGetMonitorStatus_GetMonitorStatus_EvtInfo_AutoCreatedDemEvent_WDG_E_INVALID_CALL: start-on-event=DemSatellite_OsApplication_Untrusted_Core0InternalBehavior/GetMonitorStatus, operation=EvtInfo_AutoCreatedDemEvent_WDG_E_INVALID_CALL.GetMonitorStatus
        OpEventGetMonitorStatus_GetMonitorStatus_EvtInfo_AutoCreatedDemEvent_WDG_E_FORBIDDEN_INVOCATION: start-on-event=DemSatellite_OsApplication_Untrusted_Core0InternalBehavior/GetMonitorStatus, operation=EvtInfo_AutoCreatedDemEvent_WDG_E_FORBIDDEN_INVOCATION.GetMonitorStatus
        OpEventGetMonitorStatus_GetMonitorStatus_EvtInfo_AutoCreatedDemEvent_WDG_E_DISABLE_REJECTED: start-on-event=DemSatellite_OsApplication_Untrusted_Core0InternalBehavior/GetMonitorStatus, operation=EvtInfo_AutoCreatedDemEvent_WDG_E_DISABLE_REJECTED.GetMonitorStatus
        OpEventGetMonitorStatus_GetMonitorStatus_EvtInfo_AutoCreatedDemEvent_WDG_E_CORRUPT_CONFIG: start-on-event=DemSatellite_OsApplication_Untrusted_Core0InternalBehavior/GetMonitorStatus, operation=EvtInfo_AutoCreatedDemEvent_WDG_E_CORRUPT_CONFIG.GetMonitorStatus
        OpEventGetEventUdsStatus_GetEventUdsStatus_EvtInfo_DEM_EVENT_StartApplication: start-on-event=DemSatellite_OsApplication_Untrusted_Core0InternalBehavior/GetEventUdsStatus, operation=EvtInfo_DEM_EVENT_StartApplication.GetEventUdsStatus
        OpEventGetEventUdsStatus_GetEventUdsStatus_Event_DEM_EVENT_StartApplication: start-on-event=DemSatellite_OsApplication_Untrusted_Core0InternalBehavior/GetEventUdsStatus, operation=Event_DEM_EVENT_StartApplication.GetEventUdsStatus
        OpEventGetEventStatus_GetEventStatus_EvtInfo_DEM_EVENT_StartApplication: start-on-event=DemSatellite_OsApplication_Untrusted_Core0InternalBehavior/GetEventStatus, operation=EvtInfo_DEM_EVENT_StartApplication.GetEventStatus
        OpEventGetEventStatus_GetEventStatus_Event_DEM_EVENT_StartApplication: start-on-event=DemSatellite_OsApplication_Untrusted_Core0InternalBehavior/GetEventStatus, operation=Event_DEM_EVENT_StartApplication.GetEventStatus
        OpEventGetEventFailed_GetEventFailed_EvtInfo_DEM_EVENT_StartApplication: start-on-event=DemSatellite_OsApplication_Untrusted_Core0InternalBehavior/GetEventFailed, operation=EvtInfo_DEM_EVENT_StartApplication.GetEventFailed
        OpEventGetEventFailed_GetEventFailed_Event_DEM_EVENT_StartApplication: start-on-event=DemSatellite_OsApplication_Untrusted_Core0InternalBehavior/GetEventFailed, operation=Event_DEM_EVENT_StartApplication.GetEventFailed
        OpEventGetEventTested_GetEventTested_EvtInfo_DEM_EVENT_StartApplication: start-on-event=DemSatellite_OsApplication_Untrusted_Core0InternalBehavior/GetEventTested, operation=EvtInfo_DEM_EVENT_StartApplication.GetEventTested
        OpEventGetEventTested_GetEventTested_Event_DEM_EVENT_StartApplication: start-on-event=DemSatellite_OsApplication_Untrusted_Core0InternalBehavior/GetEventTested, operation=Event_DEM_EVENT_StartApplication.GetEventTested
        OpEventGetDTCOfEvent_GetDTCOfEvent_EvtInfo_DEM_EVENT_StartApplication: start-on-event=DemSatellite_OsApplication_Untrusted_Core0InternalBehavior/GetDTCOfEvent, operation=EvtInfo_DEM_EVENT_StartApplication.GetDTCOfEvent
        OpEventGetDTCOfEvent_GetDTCOfEvent_Event_DEM_EVENT_StartApplication: start-on-event=DemSatellite_OsApplication_Untrusted_Core0InternalBehavior/GetDTCOfEvent, operation=Event_DEM_EVENT_StartApplication.GetDTCOfEvent
        OpEventGetFaultDetectionCounter_GetFaultDetectionCounter_EvtInfo_DEM_EVENT_StartApplication: start-on-event=DemSatellite_OsApplication_Untrusted_Core0InternalBehavior/GetFaultDetectionCounter, operation=EvtInfo_DEM_EVENT_StartApplication.GetFaultDetectionCounter
        OpEventGetFaultDetectionCounter_GetFaultDetectionCounter_Event_DEM_EVENT_StartApplication: start-on-event=DemSatellite_OsApplication_Untrusted_Core0InternalBehavior/GetFaultDetectionCounter, operation=Event_DEM_EVENT_StartApplication.GetFaultDetectionCounter
        OpEventGetEventFreezeFrameDataEx_GetEventFreezeFrameDataEx_EvtInfo_DEM_EVENT_StartApplication: start-on-event=DemSatellite_OsApplication_Untrusted_Core0InternalBehavior/GetEventFreezeFrameDataEx, operation=EvtInfo_DEM_EVENT_StartApplication.GetEventFreezeFrameDataEx
        OpEventGetEventFreezeFrameDataEx_GetEventFreezeFrameDataEx_Event_DEM_EVENT_StartApplication: start-on-event=DemSatellite_OsApplication_Untrusted_Core0InternalBehavior/GetEventFreezeFrameDataEx, operation=Event_DEM_EVENT_StartApplication.GetEventFreezeFrameDataEx
        OpEventGetEventExtendedDataRecordEx_GetEventExtendedDataRecordEx_EvtInfo_DEM_EVENT_StartApplication: start-on-event=DemSatellite_OsApplication_Untrusted_Core0InternalBehavior/GetEventExtendedDataRecordEx, operation=EvtInfo_DEM_EVENT_StartApplication.GetEventExtendedDataRecordEx
        OpEventGetEventExtendedDataRecordEx_GetEventExtendedDataRecordEx_Event_DEM_EVENT_StartApplication: start-on-event=DemSatellite_OsApplication_Untrusted_Core0InternalBehavior/GetEventExtendedDataRecordEx, operation=Event_DEM_EVENT_StartApplication.GetEventExtendedDataRecordEx
        OpEventGetEventEnableCondition_GetEventEnableCondition_EvtInfo_DEM_EVENT_StartApplication: start-on-event=DemSatellite_OsApplication_Untrusted_Core0InternalBehavior/GetEventEnableCondition, operation=EvtInfo_DEM_EVENT_StartApplication.GetEventEnableCondition
        OpEventGetDebouncingOfEvent_GetDebouncingOfEvent_EvtInfo_DEM_EVENT_StartApplication: start-on-event=DemSatellite_OsApplication_Untrusted_Core0InternalBehavior/GetDebouncingOfEvent, operation=EvtInfo_DEM_EVENT_StartApplication.GetDebouncingOfEvent
        OpEventGetMonitorStatus_GetMonitorStatus_EvtInfo_DEM_EVENT_StartApplication: start-on-event=DemSatellite_OsApplication_Untrusted_Core0InternalBehavior/GetMonitorStatus, operation=EvtInfo_DEM_EVENT_StartApplication.GetMonitorStatus
        OpEventSetEventStatus_SetEventStatus_Event_DEM_EVENT_StartApplication: start-on-event=SetEventStatus, operation=Event_DEM_EVENT_StartApplication.SetEventStatus
        OpEventResetEventStatus_ResetEventStatus_Event_DEM_EVENT_StartApplication: start-on-event=ResetEventStatus, operation=Event_DEM_EVENT_StartApplication.ResetEventStatus
        OpEventResetEventDebounceStatus_ResetEventDebounceStatus_Event_DEM_EVENT_StartApplication: start-on-event=ResetEventDebounceStatus, operation=Event_DEM_EVENT_StartApplication.ResetEventDebounceStatus
      port-api-options:
        {enable-take-address=true, indirect-api=false, port-defined-argument-value{value=1, value-type=Dem_EventIdType}, port=EvtInfo_DemEventParameter_0}
        enable-take-address=true, indirect-api=false, port=DemSatellite_OsApplication_Untrusted_Core0/GeneralEventInfo
        {enable-take-address=true, indirect-api=false, port-defined-argument-value{value=1, value-type=Dem_EventIdType}, port=Event_DemEventParameter_0}
        {enable-take-address=true, indirect-api=false, port-defined-argument-value{value=2, value-type=Dem_EventIdType}, port=EvtInfo_AutoCreatedDemEvent_ADC_E_TIMEOUT}
        {enable-take-address=true, indirect-api=false, port-defined-argument-value{value=5, value-type=Dem_EventIdType}, port=EvtInfo_AutoCreatedDemEvent_CC_DisableDM_CIOM_oCabSubnet_Rx_063a5fbc_BswMReportFailToDemRef}
        {enable-take-address=true, indirect-api=false, port-defined-argument-value{value=53, value-type=Dem_EventIdType}, port=EvtInfo_AutoCreatedDemEvent_CC_J1939RmStateSwitch_CN_Backbone1J1939_0b1f4bae_CIOM_4d5cd289_J1939RM_STATE_OFFLINE_BswMRe_5a5b15b8}
        {enable-take-address=true, indirect-api=false, port-defined-argument-value{value=54, value-type=Dem_EventIdType}, port=EvtInfo_AutoCreatedDemEvent_CC_J1939RmStateSwitch_CN_Backbone1J1939_0b1f4bae_CIOM_4d5cd289_J1939RM_STATE_ONLINE_BswMRep_ec959aed}
        {enable-take-address=true, indirect-api=false, port-defined-argument-value{value=25, value-type=Dem_EventIdType}, port=EvtInfo_AutoCreatedDemEvent_CC_DisablePDUGroup_CIOM_oLIN04_Tx_04202f7b_BswMReportFailToDemRef}
        {enable-take-address=true, indirect-api=false, port-defined-argument-value{value=24, value-type=Dem_EventIdType}, port=EvtInfo_AutoCreatedDemEvent_CC_DisablePDUGroup_CIOM_oLIN04_Rx_527a88fd_BswMReportFailToDemRef}
        {enable-take-address=true, indirect-api=false, port-defined-argument-value{value=19, value-type=Dem_EventIdType}, port=EvtInfo_AutoCreatedDemEvent_CC_DisablePDUGroup_CIOM_oLIN01_Tx_33fedf49_BswMReportFailToDemRef}
        {enable-take-address=true, indirect-api=false, port-defined-argument-value{value=18, value-type=Dem_EventIdType}, port=EvtInfo_AutoCreatedDemEvent_CC_DisablePDUGroup_CIOM_oLIN01_Rx_65a478cf_BswMReportFailToDemRef}
        {enable-take-address=true, indirect-api=false, port-defined-argument-value{value=50, value-type=Dem_EventIdType}, port=EvtInfo_AutoCreatedDemEvent_CC_EnablePDUGroup_CIOM_oLIN04_Tx_04202f7b_BswMReportFailToDemRef}
        {enable-take-address=true, indirect-api=false, port-defined-argument-value{value=49, value-type=Dem_EventIdType}, port=EvtInfo_AutoCreatedDemEvent_CC_EnablePDUGroup_CIOM_oLIN04_Rx_527a88fd_BswMReportFailToDemRef}
        {enable-take-address=true, indirect-api=false, port-defined-argument-value{value=4, value-type=Dem_EventIdType}, port=EvtInfo_AutoCreatedDemEvent_CC_DisableDM_CIOM_oBackbone2_Rx_4e624434_BswMReportFailToDemRef}
        {enable-take-address=true, indirect-api=false, port-defined-argument-value{value=29, value-type=Dem_EventIdType}, port=EvtInfo_AutoCreatedDemEvent_CC_EnableDM_CIOM_oBackbone2_Rx_4e624434_BswMReportFailToDemRef}
        {enable-take-address=true, indirect-api=false, port-defined-argument-value{value=7, value-type=Dem_EventIdType}, port=EvtInfo_AutoCreatedDemEvent_CC_DisableDM_CIOM_oSecuritySubnet_Rx_3a3c1dbc_BswMReportFailToDemRef}
        {enable-take-address=true, indirect-api=false, port-defined-argument-value{value=32, value-type=Dem_EventIdType}, port=EvtInfo_AutoCreatedDemEvent_CC_EnableDM_CIOM_oSecuritySubnet_Rx_3a3c1dbc_BswMReportFailToDemRef}
        {enable-take-address=true, indirect-api=false, port-defined-argument-value{value=13, value-type=Dem_EventIdType}, port=EvtInfo_AutoCreatedDemEvent_CC_DisablePDUGroup_CIOM_oCabSubnet_Tx_5060f83a_BswMReportFailToDemRef}
        {enable-take-address=true, indirect-api=false, port-defined-argument-value{value=38, value-type=Dem_EventIdType}, port=EvtInfo_AutoCreatedDemEvent_CC_EnablePDUGroup_CIOM_oCabSubnet_Tx_5060f83a_BswMReportFailToDemRef}
        {enable-take-address=true, indirect-api=false, port-defined-argument-value{value=30, value-type=Dem_EventIdType}, port=EvtInfo_AutoCreatedDemEvent_CC_EnableDM_CIOM_oCabSubnet_Rx_063a5fbc_BswMReportFailToDemRef}
        {enable-take-address=true, indirect-api=false, port-defined-argument-value{value=11, value-type=Dem_EventIdType}, port=EvtInfo_AutoCreatedDemEvent_CC_DisablePDUGroup_CIOM_oBackbone2_Tx_1838e3b2_BswMReportFailToDemRef}
        {enable-take-address=true, indirect-api=false, port-defined-argument-value{value=36, value-type=Dem_EventIdType}, port=EvtInfo_AutoCreatedDemEvent_CC_EnablePDUGroup_CIOM_oBackbone2_Tx_1838e3b2_BswMReportFailToDemRef}
        {enable-take-address=true, indirect-api=false, port-defined-argument-value{value=10, value-type=Dem_EventIdType}, port=EvtInfo_AutoCreatedDemEvent_CC_DisablePDUGroup_CIOM_oBackbone2_Rx_4e624434_BswMReportFailToDemRef}
        {enable-take-address=true, indirect-api=false, port-defined-argument-value{value=35, value-type=Dem_EventIdType}, port=EvtInfo_AutoCreatedDemEvent_CC_EnablePDUGroup_CIOM_oBackbone2_Rx_4e624434_BswMReportFailToDemRef}
        {enable-take-address=true, indirect-api=false, port-defined-argument-value{value=8, value-type=Dem_EventIdType}, port=EvtInfo_AutoCreatedDemEvent_CC_DisablePDUGroup_CIOM_oBackbone1J1939_Rx_BC_405bc776_BswMReportFailToDemRef}
        {enable-take-address=true, indirect-api=false, port-defined-argument-value{value=33, value-type=Dem_EventIdType}, port=EvtInfo_AutoCreatedDemEvent_CC_EnablePDUGroup_CIOM_oBackbone1J1939_Rx_BC_405bc776_BswMReportFailToDemRef}
        {enable-take-address=true, indirect-api=false, port-defined-argument-value{value=46, value-type=Dem_EventIdType}, port=EvtInfo_AutoCreatedDemEvent_CC_EnablePDUGroup_CIOM_oLIN02_Tx_214b70a7_BswMReportFailToDemRef}
        {enable-take-address=true, indirect-api=false, port-defined-argument-value{value=45, value-type=Dem_EventIdType}, port=EvtInfo_AutoCreatedDemEvent_CC_EnablePDUGroup_CIOM_oLIN02_Rx_7711d721_BswMReportFailToDemRef}
        {enable-take-address=true, indirect-api=false, port-defined-argument-value{value=44, value-type=Dem_EventIdType}, port=EvtInfo_AutoCreatedDemEvent_CC_EnablePDUGroup_CIOM_oLIN01_Tx_33fedf49_BswMReportFailToDemRef}
        {enable-take-address=true, indirect-api=false, port-defined-argument-value{value=43, value-type=Dem_EventIdType}, port=EvtInfo_AutoCreatedDemEvent_CC_EnablePDUGroup_CIOM_oLIN01_Rx_65a478cf_BswMReportFailToDemRef}
        {enable-take-address=true, indirect-api=false, port-defined-argument-value{value=23, value-type=Dem_EventIdType}, port=EvtInfo_AutoCreatedDemEvent_CC_DisablePDUGroup_CIOM_oLIN03_Tx_99f717c2_BswMReportFailToDemRef}
        {enable-take-address=true, indirect-api=false, port-defined-argument-value{value=22, value-type=Dem_EventIdType}, port=EvtInfo_AutoCreatedDemEvent_CC_DisablePDUGroup_CIOM_oLIN03_Rx_cfadb044_BswMReportFailToDemRef}
        {enable-take-address=true, indirect-api=false, port-defined-argument-value{value=6, value-type=Dem_EventIdType}, port=EvtInfo_AutoCreatedDemEvent_CC_DisableDM_CIOM_oFMSNet_Rx_BC_dd2c1510_BswMReportFailToDemRef}
        {enable-take-address=true, indirect-api=false, port-defined-argument-value{value=31, value-type=Dem_EventIdType}, port=EvtInfo_AutoCreatedDemEvent_CC_EnableDM_CIOM_oFMSNet_Rx_BC_dd2c1510_BswMReportFailToDemRef}
        {enable-take-address=true, indirect-api=false, port-defined-argument-value{value=48, value-type=Dem_EventIdType}, port=EvtInfo_AutoCreatedDemEvent_CC_EnablePDUGroup_CIOM_oLIN03_Tx_99f717c2_BswMReportFailToDemRef}
        {enable-take-address=true, indirect-api=false, port-defined-argument-value{value=47, value-type=Dem_EventIdType}, port=EvtInfo_AutoCreatedDemEvent_CC_EnablePDUGroup_CIOM_oLIN03_Rx_cfadb044_BswMReportFailToDemRef}
        {enable-take-address=true, indirect-api=false, port-defined-argument-value{value=21, value-type=Dem_EventIdType}, port=EvtInfo_AutoCreatedDemEvent_CC_DisablePDUGroup_CIOM_oLIN02_Tx_214b70a7_BswMReportFailToDemRef}
        {enable-take-address=true, indirect-api=false, port-defined-argument-value{value=20, value-type=Dem_EventIdType}, port=EvtInfo_AutoCreatedDemEvent_CC_DisablePDUGroup_CIOM_oLIN02_Rx_7711d721_BswMReportFailToDemRef}
        {enable-take-address=true, indirect-api=false, port-defined-argument-value{value=12, value-type=Dem_EventIdType}, port=EvtInfo_AutoCreatedDemEvent_CC_DisablePDUGroup_CIOM_oCabSubnet_Rx_063a5fbc_BswMReportFailToDemRef}
        {enable-take-address=true, indirect-api=false, port-defined-argument-value{value=37, value-type=Dem_EventIdType}, port=EvtInfo_AutoCreatedDemEvent_CC_EnablePDUGroup_CIOM_oCabSubnet_Rx_063a5fbc_BswMReportFailToDemRef}
        {enable-take-address=true, indirect-api=false, port-defined-argument-value{value=14, value-type=Dem_EventIdType}, port=EvtInfo_AutoCreatedDemEvent_CC_DisablePDUGroup_CIOM_oFMSNet_Rx_BC_dd2c1510_BswMReportFailToDemRef}
        {enable-take-address=true, indirect-api=false, port-defined-argument-value{value=39, value-type=Dem_EventIdType}, port=EvtInfo_AutoCreatedDemEvent_CC_EnablePDUGroup_CIOM_oFMSNet_Rx_BC_dd2c1510_BswMReportFailToDemRef}
        {enable-take-address=true, indirect-api=false, port-defined-argument-value{value=26, value-type=Dem_EventIdType}, port=EvtInfo_AutoCreatedDemEvent_CC_DisablePDUGroup_CIOM_oSecuritySubnet_Rx_3a3c1dbc_BswMReportFailToDemRef}
        {enable-take-address=true, indirect-api=false, port-defined-argument-value{value=51, value-type=Dem_EventIdType}, port=EvtInfo_AutoCreatedDemEvent_CC_EnablePDUGroup_CIOM_oSecuritySubnet_Rx_3a3c1dbc_BswMReportFailToDemRef}
        {enable-take-address=true, indirect-api=false, port-defined-argument-value{value=15, value-type=Dem_EventIdType}, port=EvtInfo_AutoCreatedDemEvent_CC_DisablePDUGroup_CIOM_oFMSNet_Tx_0x31_BC_38fc8c7d_BswMReportFailToDemRef}
        {enable-take-address=true, indirect-api=false, port-defined-argument-value{value=40, value-type=Dem_EventIdType}, port=EvtInfo_AutoCreatedDemEvent_CC_EnablePDUGroup_CIOM_oFMSNet_Tx_0x31_BC_38fc8c7d_BswMReportFailToDemRef}
        {enable-take-address=true, indirect-api=false, port-defined-argument-value{value=27, value-type=Dem_EventIdType}, port=EvtInfo_AutoCreatedDemEvent_CC_DisablePDUGroup_CIOM_oSecuritySubnet_Tx_6c66ba3a_BswMReportFailToDemRef}
        {enable-take-address=true, indirect-api=false, port-defined-argument-value{value=52, value-type=Dem_EventIdType}, port=EvtInfo_AutoCreatedDemEvent_CC_EnablePDUGroup_CIOM_oSecuritySubnet_Tx_6c66ba3a_BswMReportFailToDemRef}
        {enable-take-address=true, indirect-api=false, port-defined-argument-value{value=17, value-type=Dem_EventIdType}, port=EvtInfo_AutoCreatedDemEvent_CC_DisablePDUGroup_CIOM_oLIN00_Tx_8b42b82c_BswMReportFailToDemRef}
        {enable-take-address=true, indirect-api=false, port-defined-argument-value{value=41, value-type=Dem_EventIdType}, port=EvtInfo_AutoCreatedDemEvent_CC_EnablePDUGroup_CIOM_oLIN00_Rx_dd181faa_BswMReportFailToDemRef}
        {enable-take-address=true, indirect-api=false, port-defined-argument-value{value=94, value-type=Dem_EventIdType}, port=EvtInfo_AutoCreatedDemEvent_ESH_Action_ComMCheckPendingRequests_BswMReportFailToDemRef}
        {enable-take-address=true, indirect-api=false, port-defined-argument-value{value=3, value-type=Dem_EventIdType}, port=EvtInfo_AutoCreatedDemEvent_CC_DisableDM_CIOM_oBackbone1J1939_Rx_BC_405bc776_BswMReportFailToDemRef}
        {enable-take-address=true, indirect-api=false, port-defined-argument-value{value=16, value-type=Dem_EventIdType}, port=EvtInfo_AutoCreatedDemEvent_CC_DisablePDUGroup_CIOM_oLIN00_Rx_dd181faa_BswMReportFailToDemRef}
        {enable-take-address=true, indirect-api=false, port-defined-argument-value{value=42, value-type=Dem_EventIdType}, port=EvtInfo_AutoCreatedDemEvent_CC_EnablePDUGroup_CIOM_oLIN00_Tx_8b42b82c_BswMReportFailToDemRef}
        {enable-take-address=true, indirect-api=false, port-defined-argument-value{value=121, value-type=Dem_EventIdType}, port=EvtInfo_AutoCreatedDemEvent_ESH_Action_EnterExclusiveArea_BswMReportFailToDemRef}
        {enable-take-address=true, indirect-api=false, port-defined-argument-value{value=150, value-type=Dem_EventIdType}, port=EvtInfo_AutoCreatedDemEvent_ESH_RunToPostRunNested_BswMReportFailToDemRef}
        {enable-take-address=true, indirect-api=false, port-defined-argument-value{value=28, value-type=Dem_EventIdType}, port=EvtInfo_AutoCreatedDemEvent_CC_EnableDM_CIOM_oBackbone1J1939_Rx_BC_405bc776_BswMReportFailToDemRef}
        {enable-take-address=true, indirect-api=false, port-defined-argument-value{value=9, value-type=Dem_EventIdType}, port=EvtInfo_AutoCreatedDemEvent_CC_DisablePDUGroup_CIOM_oBackbone1J1939_Tx_0x31_BC_3782f500_BswMReportFailToDemRef}
        {enable-take-address=true, indirect-api=false, port-defined-argument-value{value=55, value-type=Dem_EventIdType}, port=EvtInfo_AutoCreatedDemEvent_CC_J1939RmStateSwitch_CN_FMSNet_fce1aae5_CIOM_3a3d59b1_J1939RM_STATE_OFFLINE_BswMReportFailToDemRef}
        {enable-take-address=true, indirect-api=false, port-defined-argument-value{value=34, value-type=Dem_EventIdType}, port=EvtInfo_AutoCreatedDemEvent_CC_EnablePDUGroup_CIOM_oBackbone1J1939_Tx_0x31_BC_3782f500_BswMReportFailToDemRef}
        {enable-take-address=true, indirect-api=false, port-defined-argument-value{value=56, value-type=Dem_EventIdType}, port=EvtInfo_AutoCreatedDemEvent_CC_J1939RmStateSwitch_CN_FMSNet_fce1aae5_CIOM_3a3d59b1_J1939RM_STATE_ONLINE_BswMReportFailToDemRef}
        {enable-take-address=true, indirect-api=false, port-defined-argument-value{value=71, value-type=Dem_EventIdType}, port=EvtInfo_AutoCreatedDemEvent_ESH_Action_CancelNvMWriteAll_BswMReportFailToDemRef}
        {enable-take-address=true, indirect-api=false, port-defined-argument-value{value=72, value-type=Dem_EventIdType}, port=EvtInfo_AutoCreatedDemEvent_ESH_Action_CancelWriteAllTimer_Start_BswMReportFailToDemRef}
        {enable-take-address=true, indirect-api=false, port-defined-argument-value{value=73, value-type=Dem_EventIdType}, port=EvtInfo_AutoCreatedDemEvent_ESH_Action_CancelWriteAllTimer_Stop_BswMReportFailToDemRef}
        {enable-take-address=true, indirect-api=false, port-defined-argument-value{value=74, value-type=Dem_EventIdType}, port=EvtInfo_AutoCreatedDemEvent_ESH_Action_ComMAllow_CN_Backbone1J1939_0b1f4bae_BswMReportFailToDemRef}
        {enable-take-address=true, indirect-api=false, port-defined-argument-value{value=75, value-type=Dem_EventIdType}, port=EvtInfo_AutoCreatedDemEvent_ESH_Action_ComMAllow_CN_Backbone1J1939_0b1f4bae_BswMReportFailToDemRef_1}
        {enable-take-address=true, indirect-api=false, port-defined-argument-value{value=76, value-type=Dem_EventIdType}, port=EvtInfo_AutoCreatedDemEvent_ESH_Action_ComMAllow_CN_Backbone2_78967e2c_BswMReportFailToDemRef}
        {enable-take-address=true, indirect-api=false, port-defined-argument-value{value=77, value-type=Dem_EventIdType}, port=EvtInfo_AutoCreatedDemEvent_ESH_Action_ComMAllow_CN_Backbone2_78967e2c_BswMReportFailToDemRef_1}
        {enable-take-address=true, indirect-api=false, port-defined-argument-value{value=78, value-type=Dem_EventIdType}, port=EvtInfo_AutoCreatedDemEvent_ESH_Action_ComMAllow_CN_CabSubnet_9ea693f1_BswMReportFailToDemRef}
        {enable-take-address=true, indirect-api=false, port-defined-argument-value{value=79, value-type=Dem_EventIdType}, port=EvtInfo_AutoCreatedDemEvent_ESH_Action_ComMAllow_CN_CabSubnet_9ea693f1_BswMReportFailToDemRef_1}
        {enable-take-address=true, indirect-api=false, port-defined-argument-value{value=80, value-type=Dem_EventIdType}, port=EvtInfo_AutoCreatedDemEvent_ESH_Action_ComMAllow_CN_FMSNet_fce1aae5_BswMReportFailToDemRef}
        {enable-take-address=true, indirect-api=false, port-defined-argument-value{value=81, value-type=Dem_EventIdType}, port=EvtInfo_AutoCreatedDemEvent_ESH_Action_ComMAllow_CN_FMSNet_fce1aae5_BswMReportFailToDemRef_1}
        {enable-take-address=true, indirect-api=false, port-defined-argument-value{value=82, value-type=Dem_EventIdType}, port=EvtInfo_AutoCreatedDemEvent_ESH_Action_ComMAllow_CN_LIN00_2cd9a7df_BswMReportFailToDemRef}
        {enable-take-address=true, indirect-api=false, port-defined-argument-value{value=83, value-type=Dem_EventIdType}, port=EvtInfo_AutoCreatedDemEvent_ESH_Action_ComMAllow_CN_LIN00_2cd9a7df_BswMReportFailToDemRef_1}
        {enable-take-address=true, indirect-api=false, port-defined-argument-value{value=84, value-type=Dem_EventIdType}, port=EvtInfo_AutoCreatedDemEvent_ESH_Action_ComMAllow_CN_LIN01_5bde9749_BswMReportFailToDemRef}
        {enable-take-address=true, indirect-api=false, port-defined-argument-value{value=85, value-type=Dem_EventIdType}, port=EvtInfo_AutoCreatedDemEvent_ESH_Action_ComMAllow_CN_LIN01_5bde9749_BswMReportFailToDemRef_1}
        {enable-take-address=true, indirect-api=false, port-defined-argument-value{value=86, value-type=Dem_EventIdType}, port=EvtInfo_AutoCreatedDemEvent_ESH_Action_ComMAllow_CN_LIN02_c2d7c6f3_BswMReportFailToDemRef}
        {enable-take-address=true, indirect-api=false, port-defined-argument-value{value=87, value-type=Dem_EventIdType}, port=EvtInfo_AutoCreatedDemEvent_ESH_Action_ComMAllow_CN_LIN02_c2d7c6f3_BswMReportFailToDemRef_1}
        {enable-take-address=true, indirect-api=false, port-defined-argument-value{value=88, value-type=Dem_EventIdType}, port=EvtInfo_AutoCreatedDemEvent_ESH_Action_ComMAllow_CN_LIN03_b5d0f665_BswMReportFailToDemRef}
        {enable-take-address=true, indirect-api=false, port-defined-argument-value{value=89, value-type=Dem_EventIdType}, port=EvtInfo_AutoCreatedDemEvent_ESH_Action_ComMAllow_CN_LIN03_b5d0f665_BswMReportFailToDemRef_1}
        {enable-take-address=true, indirect-api=false, port-defined-argument-value{value=90, value-type=Dem_EventIdType}, port=EvtInfo_AutoCreatedDemEvent_ESH_Action_ComMAllow_CN_LIN04_2bb463c6_BswMReportFailToDemRef}
        {enable-take-address=true, indirect-api=false, port-defined-argument-value{value=91, value-type=Dem_EventIdType}, port=EvtInfo_AutoCreatedDemEvent_ESH_Action_ComMAllow_CN_LIN04_2bb463c6_BswMReportFailToDemRef_1}
        {enable-take-address=true, indirect-api=false, port-defined-argument-value{value=92, value-type=Dem_EventIdType}, port=EvtInfo_AutoCreatedDemEvent_ESH_Action_ComMAllow_CN_SecuritySubnet_e7a0ee54_BswMReportFailToDemRef}
        {enable-take-address=true, indirect-api=false, port-defined-argument-value{value=93, value-type=Dem_EventIdType}, port=EvtInfo_AutoCreatedDemEvent_ESH_Action_ComMAllow_CN_SecuritySubnet_e7a0ee54_BswMReportFailToDemRef_1}
        {enable-take-address=true, indirect-api=false, port-defined-argument-value{value=95, value-type=Dem_EventIdType}, port=EvtInfo_AutoCreatedDemEvent_ESH_Action_ComMCheckPendingRequests_BswMReportFailToDemRef_1}
        {enable-take-address=true, indirect-api=false, port-defined-argument-value{value=96, value-type=Dem_EventIdType}, port=EvtInfo_AutoCreatedDemEvent_ESH_Action_ComMCheckPendingRequests_BswMReportFailToDemRef_2}
        {enable-take-address=true, indirect-api=false, port-defined-argument-value{value=97, value-type=Dem_EventIdType}, port=EvtInfo_AutoCreatedDemEvent_ESH_Action_ComMDisallow_CN_Backbone1J1939_0b1f4bae_BswMReportFailToDemRef}
        {enable-take-address=true, indirect-api=false, port-defined-argument-value{value=98, value-type=Dem_EventIdType}, port=EvtInfo_AutoCreatedDemEvent_ESH_Action_ComMDisallow_CN_Backbone2_78967e2c_BswMReportFailToDemRef}
        {enable-take-address=true, indirect-api=false, port-defined-argument-value{value=99, value-type=Dem_EventIdType}, port=EvtInfo_AutoCreatedDemEvent_ESH_Action_ComMDisallow_CN_CabSubnet_9ea693f1_BswMReportFailToDemRef}
        {enable-take-address=true, indirect-api=false, port-defined-argument-value{value=100, value-type=Dem_EventIdType}, port=EvtInfo_AutoCreatedDemEvent_ESH_Action_ComMDisallow_CN_FMSNet_fce1aae5_BswMReportFailToDemRef}
        {enable-take-address=true, indirect-api=false, port-defined-argument-value{value=101, value-type=Dem_EventIdType}, port=EvtInfo_AutoCreatedDemEvent_ESH_Action_ComMDisallow_CN_LIN00_2cd9a7df_BswMReportFailToDemRef}
        {enable-take-address=true, indirect-api=false, port-defined-argument-value{value=102, value-type=Dem_EventIdType}, port=EvtInfo_AutoCreatedDemEvent_ESH_Action_ComMDisallow_CN_LIN01_5bde9749_BswMReportFailToDemRef}
        {enable-take-address=true, indirect-api=false, port-defined-argument-value{value=103, value-type=Dem_EventIdType}, port=EvtInfo_AutoCreatedDemEvent_ESH_Action_ComMDisallow_CN_LIN02_c2d7c6f3_BswMReportFailToDemRef}
        {enable-take-address=true, indirect-api=false, port-defined-argument-value{value=104, value-type=Dem_EventIdType}, port=EvtInfo_AutoCreatedDemEvent_ESH_Action_ComMDisallow_CN_LIN03_b5d0f665_BswMReportFailToDemRef}
        {enable-take-address=true, indirect-api=false, port-defined-argument-value{value=105, value-type=Dem_EventIdType}, port=EvtInfo_AutoCreatedDemEvent_ESH_Action_ComMDisallow_CN_LIN04_2bb463c6_BswMReportFailToDemRef}
        {enable-take-address=true, indirect-api=false, port-defined-argument-value{value=106, value-type=Dem_EventIdType}, port=EvtInfo_AutoCreatedDemEvent_ESH_Action_ComMDisallow_CN_SecuritySubnet_e7a0ee54_BswMReportFailToDemRef}
        {enable-take-address=true, indirect-api=false, port-defined-argument-value{value=107, value-type=Dem_EventIdType}, port=EvtInfo_AutoCreatedDemEvent_ESH_Action_DemInit_BswMReportFailToDemRef}
        {enable-take-address=true, indirect-api=false, port-defined-argument-value{value=108, value-type=Dem_EventIdType}, port=EvtInfo_AutoCreatedDemEvent_ESH_Action_DemInitialized_BswMReportFailToDemRef}
        {enable-take-address=true, indirect-api=false, port-defined-argument-value{value=109, value-type=Dem_EventIdType}, port=EvtInfo_AutoCreatedDemEvent_ESH_Action_DemNotInitialized_BswMReportFailToDemRef}
        {enable-take-address=true, indirect-api=false, port-defined-argument-value{value=110, value-type=Dem_EventIdType}, port=EvtInfo_AutoCreatedDemEvent_ESH_Action_DemShutdown_BswMReportFailToDemRef}
        {enable-take-address=true, indirect-api=false, port-defined-argument-value{value=111, value-type=Dem_EventIdType}, port=EvtInfo_AutoCreatedDemEvent_ESH_Action_ESH_PostRun_BswMReportFailToDemRef}
        {enable-take-address=true, indirect-api=false, port-defined-argument-value{value=112, value-type=Dem_EventIdType}, port=EvtInfo_AutoCreatedDemEvent_ESH_Action_ESH_PrepShutdown_BswMReportFailToDemRef}
        {enable-take-address=true, indirect-api=false, port-defined-argument-value{value=113, value-type=Dem_EventIdType}, port=EvtInfo_AutoCreatedDemEvent_ESH_Action_ESH_PrepShutdown_BswMReportFailToDemRef_1}
        {enable-take-address=true, indirect-api=false, port-defined-argument-value{value=114, value-type=Dem_EventIdType}, port=EvtInfo_AutoCreatedDemEvent_ESH_Action_ESH_Run_BswMReportFailToDemRef}
        {enable-take-address=true, indirect-api=false, port-defined-argument-value{value=115, value-type=Dem_EventIdType}, port=EvtInfo_AutoCreatedDemEvent_ESH_Action_ESH_Run_BswMReportFailToDemRef_1}
        {enable-take-address=true, indirect-api=false, port-defined-argument-value{value=116, value-type=Dem_EventIdType}, port=EvtInfo_AutoCreatedDemEvent_ESH_Action_ESH_WaitForNvm_BswMReportFailToDemRef}
        {enable-take-address=true, indirect-api=false, port-defined-argument-value{value=117, value-type=Dem_EventIdType}, port=EvtInfo_AutoCreatedDemEvent_ESH_Action_ESH_Wakeup_BswMReportFailToDemRef}
        {enable-take-address=true, indirect-api=false, port-defined-argument-value{value=118, value-type=Dem_EventIdType}, port=EvtInfo_AutoCreatedDemEvent_ESH_Action_ESH_Wakeup_BswMReportFailToDemRef_1}
        {enable-take-address=true, indirect-api=false, port-defined-argument-value{value=119, value-type=Dem_EventIdType}, port=EvtInfo_AutoCreatedDemEvent_ESH_Action_EcuMClearValidatedWakeupEvents_BswMReportFailToDemRef}
        {enable-take-address=true, indirect-api=false, port-defined-argument-value{value=120, value-type=Dem_EventIdType}, port=EvtInfo_AutoCreatedDemEvent_ESH_Action_EcuMGoToSelectedShutdownTarget_BswMReportFailToDemRef}
        {enable-take-address=true, indirect-api=false, port-defined-argument-value{value=122, value-type=Dem_EventIdType}, port=EvtInfo_AutoCreatedDemEvent_ESH_Action_EnterExclusiveArea_BswMReportFailToDemRef_1}
        {enable-take-address=true, indirect-api=false, port-defined-argument-value{value=123, value-type=Dem_EventIdType}, port=EvtInfo_AutoCreatedDemEvent_ESH_Action_ExitExclusiveArea_BswMReportFailToDemRef}
        {enable-take-address=true, indirect-api=false, port-defined-argument-value{value=125, value-type=Dem_EventIdType}, port=EvtInfo_AutoCreatedDemEvent_ESH_Action_NvMWriteAll_BswMReportFailToDemRef}
        {enable-take-address=true, indirect-api=false, port-defined-argument-value{value=126, value-type=Dem_EventIdType}, port=EvtInfo_AutoCreatedDemEvent_ESH_Action_OnEnterPostRun_BswMReportFailToDemRef}
        {enable-take-address=true, indirect-api=false, port-defined-argument-value{value=127, value-type=Dem_EventIdType}, port=EvtInfo_AutoCreatedDemEvent_ESH_Action_OnEnterPrepShutdown_BswMReportFailToDemRef}
        {enable-take-address=true, indirect-api=false, port-defined-argument-value{value=128, value-type=Dem_EventIdType}, port=EvtInfo_AutoCreatedDemEvent_ESH_Action_OnEnterPrepShutdown_BswMReportFailToDemRef_1}
        {enable-take-address=true, indirect-api=false, port-defined-argument-value{value=129, value-type=Dem_EventIdType}, port=EvtInfo_AutoCreatedDemEvent_ESH_Action_OnEnterRun_BswMReportFailToDemRef}
        {enable-take-address=true, indirect-api=false, port-defined-argument-value{value=130, value-type=Dem_EventIdType}, port=EvtInfo_AutoCreatedDemEvent_ESH_Action_OnEnterRun_BswMReportFailToDemRef_1}
        {enable-take-address=true, indirect-api=false, port-defined-argument-value{value=131, value-type=Dem_EventIdType}, port=EvtInfo_AutoCreatedDemEvent_ESH_Action_OnEnterShutdown_BswMReportFailToDemRef}
        {enable-take-address=true, indirect-api=false, port-defined-argument-value{value=132, value-type=Dem_EventIdType}, port=EvtInfo_AutoCreatedDemEvent_ESH_Action_OnEnterWaitForNvm_BswMReportFailToDemRef}
        {enable-take-address=true, indirect-api=false, port-defined-argument-value{value=133, value-type=Dem_EventIdType}, port=EvtInfo_AutoCreatedDemEvent_ESH_Action_OnEnterWakeup_BswMReportFailToDemRef}
        {enable-take-address=true, indirect-api=false, port-defined-argument-value{value=134, value-type=Dem_EventIdType}, port=EvtInfo_AutoCreatedDemEvent_ESH_Action_OnEnterWakeup_BswMReportFailToDemRef_1}
        {enable-take-address=true, indirect-api=false, port-defined-argument-value{value=135, value-type=Dem_EventIdType}, port=EvtInfo_AutoCreatedDemEvent_ESH_Action_SelfRunRequestTimer_Start_BswMReportFailToDemRef}
        {enable-take-address=true, indirect-api=false, port-defined-argument-value{value=136, value-type=Dem_EventIdType}, port=EvtInfo_AutoCreatedDemEvent_ESH_Action_SelfRunRequestTimer_Start_BswMReportFailToDemRef_1}
        {enable-take-address=true, indirect-api=false, port-defined-argument-value{value=137, value-type=Dem_EventIdType}, port=EvtInfo_AutoCreatedDemEvent_ESH_Action_SwitchPostRun_BswMReportFailToDemRef}
        {enable-take-address=true, indirect-api=false, port-defined-argument-value{value=138, value-type=Dem_EventIdType}, port=EvtInfo_AutoCreatedDemEvent_ESH_Action_SwitchRun_BswMReportFailToDemRef}
        {enable-take-address=true, indirect-api=false, port-defined-argument-value{value=139, value-type=Dem_EventIdType}, port=EvtInfo_AutoCreatedDemEvent_ESH_Action_SwitchRun_BswMReportFailToDemRef_1}
        {enable-take-address=true, indirect-api=false, port-defined-argument-value{value=140, value-type=Dem_EventIdType}, port=EvtInfo_AutoCreatedDemEvent_ESH_Action_SwitchShutdown_BswMReportFailToDemRef}
        {enable-take-address=true, indirect-api=false, port-defined-argument-value{value=141, value-type=Dem_EventIdType}, port=EvtInfo_AutoCreatedDemEvent_ESH_Action_SwitchShutdown_BswMReportFailToDemRef_1}
        {enable-take-address=true, indirect-api=false, port-defined-argument-value{value=142, value-type=Dem_EventIdType}, port=EvtInfo_AutoCreatedDemEvent_ESH_Action_SwitchWakeup_BswMReportFailToDemRef}
        {enable-take-address=true, indirect-api=false, port-defined-argument-value{value=143, value-type=Dem_EventIdType}, port=EvtInfo_AutoCreatedDemEvent_ESH_Action_SwitchWakeup_BswMReportFailToDemRef_1}
        {enable-take-address=true, indirect-api=false, port-defined-argument-value{value=144, value-type=Dem_EventIdType}, port=EvtInfo_AutoCreatedDemEvent_ESH_Action_WriteAllTimer_Start_BswMReportFailToDemRef}
        {enable-take-address=true, indirect-api=false, port-defined-argument-value{value=145, value-type=Dem_EventIdType}, port=EvtInfo_AutoCreatedDemEvent_ESH_Action_WriteAllTimer_Stop_BswMReportFailToDemRef}
        {enable-take-address=true, indirect-api=false, port-defined-argument-value{value=146, value-type=Dem_EventIdType}, port=EvtInfo_AutoCreatedDemEvent_ESH_Action_WriteAllTimer_Stop_BswMReportFailToDemRef_1}
        {enable-take-address=true, indirect-api=false, port-defined-argument-value{value=147, value-type=Dem_EventIdType}, port=EvtInfo_AutoCreatedDemEvent_ESH_DemInit_BswMReportFailToDemRef}
        {enable-take-address=true, indirect-api=false, port-defined-argument-value{value=148, value-type=Dem_EventIdType}, port=EvtInfo_AutoCreatedDemEvent_ESH_PostRunNested_BswMReportFailToDemRef}
        {enable-take-address=true, indirect-api=false, port-defined-argument-value{value=149, value-type=Dem_EventIdType}, port=EvtInfo_AutoCreatedDemEvent_ESH_PostRunToPrepNested_BswMReportFailToDemRef}
        {enable-take-address=true, indirect-api=false, port-defined-argument-value{value=124, value-type=Dem_EventIdType}, port=EvtInfo_AutoCreatedDemEvent_ESH_Action_ExitExclusiveArea_BswMReportFailToDemRef_1}
        {enable-take-address=true, indirect-api=false, port-defined-argument-value{value=157, value-type=Dem_EventIdType}, port=EvtInfo_AutoCreatedDemEvent_INIT_Action_BrsHw_EnableHwAccess_BswMReportFailToDemRef}
        {enable-take-address=true, indirect-api=false, port-defined-argument-value{value=158, value-type=Dem_EventIdType}, port=EvtInfo_AutoCreatedDemEvent_INIT_Action_CanIf_Init_BswMReportFailToDemRef}
        {enable-take-address=true, indirect-api=false, port-defined-argument-value{value=159, value-type=Dem_EventIdType}, port=EvtInfo_AutoCreatedDemEvent_INIT_Action_CanNm_Init_BswMReportFailToDemRef}
        {enable-take-address=true, indirect-api=false, port-defined-argument-value{value=160, value-type=Dem_EventIdType}, port=EvtInfo_AutoCreatedDemEvent_INIT_Action_CanSM_Init_BswMReportFailToDemRef}
        {enable-take-address=true, indirect-api=false, port-defined-argument-value{value=161, value-type=Dem_EventIdType}, port=EvtInfo_AutoCreatedDemEvent_INIT_Action_CanTp_Init_BswMReportFailToDemRef}
        {enable-take-address=true, indirect-api=false, port-defined-argument-value{value=162, value-type=Dem_EventIdType}, port=EvtInfo_AutoCreatedDemEvent_INIT_Action_Can_Init_BswMReportFailToDemRef}
        {enable-take-address=true, indirect-api=false, port-defined-argument-value{value=163, value-type=Dem_EventIdType}, port=EvtInfo_AutoCreatedDemEvent_INIT_Action_ComM_Init_BswMReportFailToDemRef}
        {enable-take-address=true, indirect-api=false, port-defined-argument-value{value=164, value-type=Dem_EventIdType}, port=EvtInfo_AutoCreatedDemEvent_INIT_Action_Com_Init_BswMReportFailToDemRef}
        {enable-take-address=true, indirect-api=false, port-defined-argument-value{value=165, value-type=Dem_EventIdType}, port=EvtInfo_AutoCreatedDemEvent_INIT_Action_Dcm_Init_BswMReportFailToDemRef}
        {enable-take-address=true, indirect-api=false, port-defined-argument-value{value=166, value-type=Dem_EventIdType}, port=EvtInfo_AutoCreatedDemEvent_INIT_Action_Dem_Init_BswMReportFailToDemRef}
        {enable-take-address=true, indirect-api=false, port-defined-argument-value{value=167, value-type=Dem_EventIdType}, port=EvtInfo_AutoCreatedDemEvent_INIT_Action_EnableInterrupts_BswMReportFailToDemRef}
        {enable-take-address=true, indirect-api=false, port-defined-argument-value{value=168, value-type=Dem_EventIdType}, port=EvtInfo_AutoCreatedDemEvent_INIT_Action_Fee_Init_BswMReportFailToDemRef}
        {enable-take-address=true, indirect-api=false, port-defined-argument-value{value=169, value-type=Dem_EventIdType}, port=EvtInfo_AutoCreatedDemEvent_INIT_Action_Issm_Init_BswMReportFailToDemRef}
        {enable-take-address=true, indirect-api=false, port-defined-argument-value{value=170, value-type=Dem_EventIdType}, port=EvtInfo_AutoCreatedDemEvent_INIT_Action_J1939Nm_Init_BswMReportFailToDemRef}
        {enable-take-address=true, indirect-api=false, port-defined-argument-value{value=171, value-type=Dem_EventIdType}, port=EvtInfo_AutoCreatedDemEvent_INIT_Action_J1939Rm_Init_BswMReportFailToDemRef}
        {enable-take-address=true, indirect-api=false, port-defined-argument-value{value=172, value-type=Dem_EventIdType}, port=EvtInfo_AutoCreatedDemEvent_INIT_Action_J1939Tp_Init_BswMReportFailToDemRef}
        {enable-take-address=true, indirect-api=false, port-defined-argument-value{value=173, value-type=Dem_EventIdType}, port=EvtInfo_AutoCreatedDemEvent_INIT_Action_LinIf_Init_BswMReportFailToDemRef}
        {enable-take-address=true, indirect-api=false, port-defined-argument-value{value=174, value-type=Dem_EventIdType}, port=EvtInfo_AutoCreatedDemEvent_INIT_Action_LinSM_Init_BswMReportFailToDemRef}
        {enable-take-address=true, indirect-api=false, port-defined-argument-value{value=175, value-type=Dem_EventIdType}, port=EvtInfo_AutoCreatedDemEvent_INIT_Action_LinTp_Init_BswMReportFailToDemRef}
        {enable-take-address=true, indirect-api=false, port-defined-argument-value{value=176, value-type=Dem_EventIdType}, port=EvtInfo_AutoCreatedDemEvent_INIT_Action_Lin_Init_BswMReportFailToDemRef}
        {enable-take-address=true, indirect-api=false, port-defined-argument-value{value=177, value-type=Dem_EventIdType}, port=EvtInfo_AutoCreatedDemEvent_INIT_Action_Nm_Init_BswMReportFailToDemRef}
        {enable-take-address=true, indirect-api=false, port-defined-argument-value{value=178, value-type=Dem_EventIdType}, port=EvtInfo_AutoCreatedDemEvent_INIT_Action_NvMReadAll_BswMReportFailToDemRef}
        {enable-take-address=true, indirect-api=false, port-defined-argument-value{value=179, value-type=Dem_EventIdType}, port=EvtInfo_AutoCreatedDemEvent_INIT_Action_NvM_Init_BswMReportFailToDemRef}
        {enable-take-address=true, indirect-api=false, port-defined-argument-value{value=180, value-type=Dem_EventIdType}, port=EvtInfo_AutoCreatedDemEvent_INIT_Action_PduR_Init_BswMReportFailToDemRef}
        {enable-take-address=true, indirect-api=false, port-defined-argument-value{value=181, value-type=Dem_EventIdType}, port=EvtInfo_AutoCreatedDemEvent_INIT_Action_RteStart_BswMReportFailToDemRef}
        {enable-take-address=true, indirect-api=false, port-defined-argument-value{value=60, value-type=Dem_EventIdType}, port=EvtInfo_AutoCreatedDemEvent_CHNL_17344684_CANSM_E_MODE_REQUEST_TIMEOUT}
        {enable-take-address=true, indirect-api=false, port-defined-argument-value{value=59, value-type=Dem_EventIdType}, port=EvtInfo_AutoCreatedDemEvent_CHNL_17344684_CANSM_E_BUS_OFF}
        {enable-take-address=true, indirect-api=false, port-defined-argument-value{value=58, value-type=Dem_EventIdType}, port=EvtInfo_AutoCreatedDemEvent_CHNL_53cce282_CANSM_E_MODE_REQUEST_TIMEOUT}
        {enable-take-address=true, indirect-api=false, port-defined-argument-value{value=57, value-type=Dem_EventIdType}, port=EvtInfo_AutoCreatedDemEvent_CHNL_53cce282_CANSM_E_BUS_OFF}
        {enable-take-address=true, indirect-api=false, port-defined-argument-value{value=62, value-type=Dem_EventIdType}, port=EvtInfo_AutoCreatedDemEvent_CHNL_a6b6a922_CANSM_E_MODE_REQUEST_TIMEOUT}
        {enable-take-address=true, indirect-api=false, port-defined-argument-value{value=61, value-type=Dem_EventIdType}, port=EvtInfo_AutoCreatedDemEvent_CHNL_a6b6a922_CANSM_E_BUS_OFF}
        {enable-take-address=true, indirect-api=false, port-defined-argument-value{value=64, value-type=Dem_EventIdType}, port=EvtInfo_AutoCreatedDemEvent_CHNL_df893ad5_CANSM_E_MODE_REQUEST_TIMEOUT}
        {enable-take-address=true, indirect-api=false, port-defined-argument-value{value=63, value-type=Dem_EventIdType}, port=EvtInfo_AutoCreatedDemEvent_CHNL_df893ad5_CANSM_E_BUS_OFF}
        {enable-take-address=true, indirect-api=false, port-defined-argument-value{value=66, value-type=Dem_EventIdType}, port=EvtInfo_AutoCreatedDemEvent_CHNL_e058b4ae_CANSM_E_MODE_REQUEST_TIMEOUT}
        {enable-take-address=true, indirect-api=false, port-defined-argument-value{value=65, value-type=Dem_EventIdType}, port=EvtInfo_AutoCreatedDemEvent_CHNL_e058b4ae_CANSM_E_BUS_OFF}
        {enable-take-address=true, indirect-api=false, port-defined-argument-value{value=70, value-type=Dem_EventIdType}, port=EvtInfo_AutoCreatedDemEvent_ECUM_E_RAM_CHECK_FAILED}
        {enable-take-address=true, indirect-api=false, port-defined-argument-value{value=69, value-type=Dem_EventIdType}, port=EvtInfo_AutoCreatedDemEvent_ECUM_E_IMPROPER_CALLER}
        {enable-take-address=true, indirect-api=false, port-defined-argument-value{value=68, value-type=Dem_EventIdType}, port=EvtInfo_AutoCreatedDemEvent_ECUM_E_CONFIGURATION_DATA_INCONSISTENT}
        {enable-take-address=true, indirect-api=false, port-defined-argument-value{value=67, value-type=Dem_EventIdType}, port=EvtInfo_AutoCreatedDemEvent_ECUM_E_ALL_RUN_REQUESTS_KILLED}
        {enable-take-address=true, indirect-api=false, port-defined-argument-value{value=155, value-type=Dem_EventIdType}, port=EvtInfo_AutoCreatedDemEvent_FLS_E_WRITE_FAILED}
        {enable-take-address=true, indirect-api=false, port-defined-argument-value{value=154, value-type=Dem_EventIdType}, port=EvtInfo_AutoCreatedDemEvent_FLS_E_UNEXPECTED_FLASH_ID}
        {enable-take-address=true, indirect-api=false, port-defined-argument-value{value=153, value-type=Dem_EventIdType}, port=EvtInfo_AutoCreatedDemEvent_FLS_E_READ_FAILED}
        {enable-take-address=true, indirect-api=false, port-defined-argument-value{value=152, value-type=Dem_EventIdType}, port=EvtInfo_AutoCreatedDemEvent_FLS_E_ERASE_FAILED}
        {enable-take-address=true, indirect-api=false, port-defined-argument-value{value=151, value-type=Dem_EventIdType}, port=EvtInfo_AutoCreatedDemEvent_FLS_E_COMPARE_FAILED}
        {enable-take-address=true, indirect-api=false, port-defined-argument-value{value=156, value-type=Dem_EventIdType}, port=EvtInfo_AutoCreatedDemEvent_GPT_E_TIMEOUT}
        {enable-take-address=true, indirect-api=false, port-defined-argument-value{value=182, value-type=Dem_EventIdType}, port=EvtInfo_AutoCreatedDemEvent_J1939NM_E_ADDRESS_LOST}
        {enable-take-address=true, indirect-api=false, port-defined-argument-value{value=183, value-type=Dem_EventIdType}, port=EvtInfo_AutoCreatedDemEvent_J1939TpConfiguration_J1939TP_E_COMMUNICATION}
        {enable-take-address=true, indirect-api=false, port-defined-argument-value{value=184, value-type=Dem_EventIdType}, port=EvtInfo_AutoCreatedDemEvent_LIN_E_TIMEOUT}
        {enable-take-address=true, indirect-api=false, port-defined-argument-value{value=190, value-type=Dem_EventIdType}, port=EvtInfo_AutoCreatedDemEvent_MCL_E_DMA_UNRECOGNIZED}
        {enable-take-address=true, indirect-api=false, port-defined-argument-value{value=189, value-type=Dem_EventIdType}, port=EvtInfo_AutoCreatedDemEvent_MCL_E_DMA_PRIORITY}
        {enable-take-address=true, indirect-api=false, port-defined-argument-value{value=188, value-type=Dem_EventIdType}, port=EvtInfo_AutoCreatedDemEvent_MCL_E_DMA_INCONSISTENCY}
        {enable-take-address=true, indirect-api=false, port-defined-argument-value{value=187, value-type=Dem_EventIdType}, port=EvtInfo_AutoCreatedDemEvent_MCL_E_DMA_ECC}
        {enable-take-address=true, indirect-api=false, port-defined-argument-value{value=186, value-type=Dem_EventIdType}, port=EvtInfo_AutoCreatedDemEvent_MCL_E_DMA_DESCRIPTOR}
        {enable-take-address=true, indirect-api=false, port-defined-argument-value{value=185, value-type=Dem_EventIdType}, port=EvtInfo_AutoCreatedDemEvent_MCL_E_DMA_BUS}
        {enable-take-address=true, indirect-api=false, port-defined-argument-value{value=194, value-type=Dem_EventIdType}, port=EvtInfo_AutoCreatedDemEvent_MCU_E_TIMEOUT_FAILURE}
        {enable-take-address=true, indirect-api=false, port-defined-argument-value{value=193, value-type=Dem_EventIdType}, port=EvtInfo_AutoCreatedDemEvent_MCU_E_SSCM_CER_FAILURE}
        {enable-take-address=true, indirect-api=false, port-defined-argument-value{value=192, value-type=Dem_EventIdType}, port=EvtInfo_AutoCreatedDemEvent_MCU_E_INVALIDMODE_CONFIG}
        {enable-take-address=true, indirect-api=false, port-defined-argument-value{value=191, value-type=Dem_EventIdType}, port=EvtInfo_AutoCreatedDemEvent_MCU_E_CLOCK_FAILURE}
        {enable-take-address=true, indirect-api=false, port-defined-argument-value{value=201, value-type=Dem_EventIdType}, port=EvtInfo_AutoCreatedDemEvent_NVM_E_WRONG_BLOCK_ID}
        {enable-take-address=true, indirect-api=false, port-defined-argument-value{value=200, value-type=Dem_EventIdType}, port=EvtInfo_AutoCreatedDemEvent_NVM_E_WRITE_PROTECTED}
        {enable-take-address=true, indirect-api=false, port-defined-argument-value{value=199, value-type=Dem_EventIdType}, port=EvtInfo_AutoCreatedDemEvent_NVM_E_VERIFY_FAILED}
        {enable-take-address=true, indirect-api=false, port-defined-argument-value{value=198, value-type=Dem_EventIdType}, port=EvtInfo_AutoCreatedDemEvent_NVM_E_REQ_FAILED}
        {enable-take-address=true, indirect-api=false, port-defined-argument-value{value=197, value-type=Dem_EventIdType}, port=EvtInfo_AutoCreatedDemEvent_NVM_E_QUEUE_OVERFLOW}
        {enable-take-address=true, indirect-api=false, port-defined-argument-value{value=196, value-type=Dem_EventIdType}, port=EvtInfo_AutoCreatedDemEvent_NVM_E_LOSS_OF_REDUNDANCY}
        {enable-take-address=true, indirect-api=false, port-defined-argument-value{value=195, value-type=Dem_EventIdType}, port=EvtInfo_AutoCreatedDemEvent_NVM_E_INTEGRITY_FAILED}
        {enable-take-address=true, indirect-api=false, port-defined-argument-value{value=202, value-type=Dem_EventIdType}, port=EvtInfo_AutoCreatedDemEvent_SPI_E_HARDWARE_ERROR}
        {enable-take-address=true, indirect-api=false, port-defined-argument-value{value=203, value-type=Dem_EventIdType}, port=EvtInfo_AutoCreatedDemEvent_SpiDriver_SPI_E_HARDWARE_ERROR}
        {enable-take-address=true, indirect-api=false, port-defined-argument-value{value=210, value-type=Dem_EventIdType}, port=EvtInfo_AutoCreatedDemEvent_WDG_E_UNLOCKED}
        {enable-take-address=true, indirect-api=false, port-defined-argument-value{value=209, value-type=Dem_EventIdType}, port=EvtInfo_AutoCreatedDemEvent_WDG_E_MODE_FAILED}
        {enable-take-address=true, indirect-api=false, port-defined-argument-value{value=208, value-type=Dem_EventIdType}, port=EvtInfo_AutoCreatedDemEvent_WDG_E_INVALID_PARAMETER}
        {enable-take-address=true, indirect-api=false, port-defined-argument-value{value=207, value-type=Dem_EventIdType}, port=EvtInfo_AutoCreatedDemEvent_WDG_E_INVALID_CALL}
        {enable-take-address=true, indirect-api=false, port-defined-argument-value{value=206, value-type=Dem_EventIdType}, port=EvtInfo_AutoCreatedDemEvent_WDG_E_FORBIDDEN_INVOCATION}
        {enable-take-address=true, indirect-api=false, port-defined-argument-value{value=205, value-type=Dem_EventIdType}, port=EvtInfo_AutoCreatedDemEvent_WDG_E_DISABLE_REJECTED}
        {enable-take-address=true, indirect-api=false, port-defined-argument-value{value=204, value-type=Dem_EventIdType}, port=EvtInfo_AutoCreatedDemEvent_WDG_E_CORRUPT_CONFIG}
        {enable-take-address=true, indirect-api=false, port-defined-argument-value{value=211, value-type=Dem_EventIdType}, port=EvtInfo_DEM_EVENT_StartApplication}
        {enable-take-address=true, indirect-api=false, port-defined-argument-value{value=211, value-type=Dem_EventIdType}, port=Event_DEM_EVENT_StartApplication}
        enable-take-address=true, indirect-api=false, port=DemSatellite_OsApplication_Untrusted_Core0/CBReadData_DemDataElementClass_StartApplication
      15 x runnable:
        Dem_SatelliteMainFunction
          sync call OpServerCallDem_SatelliteMainFunction_ReadData_CBReadData_DemDataElementClass_StartApplication: operation=CBReadData_DemDataElementClass_StartApplication.ReadData, timeout=0
        GetEventUdsStatus: can-be-invoked-concurrently=true, symbol=Dem_GetEventUdsStatus
        GetEventStatus: can-be-invoked-concurrently=true, symbol=Dem_GetEventUdsStatus
        GetEventFailed: can-be-invoked-concurrently=true, symbol=Dem_GetEventFailed
        GetEventTested: can-be-invoked-concurrently=true, symbol=Dem_GetEventTested
        GetDTCOfEvent: can-be-invoked-concurrently=true, symbol=Dem_GetDTCOfEvent
        GetFaultDetectionCounter: can-be-invoked-concurrently=true, symbol=Dem_GetFaultDetectionCounter
        GetEventFreezeFrameDataEx: can-be-invoked-concurrently=true, symbol=Dem_GetEventFreezeFrameDataEx
        GetEventExtendedDataRecordEx: can-be-invoked-concurrently=true, symbol=Dem_GetEventExtendedDataRecordEx
        GetEventEnableCondition: can-be-invoked-concurrently=true, symbol=Dem_GetEventEnableCondition
        GetDebouncingOfEvent: can-be-invoked-concurrently=true, symbol=Dem_GetDebouncingOfEvent
        GetMonitorStatus: can-be-invoked-concurrently=true, symbol=Dem_GetMonitorStatus
        SetEventStatus: can-be-invoked-concurrently=true, symbol=Dem_SetEventStatus
        ResetEventStatus: can-be-invoked-concurrently=true, symbol=Dem_ResetEventStatus
        ResetEventDebounceStatus: can-be-invoked-concurrently=true, symbol=Dem_ResetEventDebounceStatus
  swc implementation DemSatellite_OsApplication_Untrusted_Core0Implementation: programming-language=C, behavior=DemSatellite_OsApplication_Untrusted_Core0InternalBehavior
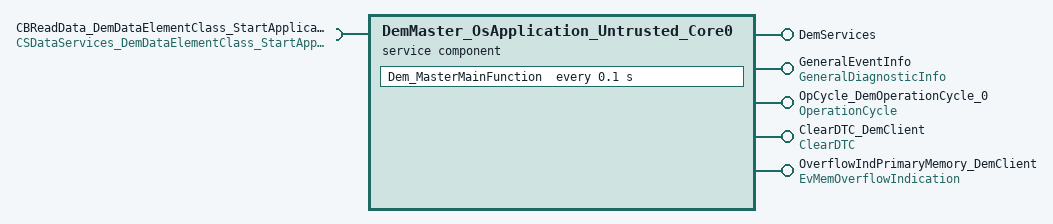
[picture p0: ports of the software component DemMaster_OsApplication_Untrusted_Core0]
  service sw component type DemMaster_OsApplication_Untrusted_Core0: category=SERVICE_COMPONENT
    5 x provide port:
      DemServices: provided-interface=DemServices
      GeneralEventInfo: provided-interface=GeneralDiagnosticInfo
      OpCycle_DemOperationCycle_0: provided-interface=OperationCycle
      ClearDTC_DemClient: provided-interface=ClearDTC
      OverflowIndPrimaryMemory_DemClient: provided-interface=EvMemOverflowIndication
    require port CBReadData_DemDataElementClass_StartApplication: required-interface=CSDataServices_DemDataElementClass_StartApplication
    behavior DemMaster_OsApplication_Untrusted_Core0InternalBehavior: handle-termination-and-restart=NO-SUPPORT, included-data-type-set=data-type=[Dem_EventIdType, Dem_RatioIdType, Dem_EventStatusType, Dem_UdsStatusByteType, Dem_DTCFormatType, Dem_InitMonitorReasonType, Dem_OperationCycleStateType, Dem_DTCStatusMaskType, Dem_IndicatorStatusType, Dem_MaxDataValueType, Dem_DTCKindType, Dem_DTCGroupType, Dem_IumprDenomCondIdType, Dem_IumprDenomCondStatusType, Dem_DebounceResetStatusType, Dem_DebouncingStateType, Dem_IumprReadinessGroupType, Dem_DTRControlType, Dem_DTCSeverityType, Dem_MonitorStatusType]
      timing event Timer_Dem_MasterMainFunction: start-on-event=Dem_MasterMainFunction, period=0.1
      19 x operation invoked event:
        OpEventPostRunRequested_GetPostRunRequested_DemServices: start-on-event=PostRunRequested, operation=DemServices.GetPostRunRequested
        OpEventGetDTCStatusAvailabilityMask_GetDTCStatusAvailabilityMask_DemServices: start-on-event=GetDTCStatusAvailabilityMask, operation=DemServices.GetDTCStatusAvailabilityMask
        OpEventGetEventUdsStatus_GetEventUdsStatus_GeneralEventInfo: start-on-event=DemMaster_OsApplication_Untrusted_Core0InternalBehavior/GetEventUdsStatus, operation=GeneralEventInfo.GetEventUdsStatus
        OpEventGetEventStatus_GetEventStatus_GeneralEventInfo: start-on-event=DemMaster_OsApplication_Untrusted_Core0InternalBehavior/GetEventStatus, operation=GeneralEventInfo.GetEventStatus
        OpEventGetEventFailed_GetEventFailed_GeneralEventInfo: start-on-event=DemMaster_OsApplication_Untrusted_Core0InternalBehavior/GetEventFailed, operation=GeneralEventInfo.GetEventFailed
        OpEventGetEventTested_GetEventTested_GeneralEventInfo: start-on-event=DemMaster_OsApplication_Untrusted_Core0InternalBehavior/GetEventTested, operation=GeneralEventInfo.GetEventTested
        OpEventGetDTCOfEvent_GetDTCOfEvent_GeneralEventInfo: start-on-event=DemMaster_OsApplication_Untrusted_Core0InternalBehavior/GetDTCOfEvent, operation=GeneralEventInfo.GetDTCOfEvent
        OpEventGetFaultDetectionCounter_GetFaultDetectionCounter_GeneralEventInfo: start-on-event=DemMaster_OsApplication_Untrusted_Core0InternalBehavior/GetFaultDetectionCounter, operation=GeneralEventInfo.GetFaultDetectionCounter
        OpEventGetEventFreezeFrameDataEx_GetEventFreezeFrameDataEx_GeneralEventInfo: start-on-event=DemMaster_OsApplication_Untrusted_Core0InternalBehavior/GetEventFreezeFrameDataEx, operation=GeneralEventInfo.GetEventFreezeFrameDataEx
        OpEventGetEventExtendedDataRecordEx_GetEventExtendedDataRecordEx_GeneralEventInfo: start-on-event=DemMaster_OsApplication_Untrusted_Core0InternalBehavior/GetEventExtendedDataRecordEx, operation=GeneralEventInfo.GetEventExtendedDataRecordEx
        OpEventGetEventEnableCondition_GetEventEnableCondition_GeneralEventInfo: start-on-event=DemMaster_OsApplication_Untrusted_Core0InternalBehavior/GetEventEnableCondition, operation=GeneralEventInfo.GetEventEnableCondition
        OpEventGetDebouncingOfEvent_GetDebouncingOfEvent_GeneralEventInfo: start-on-event=DemMaster_OsApplication_Untrusted_Core0InternalBehavior/GetDebouncingOfEvent, operation=GeneralEventInfo.GetDebouncingOfEvent
        OpEventGetMonitorStatus_GetMonitorStatus_GeneralEventInfo: start-on-event=DemMaster_OsApplication_Untrusted_Core0InternalBehavior/GetMonitorStatus, operation=GeneralEventInfo.GetMonitorStatus
        OpEventGetOperationCycleState_GetOperationCycleState_OpCycle_DemOperationCycle_0: start-on-event=GetOperationCycleState, operation=OpCycle_DemOperationCycle_0.GetOperationCycleState
        OpEventSetOperationCycleState_SetOperationCycleState_OpCycle_DemOperationCycle_0: start-on-event=SetOperationCycleState, operation=OpCycle_DemOperationCycle_0.SetOperationCycleState
        OpEventClearDTC_ClearDTC_ClearDTC_DemClient: start-on-event=ClearDTC, operation=ClearDTC_DemClient.ClearDTC
        OpEventSelectDTC_SelectDTC_ClearDTC_DemClient: start-on-event=SelectDTC, operation=ClearDTC_DemClient.SelectDTC
        OpEventGetEventMemoryOverflow_GetEventMemoryOverflow_OverflowIndPrimaryMemory_DemClient: start-on-event=GetEventMemoryOverflow, operation=OverflowIndPrimaryMemory_DemClient.GetEventMemoryOverflow
        OpEventGetNumberOfEventMemoryEntries_GetNumberOfEventMemoryEntries_OverflowIndPrimaryMemory_DemClient: start-on-event=GetNumberOfEventMemoryEntries, operation=OverflowIndPrimaryMemory_DemClient.GetNumberOfEventMemoryEntries
      port-api-options:
        enable-take-address=true, indirect-api=false, port=DemServices
        enable-take-address=true, indirect-api=false, port=DemMaster_OsApplication_Untrusted_Core0/GeneralEventInfo
        {enable-take-address=true, indirect-api=false, port-defined-argument-value{value=0, value-type=Dem_OperationCycleIdType}, port=OpCycle_DemOperationCycle_0}
        {enable-take-address=true, indirect-api=false, port-defined-argument-value{value=0, value-type=uint8}, port=ClearDTC_DemClient}
        {enable-take-address=true, indirect-api=false, port-arg-values=[{value=0, value-type=uint8}, {value=1, value-type=Dem_DTCOriginType}], port=OverflowIndPrimaryMemory_DemClient}
        enable-take-address=true, indirect-api=false, port=DemMaster_OsApplication_Untrusted_Core0/CBReadData_DemDataElementClass_StartApplication
      20 x runnable:
        Dem_MasterMainFunction
          sync call OpServerCallDem_MasterMainFunction_ReadData_CBReadData_DemDataElementClass_StartApplication: operation=CBReadData_DemDataElementClass_StartApplication.ReadData, timeout=0
        PostRunRequested: can-be-invoked-concurrently=true, symbol=Dem_PostRunRequested
        GetDTCStatusAvailabilityMask: can-be-invoked-concurrently=true, symbol=Dem_GetDTCStatusAvailabilityMask
        GetEventUdsStatus: can-be-invoked-concurrently=true, symbol=Dem_GetEventUdsStatus
        GetEventStatus: can-be-invoked-concurrently=true, symbol=Dem_GetEventUdsStatus
        GetEventFailed: can-be-invoked-concurrently=true, symbol=Dem_GetEventFailed
        GetEventTested: can-be-invoked-concurrently=true, symbol=Dem_GetEventTested
        GetDTCOfEvent: can-be-invoked-concurrently=true, symbol=Dem_GetDTCOfEvent
        GetFaultDetectionCounter: can-be-invoked-concurrently=true, symbol=Dem_GetFaultDetectionCounter
        GetEventFreezeFrameDataEx: can-be-invoked-concurrently=true, symbol=Dem_GetEventFreezeFrameDataEx
        GetEventExtendedDataRecordEx: can-be-invoked-concurrently=true, symbol=Dem_GetEventExtendedDataRecordEx
        GetEventEnableCondition: can-be-invoked-concurrently=true, symbol=Dem_GetEventEnableCondition
        GetDebouncingOfEvent: can-be-invoked-concurrently=true, symbol=Dem_GetDebouncingOfEvent
        GetMonitorStatus: can-be-invoked-concurrently=true, symbol=Dem_GetMonitorStatus
        GetOperationCycleState: can-be-invoked-concurrently=true, symbol=Dem_GetOperationCycleState
        SetOperationCycleState: can-be-invoked-concurrently=true, symbol=Dem_SetOperationCycleState
        ClearDTC: can-be-invoked-concurrently=true, symbol=Dem_ClearDTC
        SelectDTC: can-be-invoked-concurrently=true, symbol=Dem_SelectDTC
        GetEventMemoryOverflow: can-be-invoked-concurrently=true, symbol=Dem_GetEventMemoryOverflow
        GetNumberOfEventMemoryEntries: can-be-invoked-concurrently=true, symbol=Dem_GetNumberOfEventMemoryEntries
  swc implementation DemMaster_OsApplication_Untrusted_Core0Implementation: programming-language=C, behavior=DemMaster_OsApplication_Untrusted_Core0InternalBehavior
